AUTOSAR XML (schema 4-2-2)
package /RootP_ASWC_A28
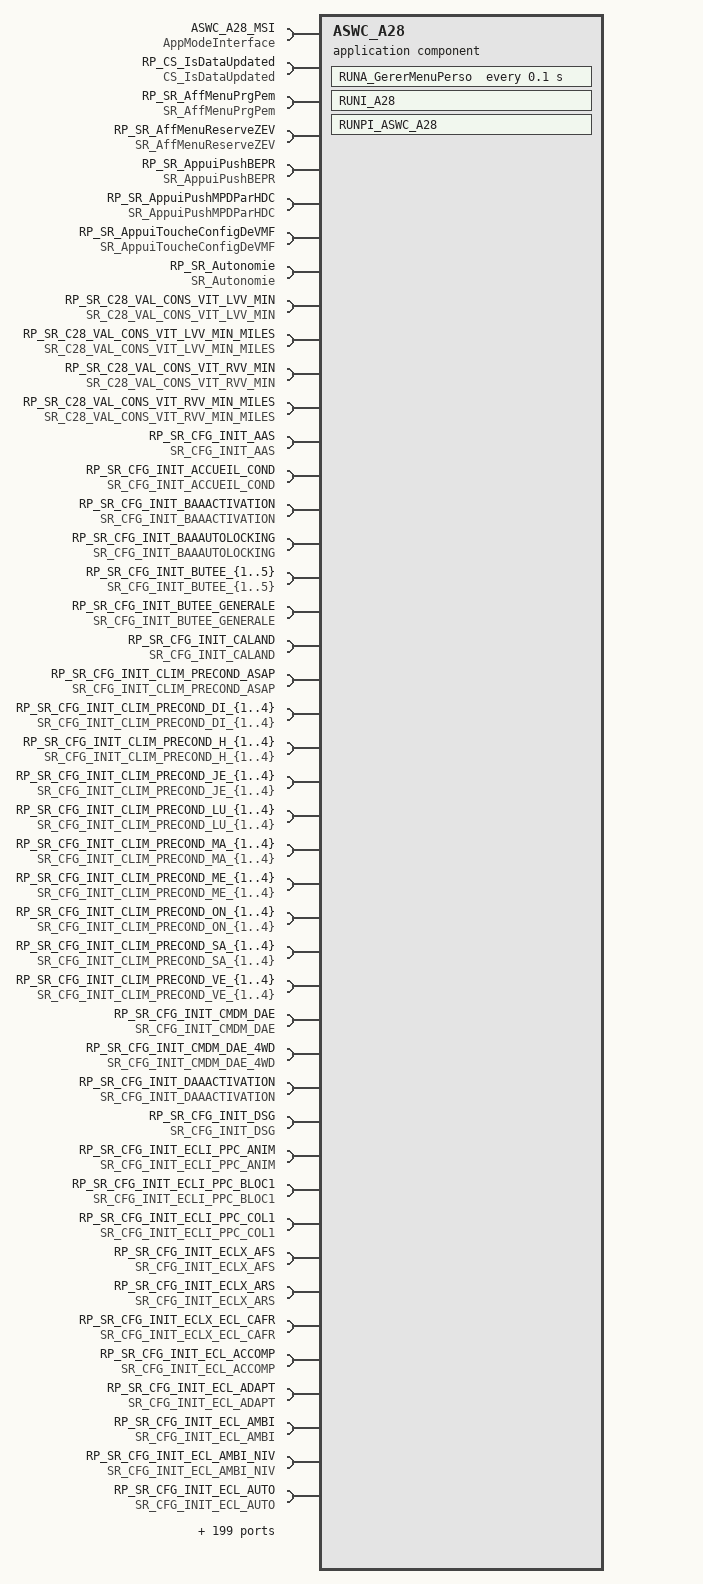
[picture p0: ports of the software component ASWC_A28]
  application sw component type ASWC_A28
    require port ASWC_A28_MSI: required-interface=AppModeInterface
    278 x provide/require port:
      PRP_SR_ButeeXvv{1..5}DeMenuPerso: nonqueued-receiver-com-spec{data-element=ButeeXvv{1..5}DeMenuPerso, handle-data-status=true, init-value=CONST_tBYTE_0:0}, provided-required-interface=SR_ButeeXvv{1..5}DeMenuPerso
      PRP_SR_DdeAccesJDADeVMF: nonqueued-receiver-com-spec{data-element=DdeAccesJDADeVMF, handle-data-status=true, init-value=CONST_tLOG_0:0}, provided-required-interface=SR_DdeAccesJDADeVMF
      PRP_SR_DdeAllumPlafDeVMF: nonqueued-receiver-com-spec{data-element=DdeAllumPlafDeVMF, handle-data-status=true, init-value=CONST_tLOG_0:0}, provided-required-interface=SR_DdeAllumPlafDeVMF
      PRP_SR_DdeBlackPanelDeVMF: nonqueued-receiver-com-spec{data-element=DdeBlackPanelDeVMF, handle-data-status=true, init-value=CONST_tLOG_0:0}, provided-required-interface=SR_DdeBlackPanelDeVMF
      PRP_SR_DdeCheckTcfg: nonqueued-receiver-com-spec{data-element=DdeCheckTcfg, handle-data-status=true, init-value=CONST_tLOG_0:0}, provided-required-interface=SR_DdeCheckTcfg
      PRP_SR_DdeColorisationCMBDeVMF: nonqueued-receiver-com-spec{data-element=DdeColorisationCMBDeVMF, handle-data-status=true, init-value=CONST_tLOG_0:0}, provided-required-interface=SR_DdeColorisationCMBDeVMF
      PRP_SR_DdeConfigToucheDeVMF: nonqueued-receiver-com-spec{data-element=DdeConfigToucheDeVMF, handle-data-status=true, init-value=CONST_tLOG_0:0}, provided-required-interface=SR_DdeConfigToucheDeVMF
      PRP_SR_DdePersoCMBDeVMF: nonqueued-receiver-com-spec{data-element=DdePersoCMBDeVMF, handle-data-status=true, init-value=CONST_tLOG_0:0}, provided-required-interface=SR_DdePersoCMBDeVMF
      PRP_SR_DispoDmdMenuPrecond: nonqueued-receiver-com-spec{data-element=DispoDmdMenuPrecond, handle-data-status=true, init-value=CONST_tWORD_0:0}, provided-required-interface=SR_DispoDmdMenuPrecond
      PRP_SR_DispoDmdMenuRecharge: nonqueued-receiver-com-spec{data-element=DispoDmdMenuRecharge, handle-data-status=true, init-value=CONST_tBYTE_0b01:0b01}, provided-required-interface=SR_DispoDmdMenuRecharge
      PRP_SR_DispoEtatMenuPrgPem: nonqueued-receiver-com-spec{data-element=DispoEtatMenuPrgPem, handle-data-status=true, init-value=CONST_tLOG_0:0}, provided-required-interface=SR_DispoEtatMenuPrgPem
      PRP_SR_DispoEtatMenuReserveZEV: nonqueued-receiver-com-spec{data-element=DispoEtatMenuReserveZEV, handle-data-status=true, init-value=CONST_tLOG_0:0}, provided-required-interface=SR_DispoEtatMenuReserveZEV
      PRP_SR_DmdMenuSelPrgDi: nonqueued-receiver-com-spec{data-element=DmdMenuSelPrgDi, handle-data-status=true, init-value=CONST_tLOG_0:0}, provided-required-interface=SR_DmdMenuSelPrgDi
      PRP_SR_DmdMenuSelPrgJe: nonqueued-receiver-com-spec{data-element=DmdMenuSelPrgJe, handle-data-status=true, init-value=CONST_tLOG_0:0}, provided-required-interface=SR_DmdMenuSelPrgJe
      PRP_SR_DmdMenuSelPrgLu: nonqueued-receiver-com-spec{data-element=DmdMenuSelPrgLu, handle-data-status=true, init-value=CONST_tLOG_0:0}, provided-required-interface=SR_DmdMenuSelPrgLu
      PRP_SR_DmdMenuSelPrgMa: nonqueued-receiver-com-spec{data-element=DmdMenuSelPrgMa, handle-data-status=true, init-value=CONST_tLOG_0:0}, provided-required-interface=SR_DmdMenuSelPrgMa
      PRP_SR_DmdMenuSelPrgMe: nonqueued-receiver-com-spec{data-element=DmdMenuSelPrgMe, handle-data-status=true, init-value=CONST_tLOG_0:0}, provided-required-interface=SR_DmdMenuSelPrgMe
      PRP_SR_DmdMenuSelPrgSa: nonqueued-receiver-com-spec{data-element=DmdMenuSelPrgSa, handle-data-status=true, init-value=CONST_tLOG_0:0}, provided-required-interface=SR_DmdMenuSelPrgSa
      PRP_SR_DmdMenuSelPrgVe: nonqueued-receiver-com-spec{data-element=DmdMenuSelPrgVe, handle-data-status=true, init-value=CONST_tLOG_0:0}, provided-required-interface=SR_DmdMenuSelPrgVe
      PRP_SR_DmdmCGEPVReserveZEV: nonqueued-receiver-com-spec{data-element=DmdmCGEPVReserveZEV, handle-data-status=true, init-value=CONST_tLOG_0:0}, provided-required-interface=SR_DmdmCGEPVReserveZEV
      PRP_SR_DmdmPrgHcEnd: nonqueued-receiver-com-spec{data-element=DmdmPrgHcEnd, handle-data-status=true, init-value=CONST_tDWORD_0:0}, provided-required-interface=SR_DmdmPrgHcEnd
      PRP_SR_DmdmPrgHcStart: nonqueued-receiver-com-spec{data-element=DmdmPrgHcStart, handle-data-status=true, init-value=CONST_tDWORD_0:0}, provided-required-interface=SR_DmdmPrgHcStart
      PRP_SR_DmdmPrgPemDi: nonqueued-receiver-com-spec{data-element=DmdmPrgPemDi, handle-data-status=true, init-value=CONST_tDWORD_0:0}, provided-required-interface=SR_DmdmPrgPemDi
      PRP_SR_DmdmPrgPemJe: nonqueued-receiver-com-spec{data-element=DmdmPrgPemJe, handle-data-status=true, init-value=CONST_tDWORD_0:0}, provided-required-interface=SR_DmdmPrgPemJe
      PRP_SR_DmdmPrgPemLu: nonqueued-receiver-com-spec{data-element=DmdmPrgPemLu, handle-data-status=true, init-value=CONST_tDWORD_0:0}, provided-required-interface=SR_DmdmPrgPemLu
      PRP_SR_DmdmPrgPemMa: nonqueued-receiver-com-spec{data-element=DmdmPrgPemMa, handle-data-status=true, init-value=CONST_tDWORD_0:0}, provided-required-interface=SR_DmdmPrgPemMa
      PRP_SR_DmdmPrgPemMe: nonqueued-receiver-com-spec{data-element=DmdmPrgPemMe, handle-data-status=true, init-value=CONST_tDWORD_0:0}, provided-required-interface=SR_DmdmPrgPemMe
      PRP_SR_DmdmPrgPemSa: nonqueued-receiver-com-spec{data-element=DmdmPrgPemSa, handle-data-status=true, init-value=CONST_tDWORD_0:0}, provided-required-interface=SR_DmdmPrgPemSa
      PRP_SR_DmdmPrgPemVe: nonqueued-receiver-com-spec{data-element=DmdmPrgPemVe, handle-data-status=true, init-value=CONST_tDWORD_0:0}, provided-required-interface=SR_DmdmPrgPemVe
      PRP_SR_EclAccompDeMenuPerso: nonqueued-receiver-com-spec{data-element=EclAccompDeMenuPerso, handle-data-status=true, init-value=CONST_t_cAccomp_0:0}, provided-required-interface=SR_EclAccompDeMenuPerso
      PRP_SR_EclDecondaDeMenuPerso: nonqueued-receiver-com-spec{data-element=EclDecondaDeMenuPerso, handle-data-status=true, init-value=CONST_t_cDeconda_0:0}, provided-required-interface=SR_EclDecondaDeMenuPerso
      PRP_SR_EtatMenuARCSensNiv: nonqueued-receiver-com-spec{data-element=EtatMenuARCSensNiv, handle-data-status=true, init-value=CONST_tBILOG_2:2}, provided-required-interface=SR_EtatMenuARCSensNiv
      PRP_SR_EtatMenuAccueilCond: nonqueued-receiver-com-spec{data-element=EtatMenuAccueilCond, handle-data-status=true, init-value=CONST_tLOG_0:0}, provided-required-interface=SR_EtatMenuAccueilCond
      PRP_SR_EtatMenuActButee{1..5}XVV: nonqueued-receiver-com-spec{data-element=EtatMenuActButee{1..5}XVV, handle-data-status=true, init-value=CONST_tLOG_0:0}, provided-required-interface=SR_EtatMenuActButee{1..5}XVV
      PRP_SR_EtatMenuActButeeGenXVV: nonqueued-receiver-com-spec{data-element=EtatMenuActButeeGenXVV, handle-data-status=true, init-value=CONST_tLOG_0:0}, provided-required-interface=SR_EtatMenuActButeeGenXVV
      PRP_SR_EtatMenuBAAActivation: nonqueued-receiver-com-spec{data-element=EtatMenuBAAActivation, handle-data-status=true, init-value=CONST_tLOG_0:0}, provided-required-interface=SR_EtatMenuBAAActivation
      PRP_SR_EtatMenuBAAAutolocking: nonqueued-receiver-com-spec{data-element=EtatMenuBAAAutolocking, handle-data-status=true, init-value=CONST_tLOG_0:0}, provided-required-interface=SR_EtatMenuBAAAutolocking
      PRP_SR_EtatMenuCLIM_PrecondASAP: nonqueued-receiver-com-spec{data-element=EtatMenuCLIM_PrecondASAP, handle-data-status=true, init-value=CONST_tLOG_0:0}, provided-required-interface=SR_EtatMenuCLIM_PrecondASAP
      PRP_SR_EtatMenuCLIM_PrecondDi{1..4}: nonqueued-receiver-com-spec{data-element=EtatMenuCLIM_PrecondDi{1..4}, handle-data-status=true, init-value=CONST_tLOG_0:0}, provided-required-interface=SR_EtatMenuCLIM_PrecondDi{1..4}
      PRP_SR_EtatMenuCLIM_PrecondH{1..4}: nonqueued-receiver-com-spec{data-element=EtatMenuCLIM_PrecondH{1..4}, handle-data-status=true, init-value=CONST_tWORD_0:0}, provided-required-interface=SR_EtatMenuCLIM_PrecondH{1..4}
      PRP_SR_EtatMenuCLIM_PrecondJe{1..4}: nonqueued-receiver-com-spec{data-element=EtatMenuCLIM_PrecondJe{1..4}, handle-data-status=true, init-value=CONST_tLOG_0:0}, provided-required-interface=SR_EtatMenuCLIM_PrecondJe{1..4}
      PRP_SR_EtatMenuCLIM_PrecondLu{1..4}: nonqueued-receiver-com-spec{data-element=EtatMenuCLIM_PrecondLu{1..4}, handle-data-status=true, init-value=CONST_tLOG_0:0}, provided-required-interface=SR_EtatMenuCLIM_PrecondLu{1..4}
      PRP_SR_EtatMenuCLIM_PrecondMa{1..4}: nonqueued-receiver-com-spec{data-element=EtatMenuCLIM_PrecondMa{1..4}, handle-data-status=true, init-value=CONST_tLOG_0:0}, provided-required-interface=SR_EtatMenuCLIM_PrecondMa{1..4}
      PRP_SR_EtatMenuCLIM_PrecondMe{1..4}: nonqueued-receiver-com-spec{data-element=EtatMenuCLIM_PrecondMe{1..4}, handle-data-status=true, init-value=CONST_tLOG_0:0}, provided-required-interface=SR_EtatMenuCLIM_PrecondMe{1..4}
      PRP_SR_EtatMenuCLIM_PrecondOn{1..4}: nonqueued-receiver-com-spec{data-element=EtatMenuCLIM_PrecondOn{1..4}, handle-data-status=true, init-value=CONST_tLOG_0:0}, provided-required-interface=SR_EtatMenuCLIM_PrecondOn{1..4}
      PRP_SR_EtatMenuCLIM_PrecondSa{1..4}: nonqueued-receiver-com-spec{data-element=EtatMenuCLIM_PrecondSa{1..4}, handle-data-status=true, init-value=CONST_tLOG_0:0}, provided-required-interface=SR_EtatMenuCLIM_PrecondSa{1..4}
      PRP_SR_EtatMenuCLIM_PrecondVe{1..4}: nonqueued-receiver-com-spec{data-element=EtatMenuCLIM_PrecondVe{1..4}, handle-data-status=true, init-value=CONST_tLOG_0:0}, provided-required-interface=SR_EtatMenuCLIM_PrecondVe{1..4}
      PRP_SR_EtatMenuDAAActivation: nonqueued-receiver-com-spec{data-element=EtatMenuDAAActivation, handle-data-status=true, init-value=CONST_tLOG_0:0}, provided-required-interface=SR_EtatMenuDAAActivation
      PRP_SR_EtatMenuDSG: nonqueued-receiver-com-spec{data-element=EtatMenuDSG, handle-data-status=true, init-value=CONST_tLOG_0:0}, provided-required-interface=SR_EtatMenuDSG
      PRP_SR_EtatMenuECLI_PPC_ANIM: nonqueued-receiver-com-spec{data-element=EtatMenuECLI_PPC_ANIM, handle-data-status=true, init-value=CONST_tBYTE_0:0}, provided-required-interface=SR_EtatMenuECLI_PPC_ANIM
      PRP_SR_EtatMenuECLI_PPC_BLOC1: nonqueued-receiver-com-spec{data-element=EtatMenuECLI_PPC_BLOC1, handle-data-status=true, init-value=CONST_tLOG_0:0}, provided-required-interface=SR_EtatMenuECLI_PPC_BLOC1
      PRP_SR_EtatMenuECLI_PPC_COL1: nonqueued-receiver-com-spec{data-element=EtatMenuECLI_PPC_COL1, handle-data-status=true, init-value=CONST_tBYTE_0:0}, provided-required-interface=SR_EtatMenuECLI_PPC_COL1
      PRP_SR_EtatMenuECLX_AFS: nonqueued-receiver-com-spec{data-element=EtatMenuECLX_AFS, handle-data-status=true, init-value=CONST_tLOG_0:0}, provided-required-interface=SR_EtatMenuECLX_AFS
      PRP_SR_EtatMenuECLX_ARS: nonqueued-receiver-com-spec{data-element=EtatMenuECLX_ARS, handle-data-status=true, init-value=CONST_tLOG_0:0}, provided-required-interface=SR_EtatMenuECLX_ARS
      PRP_SR_EtatMenuECLX_ECL_CAFR: nonqueued-receiver-com-spec{data-element=EtatMenuECLX_ECL_CAFR, handle-data-status=true, init-value=CONST_tLOG_0:0}, provided-required-interface=SR_EtatMenuECLX_ECL_CAFR
      PRP_SR_EtatMenuEclAccomp: nonqueued-receiver-com-spec{data-element=EtatMenuEclAccomp, handle-data-status=true, init-value=CONST_tLOG_0:0}, provided-required-interface=SR_EtatMenuEclAccomp
      PRP_SR_EtatMenuEclAccompTempo: nonqueued-receiver-com-spec{data-element=EtatMenuEclAccompTempo, handle-data-status=true, init-value=CONST_tBILOG_0:0}, provided-required-interface=SR_EtatMenuEclAccompTempo
      PRP_SR_EtatMenuEclAdapt: nonqueued-receiver-com-spec{data-element=EtatMenuEclAdapt, handle-data-status=true, init-value=CONST_tLOG_0:0}, provided-required-interface=SR_EtatMenuEclAdapt
      PRP_SR_EtatMenuEclAmbi: nonqueued-receiver-com-spec{data-element=EtatMenuEclAmbi, handle-data-status=true, init-value=CONST_tLOG_0:0}, provided-required-interface=SR_EtatMenuEclAmbi
      PRP_SR_EtatMenuEclAmbiNiv: nonqueued-receiver-com-spec{data-element=EtatMenuEclAmbiNiv, handle-data-status=true, init-value=CONST_tBYTE_6:6}, provided-required-interface=SR_EtatMenuEclAmbiNiv
      PRP_SR_EtatMenuEclAuto: nonqueued-receiver-com-spec{data-element=EtatMenuEclAuto, handle-data-status=true, init-value=CONST_tLOG_0:0}, provided-required-interface=SR_EtatMenuEclAuto
      PRP_SR_EtatMenuEclAutoroute: nonqueued-receiver-com-spec{data-element=EtatMenuEclAutoroute, handle-data-status=true, init-value=CONST_tLOG_0:0}, provided-required-interface=SR_EtatMenuEclAutoroute
      PRP_SR_EtatMenuEclCaland: nonqueued-receiver-com-spec{data-element=EtatMenuEclCaland, handle-data-status=true, init-value=CONST_tLOG_0:0}, provided-required-interface=SR_EtatMenuEclCaland
      PRP_SR_EtatMenuEclDeconda: nonqueued-receiver-com-spec{data-element=EtatMenuEclDeconda, handle-data-status=true, init-value=CONST_tLOG_0:0}, provided-required-interface=SR_EtatMenuEclDeconda
      PRP_SR_EtatMenuEclDecondaTempo: nonqueued-receiver-com-spec{data-element=EtatMenuEclDecondaTempo, handle-data-status=true, init-value=CONST_tBILOG_0:0}, provided-required-interface=SR_EtatMenuEclDecondaTempo
      PRP_SR_EtatMenuEssuiVitMar: nonqueued-receiver-com-spec{data-element=EtatMenuEssuiVitMar, handle-data-status=true, init-value=CONST_tLOG_0:0}, provided-required-interface=SR_EtatMenuEssuiVitMar
      PRP_SR_EtatMenuFARC: nonqueued-receiver-com-spec{data-element=EtatMenuFARC, handle-data-status=true, init-value=CONST_tLOG_0:0}, provided-required-interface=SR_EtatMenuFARC
      PRP_SR_EtatMenuFSEAuto: nonqueued-receiver-com-spec{data-element=EtatMenuFSEAuto, handle-data-status=true, init-value=CONST_tLOG_0:0}, provided-required-interface=SR_EtatMenuFSEAuto
      PRP_SR_EtatMenuFeuxDiurne: nonqueued-receiver-com-spec{data-element=EtatMenuFeuxDiurne, handle-data-status=true, init-value=CONST_tLOG_0:0}, provided-required-interface=SR_EtatMenuFeuxDiurne
      PRP_SR_EtatMenuGAV_AMLA: nonqueued-receiver-com-spec{data-element=EtatMenuGAV_AMLA, handle-data-status=true, init-value=CONST_tLOG_0:0}, provided-required-interface=SR_EtatMenuGAV_AMLA
      PRP_SR_EtatMenuILV: nonqueued-receiver-com-spec{data-element=EtatMenuILV, handle-data-status=true, init-value=CONST_tLOG_0:0}, provided-required-interface=SR_EtatMenuILV
      PRP_SR_EtatMenuILV_ETSR: nonqueued-receiver-com-spec{data-element=EtatMenuILV_ETSR, handle-data-status=true, init-value=CONST_tLOG_0:0}, provided-required-interface=SR_EtatMenuILV_ETSR
      PRP_SR_EtatMenuIMA: nonqueued-receiver-com-spec{data-element=EtatMenuIMA, handle-data-status=true, init-value=CONST_tLOG_0:0}, provided-required-interface=SR_EtatMenuIMA
      PRP_SR_EtatMenuINV_ADSD: nonqueued-receiver-com-spec{data-element=EtatMenuINV_ADSD, handle-data-status=true, init-value=CONST_tLOG_0:0}, provided-required-interface=SR_EtatMenuINV_ADSD
      PRP_SR_EtatMenuInfoParamDispo: nonqueued-receiver-com-spec{data-element=EtatMenuInfoParamDispo, handle-data-status=true, init-value=CONST_tLOG_0:0}, provided-required-interface=SR_EtatMenuInfoParamDispo
      PRP_SR_EtatMenuInfoUniteLangueDispo: nonqueued-receiver-com-spec{data-element=EtatMenuInfoUniteLangueDispo, handle-data-status=true, init-value=CONST_tLOG_0:0}, provided-required-interface=SR_EtatMenuInfoUniteLangueDispo
      PRP_SR_EtatMenuInfoVitLvvDispo: nonqueued-receiver-com-spec{data-element=EtatMenuInfoVitLvvDispo, handle-data-status=true, init-value=CONST_tLOG_0:0}, provided-required-interface=SR_EtatMenuInfoVitLvvDispo
      PRP_SR_EtatMenuInfoVitRvvDispo: nonqueued-receiver-com-spec{data-element=EtatMenuInfoVitRvvDispo, handle-data-status=true, init-value=CONST_tLOG_0:0}, provided-required-interface=SR_EtatMenuInfoVitRvvDispo
      PRP_SR_EtatMenuInfoXVVDispo: nonqueued-receiver-com-spec{data-element=EtatMenuInfoXVVDispo, handle-data-status=true, init-value=CONST_tLOG_0:0}, provided-required-interface=SR_EtatMenuInfoXVVDispo
      PRP_SR_EtatMenuLangueVehicule: nonqueued-receiver-com-spec{data-element=EtatMenuLangueVehicule, handle-data-status=true, init-value=CONST_tBYTE_0:0}, provided-required-interface=SR_EtatMenuLangueVehicule
      PRP_SR_EtatMenuMotoVolAr: nonqueued-receiver-com-spec{data-element=EtatMenuMotoVolAr, handle-data-status=true, init-value=CONST_tLOG_0:0}, provided-required-interface=SR_EtatMenuMotoVolAr
      PRP_SR_EtatMenuPRV_MODE: nonqueued-receiver-com-spec{data-element=EtatMenuPRV_MODE, handle-data-status=true, init-value=CONST_tBYTE_0:0}, provided-required-interface=SR_EtatMenuPRV_MODE
      PRP_SR_EtatMenuPresenceARC: nonqueued-receiver-com-spec{data-element=EtatMenuPresenceARC, handle-data-status=true, init-value=CONST_tLOG_0:0}, provided-required-interface=SR_EtatMenuPresenceARC
      PRP_SR_EtatMenuRTAB_EnergyRec: nonqueued-receiver-com-spec{data-element=EtatMenuRTAB_EnergyRec, handle-data-status=true, init-value=CONST_tBYTE_0b01:0b01}, provided-required-interface=SR_EtatMenuRTAB_EnergyRec
      PRP_SR_EtatMenuRTAB_RechargeHDeb: nonqueued-receiver-com-spec{data-element=EtatMenuRTAB_RechargeHDeb, handle-data-status=true, init-value=CONST_tWORD_0:0}, provided-required-interface=SR_EtatMenuRTAB_RechargeHDeb
      PRP_SR_EtatMenuRTAB_TypeRec: nonqueued-receiver-com-spec{data-element=EtatMenuRTAB_TypeRec, handle-data-status=true, init-value=CONST_tLOG_0:0}, provided-required-interface=SR_EtatMenuRTAB_TypeRec
      PRP_SR_EtatMenuReserveZEV: nonqueued-receiver-com-spec{data-element=EtatMenuReserveZEV, handle-data-status=true, init-value=CONST_tLOG_0:0}, provided-required-interface=SR_EtatMenuReserveZEV
      PRP_SR_EtatMenuSelReserveZEV: nonqueued-receiver-com-spec{data-element=EtatMenuSelReserveZEV, handle-data-status=true, init-value=CONST_tLOG_0:0}, provided-required-interface=SR_EtatMenuSelReserveZEV
      PRP_SR_EtatMenuSelecArriere: nonqueued-receiver-com-spec{data-element=EtatMenuSelecArriere, handle-data-status=true, init-value=CONST_tLOG_0:0}, provided-required-interface=SR_EtatMenuSelecArriere
      PRP_SR_EtatMenuSelecCabine: nonqueued-receiver-com-spec{data-element=EtatMenuSelecCabine, handle-data-status=true, init-value=CONST_tLOG_0:0}, provided-required-interface=SR_EtatMenuSelecCabine
      PRP_SR_EtatMenuSelecOuvPlip: nonqueued-receiver-com-spec{data-element=EtatMenuSelecOuvPlip, handle-data-status=true, init-value=CONST_tLOG_0:0}, provided-required-interface=SR_EtatMenuSelecOuvPlip
      PRP_SR_EtatMenuSonPoly: nonqueued-receiver-com-spec{data-element=EtatMenuSonPoly, handle-data-status=true, init-value=CONST_tBILOG_0:0}, provided-required-interface=SR_EtatMenuSonPoly
      PRP_SR_EtatMenuStatusAAS: nonqueued-receiver-com-spec{data-element=EtatMenuStatusAAS, handle-data-status=true, init-value=CONST_tLOG_0:0}, provided-required-interface=SR_EtatMenuStatusAAS
      PRP_SR_EtatMenuStatusSAM: nonqueued-receiver-com-spec{data-element=EtatMenuStatusSAM, handle-data-status=true, init-value=CONST_tLOG_0:0}, provided-required-interface=SR_EtatMenuStatusSAM
      PRP_SR_EtatMenuTCFG: nonqueued-receiver-com-spec{data-element=EtatMenuTCFG, handle-data-status=true, init-value=CONST_tBYTE_0:0}, provided-required-interface=SR_EtatMenuTCFG
      PRP_SR_EtatMenuUniteConso: nonqueued-receiver-com-spec{data-element=EtatMenuUniteConso, handle-data-status=true, init-value=CONST_tLOG_0:0}, provided-required-interface=SR_EtatMenuUniteConso
      PRP_SR_EtatMenuUniteDistance: nonqueued-receiver-com-spec{data-element=EtatMenuUniteDistance, handle-data-status=true, init-value=CONST_tLOG_0:0}, provided-required-interface=SR_EtatMenuUniteDistance
      PRP_SR_EtatMenuUniteTemperature: nonqueued-receiver-com-spec{data-element=EtatMenuUniteTemperature, handle-data-status=true, init-value=CONST_tLOG_0:0}, provided-required-interface=SR_EtatMenuUniteTemperature
      PRP_SR_EtatMenuUniteVolume: nonqueued-receiver-com-spec{data-element=EtatMenuUniteVolume, handle-data-status=true, init-value=CONST_tLOG_0:0}, provided-required-interface=SR_EtatMenuUniteVolume
      PRP_SR_EtatMenuVTOR_IRV: nonqueued-receiver-com-spec{data-element=EtatMenuVTOR_IRV, handle-data-status=true, init-value=CONST_tLOG_0:0}, provided-required-interface=SR_EtatMenuVTOR_IRV
      PRP_SR_EtatMenuVitLvv{1..6}: nonqueued-receiver-com-spec{data-element=EtatMenuVitLvv{1..6}, handle-data-status=true, init-value=CONST_tBYTE_0xFF:255}, provided-required-interface=SR_EtatMenuVitLvv{1..6}
      PRP_SR_EtatMenuVitRvv{1..6}: nonqueued-receiver-com-spec{data-element=EtatMenuVitRvv{1..6}, handle-data-status=true, init-value=CONST_tBYTE_0xFF:255}, provided-required-interface=SR_EtatMenuVitRvv{1..6}
      PRP_SR_EtatMenuVitesse{1..5}XVV: nonqueued-receiver-com-spec{data-element=EtatMenuVitesse{1..5}XVV, handle-data-status=true, init-value=CONST_tBYTE_0:0}, provided-required-interface=SR_EtatMenuVitesse{1..5}XVV
      PRP_SR_S360_Envoi: nonqueued-receiver-com-spec{data-element=S360_Envoi, handle-data-status=true, init-value=CONST_tBILOG_0:0}, provided-required-interface=SR_S360_Envoi
      PRP_SR_S360_OCTET_{1..8}: nonqueued-receiver-com-spec{data-element=S360_OCTET_{1..8}, handle-data-status=true, init-value=CONST_tBYTE_0:0}, provided-required-interface=SR_S360_OCTET_{1..8}
      PRP_SR_S3A0_Recu: nonqueued-receiver-com-spec{data-element=S3A0_Recu, handle-data-status=true, init-value=CONST_tBILOG_0:0}, provided-required-interface=SR_S3A0_Recu
      PRP_SR_SEC_AccueilDeMenuPerso: nonqueued-receiver-com-spec{data-element=SEC_AccueilDeMenuPerso, handle-data-status=true, init-value=CONST_tLOG_0:0}, provided-required-interface=SR_SEC_AccueilDeMenuPerso
      PRP_SR_SEC_ActButee{1..5}XVV: nonqueued-receiver-com-spec{data-element=SEC_ActButee{1..5}XVV, handle-data-status=true, init-value=CONST_tLOG_0:0}, provided-required-interface=SR_SEC_ActButee{1..5}XVV
      PRP_SR_SEC_ActButeeGenXVV: nonqueued-receiver-com-spec{data-element=SEC_ActButeeGenXVV, handle-data-status=true, init-value=CONST_tLOG_0:0}, provided-required-interface=SR_SEC_ActButeeGenXVV
      PRP_SR_SEC_ActivationARCDeMenuPerso: nonqueued-receiver-com-spec{data-element=SEC_ActivationARCDeMenuPerso, handle-data-status=true, init-value=CONST_tLOG_1:1}, provided-required-interface=SR_SEC_ActivationARCDeMenuPerso
      PRP_SR_SEC_BAAActivationDeMenuPerso: nonqueued-receiver-com-spec{data-element=SEC_BAAActivationDeMenuPerso, handle-data-status=true, init-value=CONST_tLOG_0:0}, provided-required-interface=SR_SEC_BAAActivationDeMenuPerso
      PRP_SR_SEC_BAAAutolockingDeMenuPerso: nonqueued-receiver-com-spec{data-element=SEC_BAAAutolockingDeMenuPerso, handle-data-status=true, init-value=CONST_tLOG_0:0}, provided-required-interface=SR_SEC_BAAAutolockingDeMenuPerso
      PRP_SR_SEC_CLIMPrecPrg{1..4}DeMenuPerso: nonqueued-receiver-com-spec{data-element=SEC_CLIMPrecPrg{1..4}DeMenuPerso, handle-data-status=true, init-value=CONST_tWORD_0:0}, provided-required-interface=SR_SEC_CLIMPrecPrg{1..4}DeMenuPerso
      PRP_SR_SEC_CLIMPrecSem{1..4}DeMenuPerso: nonqueued-receiver-com-spec{data-element=SEC_CLIMPrecSem{1..4}DeMenuPerso, handle-data-status=true, init-value=CONST_tBYTE_0:0}, provided-required-interface=SR_SEC_CLIMPrecSem{1..4}DeMenuPerso
      PRP_SR_SEC_CLIM_PrecASAPDeMenuPerso: nonqueued-receiver-com-spec{data-element=SEC_CLIM_PrecASAPDeMenuPerso, handle-data-status=true, init-value=CONST_tLOG_0:0}, provided-required-interface=SR_SEC_CLIM_PrecASAPDeMenuPerso
      PRP_SR_SEC_CLIM_PrecH{1..4}DeMenuPerso: nonqueued-receiver-com-spec{data-element=SEC_CLIM_PrecH{1..4}DeMenuPerso, handle-data-status=true, init-value=CONST_tWORD_0:0}, provided-required-interface=SR_SEC_CLIM_PrecH{1..4}DeMenuPerso
      PRP_SR_SEC_CLIM_PrecOn{1..4}DeMenuPerso: nonqueued-receiver-com-spec{data-element=SEC_CLIM_PrecOn{1..4}DeMenuPerso, handle-data-status=true, init-value=CONST_tLOG_0:0}, provided-required-interface=SR_SEC_CLIM_PrecOn{1..4}DeMenuPerso
      PRP_SR_SEC_CMDM_DAEDeMenuPerso: nonqueued-receiver-com-spec{data-element=SEC_CMDM_DAEDeMenuPerso, handle-data-status=true, init-value=CONST_t_cDAE_0:0}, provided-required-interface=SR_SEC_CMDM_DAEDeMenuPerso
      PRP_SR_SEC_CMDM_DAE_4WDDeMenuPerso: nonqueued-receiver-com-spec{data-element=SEC_CMDM_DAE_4WDDeMenuPerso, handle-data-status=true, init-value=CONST_t_cDAE_0:0}, provided-required-interface=SR_SEC_CMDM_DAE_4WDDeMenuPerso
      PRP_SR_SEC_DAAActivationDeMenuPerso: nonqueued-receiver-com-spec{data-element=SEC_DAAActivationDeMenuPerso, handle-data-status=true, init-value=CONST_tLOG_0:0}, provided-required-interface=SR_SEC_DAAActivationDeMenuPerso
      PRP_SR_SEC_DSGDeMenuPerso: nonqueued-receiver-com-spec{data-element=SEC_DSGDeMenuPerso, handle-data-status=true, init-value=CONST_tLOG_0:0}, provided-required-interface=SR_SEC_DSGDeMenuPerso
      PRP_SR_SEC_DecondaSelectDeMenuPerso: nonqueued-receiver-com-spec{data-element=SEC_DecondaSelectDeMenuPerso, handle-data-status=true, init-value=CONST_tLOG_0:0}, provided-required-interface=SR_SEC_DecondaSelectDeMenuPerso
      PRP_SR_SEC_ECLI_PPC_ANIMDeMenuPerso: nonqueued-receiver-com-spec{data-element=SEC_ECLI_PPC_ANIMDeMenuPerso, handle-data-status=true, init-value=CONST_tBYTE_0:0}, provided-required-interface=SR_SEC_ECLI_PPC_ANIMDeMenuPerso
      PRP_SR_SEC_ECLI_PPC_BLOC1DeMenuPerso: nonqueued-receiver-com-spec{data-element=SEC_ECLI_PPC_BLOC1DeMenuPerso, handle-data-status=true, init-value=CONST_tLOG_0:0}, provided-required-interface=SR_SEC_ECLI_PPC_BLOC1DeMenuPerso
      PRP_SR_SEC_ECLI_PPC_COL1DeMenuPerso: nonqueued-receiver-com-spec{data-element=SEC_ECLI_PPC_COL1DeMenuPerso, handle-data-status=true, init-value=CONST_tBYTE_1:1}, provided-required-interface=SR_SEC_ECLI_PPC_COL1DeMenuPerso
      PRP_SR_SEC_ECLX_ECL_CAFRDeMenuPerso: nonqueued-receiver-com-spec{data-element=SEC_ECLX_ECL_CAFRDeMenuPerso, handle-data-status=true, init-value=CONST_tLOG_0:0}, provided-required-interface=SR_SEC_ECLX_ECL_CAFRDeMenuPerso
      PRP_SR_SEC_EclAFSDeMenuPerso: nonqueued-receiver-com-spec{data-element=SEC_EclAFSDeMenuPerso, handle-data-status=true, init-value=CONST_tLOG_0:0}, provided-required-interface=SR_SEC_EclAFSDeMenuPerso
      PRP_SR_SEC_EclARSDeMenuPerso: nonqueued-receiver-com-spec{data-element=SEC_EclARSDeMenuPerso, handle-data-status=true, init-value=CONST_tLOG_0:0}, provided-required-interface=SR_SEC_EclARSDeMenuPerso
      PRP_SR_SEC_EclAccomp: nonqueued-receiver-com-spec{data-element=SEC_EclAccomp, handle-data-status=true, init-value=CONST_tLOG_0:0}, provided-required-interface=SR_SEC_EclAccomp
      PRP_SR_SEC_EclAccompTempo: nonqueued-receiver-com-spec{data-element=SEC_EclAccompTempo, handle-data-status=true, init-value=CONST_tBYTE_0:0}, provided-required-interface=SR_SEC_EclAccompTempo
      PRP_SR_SEC_EclAdaptDeMenuPerso: nonqueued-receiver-com-spec{data-element=SEC_EclAdaptDeMenuPerso, handle-data-status=true, init-value=CONST_tLOG_0:0}, provided-required-interface=SR_SEC_EclAdaptDeMenuPerso
      PRP_SR_SEC_EclAmbiDeMenuPerso: nonqueued-receiver-com-spec{data-element=SEC_EclAmbiDeMenuPerso, handle-data-status=true, init-value=CONST_tLOG_0:0}, provided-required-interface=SR_SEC_EclAmbiDeMenuPerso
      PRP_SR_SEC_EclAmbiNivDeMenuPerso: nonqueued-receiver-com-spec{data-element=SEC_EclAmbiNivDeMenuPerso, handle-data-status=true, init-value=CONST_tBYTE_3:3}, provided-required-interface=SR_SEC_EclAmbiNivDeMenuPerso
      PRP_SR_SEC_EclAutoDeMenuPerso: nonqueued-receiver-com-spec{data-element=SEC_EclAutoDeMenuPerso, handle-data-status=true, init-value=CONST_tLOG_0:0}, provided-required-interface=SR_SEC_EclAutoDeMenuPerso
      PRP_SR_SEC_EclAutorouteDeMenuPerso: nonqueued-receiver-com-spec{data-element=SEC_EclAutorouteDeMenuPerso, handle-data-status=true, init-value=CONST_tLOG_0:0}, provided-required-interface=SR_SEC_EclAutorouteDeMenuPerso
      PRP_SR_SEC_EclCalandDeMenuPerso: nonqueued-receiver-com-spec{data-element=SEC_EclCalandDeMenuPerso, handle-data-status=true, init-value=CONST_tBILOG_0:0}, provided-required-interface=SR_SEC_EclCalandDeMenuPerso
      PRP_SR_SEC_EclDeconda: nonqueued-receiver-com-spec{data-element=SEC_EclDeconda, handle-data-status=true, init-value=CONST_tLOG_0:0}, provided-required-interface=SR_SEC_EclDeconda
      PRP_SR_SEC_EclDecondaTempo: nonqueued-receiver-com-spec{data-element=SEC_EclDecondaTempo, handle-data-status=true, init-value=CONST_tBYTE_0:0}, provided-required-interface=SR_SEC_EclDecondaTempo
      PRP_SR_SEC_EssuiVitMarDeMenuPerso: nonqueued-receiver-com-spec{data-element=SEC_EssuiVitMarDeMenuPerso, handle-data-status=true, init-value=CONST_tLOG_0:0}, provided-required-interface=SR_SEC_EssuiVitMarDeMenuPerso
      PRP_SR_SEC_FARCDeMenuPerso: nonqueued-receiver-com-spec{data-element=SEC_FARCDeMenuPerso, handle-data-status=true, init-value=CONST_tLOG_0:0}, provided-required-interface=SR_SEC_FARCDeMenuPerso
      PRP_SR_SEC_FSEAutoDeMenuPerso: nonqueued-receiver-com-spec{data-element=SEC_FSEAutoDeMenuPerso, handle-data-status=true, init-value=CONST_tLOG_0:0}, provided-required-interface=SR_SEC_FSEAutoDeMenuPerso
      PRP_SR_SEC_FctToucheCfgDeMenuPerso: nonqueued-receiver-com-spec{data-element=SEC_FctToucheCfgDeMenuPerso, handle-data-status=true, init-value=CONST_t_cFTCG_0:0}, provided-required-interface=SR_SEC_FctToucheCfgDeMenuPerso
      PRP_SR_SEC_FeuxDiurneDeMenuPerso: nonqueued-receiver-com-spec{data-element=SEC_FeuxDiurneDeMenuPerso, handle-data-status=true, init-value=CONST_tLOG_0:0}, provided-required-interface=SR_SEC_FeuxDiurneDeMenuPerso
      PRP_SR_SEC_GAV_AMLADeMenuPerso: nonqueued-receiver-com-spec{data-element=SEC_GAV_AMLADeMenuPerso, handle-data-status=true, init-value=CONST_tLOG_0:0}, provided-required-interface=SR_SEC_GAV_AMLADeMenuPerso
      PRP_SR_SEC_ILVDeMenuPerso: nonqueued-receiver-com-spec{data-element=SEC_ILVDeMenuPerso, handle-data-status=true, init-value=CONST_tLOG_0:0}, provided-required-interface=SR_SEC_ILVDeMenuPerso
      PRP_SR_SEC_ILV_ETSRDeMenuPerso: nonqueued-receiver-com-spec{data-element=SEC_ILV_ETSRDeMenuPerso, handle-data-status=true, init-value=CONST_tLOG_0:0}, provided-required-interface=SR_SEC_ILV_ETSRDeMenuPerso
      PRP_SR_SEC_IMADeMenuPerso: nonqueued-receiver-com-spec{data-element=SEC_IMADeMenuPerso, handle-data-status=true, init-value=CONST_tLOG_0:0}, provided-required-interface=SR_SEC_IMADeMenuPerso
      PRP_SR_SEC_INV_ADSDDeMenuPerso: nonqueued-receiver-com-spec{data-element=SEC_INV_ADSDDeMenuPerso, handle-data-status=true, init-value=CONST_tLOG_0:0}, provided-required-interface=SR_SEC_INV_ADSDDeMenuPerso
      PRP_SR_SEC_InhibitionAASDeMenuPerso: nonqueued-receiver-com-spec{data-element=SEC_InhibitionAASDeMenuPerso, handle-data-status=true, init-value=CONST_tLOG_0:0}, provided-required-interface=SR_SEC_InhibitionAASDeMenuPerso
      PRP_SR_SEC_InhibitionSAMDeMenuPerso: nonqueued-receiver-com-spec{data-element=SEC_InhibitionSAMDeMenuPerso, handle-data-status=true, init-value=CONST_tLOG_0:0}, provided-required-interface=SR_SEC_InhibitionSAMDeMenuPerso
      PRP_SR_SEC_LangueVehicule: nonqueued-receiver-com-spec{data-element=SEC_LangueVehicule, handle-data-status=true, init-value=CONST_tBYTE_0:0}, provided-required-interface=SR_SEC_LangueVehicule
      PRP_SR_SEC_MotoVolArDeMenuPerso: nonqueued-receiver-com-spec{data-element=SEC_MotoVolArDeMenuPerso, handle-data-status=true, init-value=CONST_tLOG_0:0}, provided-required-interface=SR_SEC_MotoVolArDeMenuPerso
      PRP_SR_SEC_PRV_MODEDeMenuPerso: nonqueued-receiver-com-spec{data-element=SEC_PRV_MODEDeMenuPerso, handle-data-status=true, init-value=CONST_tBYTE_0:0}, provided-required-interface=SR_SEC_PRV_MODEDeMenuPerso
      PRP_SR_SEC_PrgPemDiDeMenuPerso: nonqueued-receiver-com-spec{data-element=SEC_PrgPemDiDeMenuPerso, handle-data-status=true, init-value=CONST_tDWORD_0:0}, provided-required-interface=SR_SEC_PrgPemDiDeMenuPerso
      PRP_SR_SEC_PrgPemJeDeMenuPerso: nonqueued-receiver-com-spec{data-element=SEC_PrgPemJeDeMenuPerso, handle-data-status=true, init-value=CONST_tDWORD_0:0}, provided-required-interface=SR_SEC_PrgPemJeDeMenuPerso
      PRP_SR_SEC_PrgPemLuDeMenuPerso: nonqueued-receiver-com-spec{data-element=SEC_PrgPemLuDeMenuPerso, handle-data-status=true, init-value=CONST_tDWORD_0:0}, provided-required-interface=SR_SEC_PrgPemLuDeMenuPerso
      PRP_SR_SEC_PrgPemMaDeMenuPerso: nonqueued-receiver-com-spec{data-element=SEC_PrgPemMaDeMenuPerso, handle-data-status=true, init-value=CONST_tDWORD_0:0}, provided-required-interface=SR_SEC_PrgPemMaDeMenuPerso
      PRP_SR_SEC_PrgPemMeDeMenuPerso: nonqueued-receiver-com-spec{data-element=SEC_PrgPemMeDeMenuPerso, handle-data-status=true, init-value=CONST_tDWORD_0:0}, provided-required-interface=SR_SEC_PrgPemMeDeMenuPerso
      PRP_SR_SEC_PrgPemSaDeMenuPerso: nonqueued-receiver-com-spec{data-element=SEC_PrgPemSaDeMenuPerso, handle-data-status=true, init-value=CONST_tDWORD_0:0}, provided-required-interface=SR_SEC_PrgPemSaDeMenuPerso
      PRP_SR_SEC_PrgPemVeDeMenuPerso: nonqueued-receiver-com-spec{data-element=SEC_PrgPemVeDeMenuPerso, handle-data-status=true, init-value=CONST_tDWORD_0:0}, provided-required-interface=SR_SEC_PrgPemVeDeMenuPerso
      PRP_SR_SEC_RTABDeMenuPerso: nonqueued-receiver-com-spec{data-element=SEC_RTABDeMenuPerso, handle-data-status=true, init-value=CONST_tLOG_0:0}, provided-required-interface=SR_SEC_RTABDeMenuPerso
      PRP_SR_SEC_RTAB_EnergyRecDeMenuPerso: nonqueued-receiver-com-spec{data-element=SEC_RTAB_EnergyRecDeMenuPerso, handle-data-status=true, init-value=CONST_tBYTE_0b01:0b01}, provided-required-interface=SR_SEC_RTAB_EnergyRecDeMenuPerso
      PRP_SR_SEC_RTAB_RecHDebDeMenuPerso: nonqueued-receiver-com-spec{data-element=SEC_RTAB_RecHDebDeMenuPerso, handle-data-status=true, init-value=CONST_tWORD_0:0}, provided-required-interface=SR_SEC_RTAB_RecHDebDeMenuPerso
      PRP_SR_SEC_RTAB_TypeRecDeMenuPerso: nonqueued-receiver-com-spec{data-element=SEC_RTAB_TypeRecDeMenuPerso, handle-data-status=true, init-value=CONST_tLOG_0:0}, provided-required-interface=SR_SEC_RTAB_TypeRecDeMenuPerso
      PRP_SR_SEC_ReserveZEVDeMenuPerso: nonqueued-receiver-com-spec{data-element=SEC_ReserveZEVDeMenuPerso, handle-data-status=true, init-value=CONST_tBYTE_0:0}, provided-required-interface=SR_SEC_ReserveZEVDeMenuPerso
      PRP_SR_SEC_SelReserveZEVDeMenuPerso: nonqueued-receiver-com-spec{data-element=SEC_SelReserveZEVDeMenuPerso, handle-data-status=true, init-value=CONST_tLOG_0:0}, provided-required-interface=SR_SEC_SelReserveZEVDeMenuPerso
      PRP_SR_SEC_SelectOuvARDeMenuPerso: nonqueued-receiver-com-spec{data-element=SEC_SelectOuvARDeMenuPerso, handle-data-status=true, init-value=CONST_tLOG_0:0}, provided-required-interface=SR_SEC_SelectOuvARDeMenuPerso
      PRP_SR_SEC_SensibiliteARCDeMenuPerso: nonqueued-receiver-com-spec{data-element=SEC_SensibiliteARCDeMenuPerso, handle-data-status=true, init-value=CONST_tQUARTET_3:3}, provided-required-interface=SR_SEC_SensibiliteARCDeMenuPerso
      PRP_SR_SEC_SonPolyphDeMenuPerso: nonqueued-receiver-com-spec{data-element=SEC_SonPolyphDeMenuPerso, handle-data-status=true, init-value=CONST_tBILOG_0:0}, provided-required-interface=SR_SEC_SonPolyphDeMenuPerso
      PRP_SR_SEC_UniteConso: nonqueued-receiver-com-spec{data-element=SEC_UniteConso, handle-data-status=true, init-value=CONST_tLOG_0:0}, provided-required-interface=SR_SEC_UniteConso
      PRP_SR_SEC_UniteDistance: nonqueued-receiver-com-spec{data-element=SEC_UniteDistance, handle-data-status=true, init-value=CONST_tLOG_0:0}, provided-required-interface=SR_SEC_UniteDistance
      PRP_SR_SEC_UniteTemperature: nonqueued-receiver-com-spec{data-element=SEC_UniteTemperature, handle-data-status=true, init-value=CONST_tLOG_0:0}, provided-required-interface=SR_SEC_UniteTemperature
      PRP_SR_SEC_UniteVolume: nonqueued-receiver-com-spec{data-element=SEC_UniteVolume, handle-data-status=true, init-value=CONST_tLOG_0:0}, provided-required-interface=SR_SEC_UniteVolume
      PRP_SR_SEC_VAM_ECS_MODEDeMenuPerso: nonqueued-receiver-com-spec{data-element=SEC_VAM_ECS_MODEDeMenuPerso, handle-data-status=true, init-value=CONST_tLOG_0:0}, provided-required-interface=SR_SEC_VAM_ECS_MODEDeMenuPerso
      PRP_SR_SEC_VTOR_IRVDeMenuPerso: nonqueued-receiver-com-spec{data-element=SEC_VTOR_IRVDeMenuPerso, handle-data-status=true, init-value=CONST_tLOG_0:0}, provided-required-interface=SR_SEC_VTOR_IRVDeMenuPerso
      PRP_SR_SEC_VitLvv1DeMenuPerso: nonqueued-receiver-com-spec{data-element=SEC_VitLvv1DeMenuPerso, handle-data-status=true, init-value=CONST_tBYTE_0:0}, provided-required-interface=SR_SEC_VitLvv1DeMenuPerso
      PRP_SR_SEC_VitLvv1MilesDeMenuPerso: nonqueued-receiver-com-spec{data-element=SEC_VitLvv1MilesDeMenuPerso, handle-data-status=true, init-value=CONST_tBYTE_0:0}, provided-required-interface=SR_SEC_VitLvv1MilesDeMenuPerso
      PRP_SR_SEC_VitLvv2DeMenuPerso: nonqueued-receiver-com-spec{data-element=SEC_VitLvv2DeMenuPerso, handle-data-status=true, init-value=CONST_tBYTE_0:0}, provided-required-interface=SR_SEC_VitLvv2DeMenuPerso
      PRP_SR_SEC_VitLvv2MilesDeMenuPerso: nonqueued-receiver-com-spec{data-element=SEC_VitLvv2MilesDeMenuPerso, handle-data-status=true, init-value=CONST_tBYTE_0:0}, provided-required-interface=SR_SEC_VitLvv2MilesDeMenuPerso
      PRP_SR_SEC_VitLvv3DeMenuPerso: nonqueued-receiver-com-spec{data-element=SEC_VitLvv3DeMenuPerso, handle-data-status=true, init-value=CONST_tBYTE_0:0}, provided-required-interface=SR_SEC_VitLvv3DeMenuPerso
      PRP_SR_SEC_VitLvv3MilesDeMenuPerso: nonqueued-receiver-com-spec{data-element=SEC_VitLvv3MilesDeMenuPerso, handle-data-status=true, init-value=CONST_tBYTE_0:0}, provided-required-interface=SR_SEC_VitLvv3MilesDeMenuPerso
      PRP_SR_SEC_VitLvv4DeMenuPerso: nonqueued-receiver-com-spec{data-element=SEC_VitLvv4DeMenuPerso, handle-data-status=true, init-value=CONST_tBYTE_0:0}, provided-required-interface=SR_SEC_VitLvv4DeMenuPerso
      PRP_SR_SEC_VitLvv4MilesDeMenuPerso: nonqueued-receiver-com-spec{data-element=SEC_VitLvv4MilesDeMenuPerso, handle-data-status=true, init-value=CONST_tBYTE_0:0}, provided-required-interface=SR_SEC_VitLvv4MilesDeMenuPerso
      PRP_SR_SEC_VitLvv5DeMenuPerso: nonqueued-receiver-com-spec{data-element=SEC_VitLvv5DeMenuPerso, handle-data-status=true, init-value=CONST_tBYTE_0:0}, provided-required-interface=SR_SEC_VitLvv5DeMenuPerso
      PRP_SR_SEC_VitLvv5MilesDeMenuPerso: nonqueued-receiver-com-spec{data-element=SEC_VitLvv5MilesDeMenuPerso, handle-data-status=true, init-value=CONST_tBYTE_0:0}, provided-required-interface=SR_SEC_VitLvv5MilesDeMenuPerso
      PRP_SR_SEC_VitLvv6DeMenuPerso: nonqueued-receiver-com-spec{data-element=SEC_VitLvv6DeMenuPerso, handle-data-status=true, init-value=CONST_tBYTE_0:0}, provided-required-interface=SR_SEC_VitLvv6DeMenuPerso
      PRP_SR_SEC_VitLvv6MilesDeMenuPerso: nonqueued-receiver-com-spec{data-element=SEC_VitLvv6MilesDeMenuPerso, handle-data-status=true, init-value=CONST_tBYTE_0:0}, provided-required-interface=SR_SEC_VitLvv6MilesDeMenuPerso
      PRP_SR_SEC_VitRvv1DeMenuPerso: nonqueued-receiver-com-spec{data-element=SEC_VitRvv1DeMenuPerso, handle-data-status=true, init-value=CONST_tBYTE_0:0}, provided-required-interface=SR_SEC_VitRvv1DeMenuPerso
      PRP_SR_SEC_VitRvv1MilesDeMenuPerso: nonqueued-receiver-com-spec{data-element=SEC_VitRvv1MilesDeMenuPerso, handle-data-status=true, init-value=CONST_tBYTE_0:0}, provided-required-interface=SR_SEC_VitRvv1MilesDeMenuPerso
      PRP_SR_SEC_VitRvv2DeMenuPerso: nonqueued-receiver-com-spec{data-element=SEC_VitRvv2DeMenuPerso, handle-data-status=true, init-value=CONST_tBYTE_0:0}, provided-required-interface=SR_SEC_VitRvv2DeMenuPerso
      PRP_SR_SEC_VitRvv2MilesDeMenuPerso: nonqueued-receiver-com-spec{data-element=SEC_VitRvv2MilesDeMenuPerso, handle-data-status=true, init-value=CONST_tBYTE_0:0}, provided-required-interface=SR_SEC_VitRvv2MilesDeMenuPerso
      PRP_SR_SEC_VitRvv3DeMenuPerso: nonqueued-receiver-com-spec{data-element=SEC_VitRvv3DeMenuPerso, handle-data-status=true, init-value=CONST_tBYTE_0:0}, provided-required-interface=SR_SEC_VitRvv3DeMenuPerso
      PRP_SR_SEC_VitRvv3MilesDeMenuPerso: nonqueued-receiver-com-spec{data-element=SEC_VitRvv3MilesDeMenuPerso, handle-data-status=true, init-value=CONST_tBYTE_0:0}, provided-required-interface=SR_SEC_VitRvv3MilesDeMenuPerso
      PRP_SR_SEC_VitRvv4DeMenuPerso: nonqueued-receiver-com-spec{data-element=SEC_VitRvv4DeMenuPerso, handle-data-status=true, init-value=CONST_tBYTE_0:0}, provided-required-interface=SR_SEC_VitRvv4DeMenuPerso
      PRP_SR_SEC_VitRvv4MilesDeMenuPerso: nonqueued-receiver-com-spec{data-element=SEC_VitRvv4MilesDeMenuPerso, handle-data-status=true, init-value=CONST_tBYTE_0:0}, provided-required-interface=SR_SEC_VitRvv4MilesDeMenuPerso
      PRP_SR_SEC_VitRvv5DeMenuPerso: nonqueued-receiver-com-spec{data-element=SEC_VitRvv5DeMenuPerso, handle-data-status=true, init-value=CONST_tBYTE_0:0}, provided-required-interface=SR_SEC_VitRvv5DeMenuPerso
      PRP_SR_SEC_VitRvv5MilesDeMenuPerso: nonqueued-receiver-com-spec{data-element=SEC_VitRvv5MilesDeMenuPerso, handle-data-status=true, init-value=CONST_tBYTE_0:0}, provided-required-interface=SR_SEC_VitRvv5MilesDeMenuPerso
      PRP_SR_SEC_VitRvv6DeMenuPerso: nonqueued-receiver-com-spec{data-element=SEC_VitRvv6DeMenuPerso, handle-data-status=true, init-value=CONST_tBYTE_0:0}, provided-required-interface=SR_SEC_VitRvv6DeMenuPerso
      PRP_SR_SEC_VitRvv6MilesDeMenuPerso: nonqueued-receiver-com-spec{data-element=SEC_VitRvv6MilesDeMenuPerso, handle-data-status=true, init-value=CONST_tBYTE_0:0}, provided-required-interface=SR_SEC_VitRvv6MilesDeMenuPerso
      PRP_SR_SEC_Vitesse{1..5}XVV: nonqueued-receiver-com-spec{data-element=SEC_Vitesse{1..5}XVV, handle-data-status=true, init-value=CONST_tBYTE_0:0}, provided-required-interface=SR_SEC_Vitesse{1..5}XVV
      PRP_SR_SEC_ZCSelectDeMenuPerso: nonqueued-receiver-com-spec{data-element=SEC_ZCSelectDeMenuPerso, handle-data-status=true, init-value=CONST_tLOG_0:0}, provided-required-interface=SR_SEC_ZCSelectDeMenuPerso
      PRP_SR_ToggleNewFrame15B: nonqueued-receiver-com-spec{data-element=ToggleNewFrame15B, handle-data-status=true, init-value=CONST_tLOG_0:0}, provided-required-interface=SR_ToggleNewFrame15B
    318 x require port:
      RP_CS_IsDataUpdated: required-interface=CS_IsDataUpdated
      RP_SR_AffMenuPrgPem: nonqueued-receiver-com-spec{data-element=AffMenuPrgPem, handle-data-status=true, init-value=CONST_tLOG_0:0}, required-interface=SR_AffMenuPrgPem
      RP_SR_AffMenuReserveZEV: nonqueued-receiver-com-spec{data-element=AffMenuReserveZEV, handle-data-status=true, init-value=CONST_tLOG_0:0}, required-interface=SR_AffMenuReserveZEV
      RP_SR_AppuiPushBEPR: nonqueued-receiver-com-spec{data-element=AppuiPushBEPR, handle-data-status=true, init-value=CONST_tLOG_0:0}, required-interface=SR_AppuiPushBEPR
      RP_SR_AppuiPushMPDParHDC: nonqueued-receiver-com-spec{data-element=AppuiPushMPDParHDC, handle-data-status=true, init-value=CONST_tLOG_0:0}, required-interface=SR_AppuiPushMPDParHDC
      RP_SR_AppuiToucheConfigDeVMF: nonqueued-receiver-com-spec{data-element=AppuiToucheConfigDeVMF, handle-data-status=true, init-value=CONST_tLOG_0:0}, required-interface=SR_AppuiToucheConfigDeVMF
      RP_SR_Autonomie: required-interface=SR_Autonomie
      RP_SR_C28_VAL_CONS_VIT_LVV_MIN: nonqueued-receiver-com-spec{data-element=C28_VAL_CONS_VIT_LVV_MIN, handle-data-status=true, init-value=CONST_t_C28_VAL_CONS_VIT_LVV_MIN_30:30}, required-interface=SR_C28_VAL_CONS_VIT_LVV_MIN
      RP_SR_C28_VAL_CONS_VIT_LVV_MIN_MILES: nonqueued-receiver-com-spec{data-element=C28_VAL_CONS_VIT_LVV_MIN_MILES, handle-data-status=true, init-value=CONST_t_C28_VAL_CONS_VIT_LVV_MIN_MILES_50:50}, required-interface=SR_C28_VAL_CONS_VIT_LVV_MIN_MILES
      RP_SR_C28_VAL_CONS_VIT_RVV_MIN: nonqueued-receiver-com-spec{data-element=C28_VAL_CONS_VIT_RVV_MIN, handle-data-status=true, init-value=CONST_t_C28_VAL_CONS_VIT_RVV_MIN_40:40}, required-interface=SR_C28_VAL_CONS_VIT_RVV_MIN
      RP_SR_C28_VAL_CONS_VIT_RVV_MIN_MILES: nonqueued-receiver-com-spec{data-element=C28_VAL_CONS_VIT_RVV_MIN_MILES, handle-data-status=true, init-value=CONST_t_C28_VAL_CONS_VIT_RVV_MIN_MILES_50:50}, required-interface=SR_C28_VAL_CONS_VIT_RVV_MIN_MILES
      RP_SR_CFG_INIT_AAS: nonqueued-receiver-com-spec{data-element=CFG_INIT_AAS, handle-data-status=true, init-value=CONST_tLOG_1:1}, required-interface=SR_CFG_INIT_AAS
      RP_SR_CFG_INIT_ACCUEIL_COND: nonqueued-receiver-com-spec{data-element=CFG_INIT_ACCUEIL_COND, handle-data-status=true, init-value=CONST_tLOG_1:1}, required-interface=SR_CFG_INIT_ACCUEIL_COND
      RP_SR_CFG_INIT_BAAACTIVATION: nonqueued-receiver-com-spec{data-element=CFG_INIT_BAAACTIVATION, handle-data-status=true, init-value=CONST_tLOG_1:1}, required-interface=SR_CFG_INIT_BAAACTIVATION
      RP_SR_CFG_INIT_BAAAUTOLOCKING: nonqueued-receiver-com-spec{data-element=CFG_INIT_BAAAUTOLOCKING, handle-data-status=true, init-value=CONST_tLOG_1:1}, required-interface=SR_CFG_INIT_BAAAUTOLOCKING
      RP_SR_CFG_INIT_BUTEE_{1..5}: nonqueued-receiver-com-spec{data-element=CFG_INIT_BUTEE_{1..5}, handle-data-status=true, init-value=CONST_tLOG_1:1}, required-interface=SR_CFG_INIT_BUTEE_{1..5}
      RP_SR_CFG_INIT_BUTEE_GENERALE: nonqueued-receiver-com-spec{data-element=CFG_INIT_BUTEE_GENERALE, handle-data-status=true, init-value=CONST_tLOG_0:0}, required-interface=SR_CFG_INIT_BUTEE_GENERALE
      RP_SR_CFG_INIT_CALAND: nonqueued-receiver-com-spec{data-element=CFG_INIT_CALAND, handle-data-status=true, init-value=CONST_tLOG_1:1}, required-interface=SR_CFG_INIT_CALAND
      RP_SR_CFG_INIT_CLIM_PRECOND_ASAP: nonqueued-receiver-com-spec{data-element=CFG_INIT_CLIM_PRECOND_ASAP, handle-data-status=true, init-value=CONST_tLOG_0:0}, required-interface=SR_CFG_INIT_CLIM_PRECOND_ASAP
      RP_SR_CFG_INIT_CLIM_PRECOND_DI_{1..4}: nonqueued-receiver-com-spec{data-element=CFG_INIT_CLIM_PRECOND_DI_{1..4}, handle-data-status=true, init-value=CONST_tLOG_0:0}, required-interface=SR_CFG_INIT_CLIM_PRECOND_DI_{1..4}
      RP_SR_CFG_INIT_CLIM_PRECOND_H_{1..4}: nonqueued-receiver-com-spec{data-element=CFG_INIT_CLIM_PRECOND_H_{1..4}, handle-data-status=true, init-value=CONST_tWORD_0:0}, required-interface=SR_CFG_INIT_CLIM_PRECOND_H_{1..4}
      RP_SR_CFG_INIT_CLIM_PRECOND_JE_{1..4}: nonqueued-receiver-com-spec{data-element=CFG_INIT_CLIM_PRECOND_JE_{1..4}, handle-data-status=true, init-value=CONST_tLOG_0:0}, required-interface=SR_CFG_INIT_CLIM_PRECOND_JE_{1..4}
      RP_SR_CFG_INIT_CLIM_PRECOND_LU_{1..4}: nonqueued-receiver-com-spec{data-element=CFG_INIT_CLIM_PRECOND_LU_{1..4}, handle-data-status=true, init-value=CONST_tLOG_0:0}, required-interface=SR_CFG_INIT_CLIM_PRECOND_LU_{1..4}
      RP_SR_CFG_INIT_CLIM_PRECOND_MA_{1..4}: nonqueued-receiver-com-spec{data-element=CFG_INIT_CLIM_PRECOND_MA_{1..4}, handle-data-status=true, init-value=CONST_tLOG_0:0}, required-interface=SR_CFG_INIT_CLIM_PRECOND_MA_{1..4}
      RP_SR_CFG_INIT_CLIM_PRECOND_ME_{1..4}: nonqueued-receiver-com-spec{data-element=CFG_INIT_CLIM_PRECOND_ME_{1..4}, handle-data-status=true, init-value=CONST_tLOG_0:0}, required-interface=SR_CFG_INIT_CLIM_PRECOND_ME_{1..4}
      RP_SR_CFG_INIT_CLIM_PRECOND_ON_{1..4}: nonqueued-receiver-com-spec{data-element=CFG_INIT_CLIM_PRECOND_ON_{1..4}, handle-data-status=true, init-value=CONST_tLOG_0:0}, required-interface=SR_CFG_INIT_CLIM_PRECOND_ON_{1..4}
      RP_SR_CFG_INIT_CLIM_PRECOND_SA_{1..4}: nonqueued-receiver-com-spec{data-element=CFG_INIT_CLIM_PRECOND_SA_{1..4}, handle-data-status=true, init-value=CONST_tLOG_0:0}, required-interface=SR_CFG_INIT_CLIM_PRECOND_SA_{1..4}
      RP_SR_CFG_INIT_CLIM_PRECOND_VE_{1..4}: nonqueued-receiver-com-spec{data-element=CFG_INIT_CLIM_PRECOND_VE_{1..4}, handle-data-status=true, init-value=CONST_tLOG_0:0}, required-interface=SR_CFG_INIT_CLIM_PRECOND_VE_{1..4}
      RP_SR_CFG_INIT_CMDM_DAE: nonqueued-receiver-com-spec{data-element=CFG_INIT_CMDM_DAE, handle-data-status=true, init-value=CONST_tLOG_1:1}, required-interface=SR_CFG_INIT_CMDM_DAE
      RP_SR_CFG_INIT_CMDM_DAE_4WD: nonqueued-receiver-com-spec{data-element=CFG_INIT_CMDM_DAE_4WD, handle-data-status=true, init-value=CONST_tLOG_1:1}, required-interface=SR_CFG_INIT_CMDM_DAE_4WD
      RP_SR_CFG_INIT_DAAACTIVATION: nonqueued-receiver-com-spec{data-element=CFG_INIT_DAAACTIVATION, handle-data-status=true, init-value=CONST_tLOG_1:1}, required-interface=SR_CFG_INIT_DAAACTIVATION
      RP_SR_CFG_INIT_DSG: nonqueued-receiver-com-spec{data-element=CFG_INIT_DSG, handle-data-status=true, init-value=CONST_tLOG_0:0}, required-interface=SR_CFG_INIT_DSG
      RP_SR_CFG_INIT_ECLI_PPC_ANIM: nonqueued-receiver-com-spec{data-element=CFG_INIT_ECLI_PPC_ANIM, handle-data-status=true, init-value=CONST_tBYTE_1:1}, required-interface=SR_CFG_INIT_ECLI_PPC_ANIM
      RP_SR_CFG_INIT_ECLI_PPC_BLOC1: nonqueued-receiver-com-spec{data-element=CFG_INIT_ECLI_PPC_BLOC1, handle-data-status=true, init-value=CONST_tLOG_1:1}, required-interface=SR_CFG_INIT_ECLI_PPC_BLOC1
      RP_SR_CFG_INIT_ECLI_PPC_COL1: nonqueued-receiver-com-spec{data-element=CFG_INIT_ECLI_PPC_COL1, handle-data-status=true, init-value=CONST_tBYTE_1:1}, required-interface=SR_CFG_INIT_ECLI_PPC_COL1
      RP_SR_CFG_INIT_ECLX_AFS: nonqueued-receiver-com-spec{data-element=CFG_INIT_ECLX_AFS, handle-data-status=true, init-value=CONST_tLOG_0:0}, required-interface=SR_CFG_INIT_ECLX_AFS
      RP_SR_CFG_INIT_ECLX_ARS: nonqueued-receiver-com-spec{data-element=CFG_INIT_ECLX_ARS, handle-data-status=true, init-value=CONST_tLOG_0:0}, required-interface=SR_CFG_INIT_ECLX_ARS
      RP_SR_CFG_INIT_ECLX_ECL_CAFR: nonqueued-receiver-com-spec{data-element=CFG_INIT_ECLX_ECL_CAFR, handle-data-status=true, init-value=CONST_tLOG_1:1}, required-interface=SR_CFG_INIT_ECLX_ECL_CAFR
      RP_SR_CFG_INIT_ECL_ACCOMP: nonqueued-receiver-com-spec{data-element=CFG_INIT_ECL_ACCOMP, handle-data-status=true, init-value=CONST_tLOG_0:0}, required-interface=SR_CFG_INIT_ECL_ACCOMP
      RP_SR_CFG_INIT_ECL_ADAPT: nonqueued-receiver-com-spec{data-element=CFG_INIT_ECL_ADAPT, handle-data-status=true, init-value=CONST_tLOG_1:1}, required-interface=SR_CFG_INIT_ECL_ADAPT
      RP_SR_CFG_INIT_ECL_AMBI: nonqueued-receiver-com-spec{data-element=CFG_INIT_ECL_AMBI, handle-data-status=true, init-value=CONST_tLOG_1:1}, required-interface=SR_CFG_INIT_ECL_AMBI
      RP_SR_CFG_INIT_ECL_AMBI_NIV: nonqueued-receiver-com-spec{data-element=CFG_INIT_ECL_AMBI_NIV, handle-data-status=true, init-value=6}, required-interface=SR_CFG_INIT_ECL_AMBI_NIV
      RP_SR_CFG_INIT_ECL_AUTO: nonqueued-receiver-com-spec{data-element=CFG_INIT_ECL_AUTO, handle-data-status=true, init-value=CONST_tLOG_0:0}, required-interface=SR_CFG_INIT_ECL_AUTO
      RP_SR_CFG_INIT_ECL_AUTOROUTE: nonqueued-receiver-com-spec{data-element=CFG_INIT_ECL_AUTOROUTE, handle-data-status=true, init-value=CONST_tLOG_1:1}, required-interface=SR_CFG_INIT_ECL_AUTOROUTE
      RP_SR_CFG_INIT_ECL_DECONDA: nonqueued-receiver-com-spec{data-element=CFG_INIT_ECL_DECONDA, handle-data-status=true, init-value=CONST_tLOG_0:0}, required-interface=SR_CFG_INIT_ECL_DECONDA
      RP_SR_CFG_INIT_ECL_FEUX_DIURNES: nonqueued-receiver-com-spec{data-element=CFG_INIT_ECL_FEUX_DIURNES, handle-data-status=true, init-value=CONST_tLOG_0:0}, required-interface=SR_CFG_INIT_ECL_FEUX_DIURNES
      RP_SR_CFG_INIT_ESSUIE_VIT_MAR: nonqueued-receiver-com-spec{data-element=CFG_INIT_ESSUIE_VIT_MAR, handle-data-status=true, init-value=CONST_tLOG_0:0}, required-interface=SR_CFG_INIT_ESSUIE_VIT_MAR
      RP_SR_CFG_INIT_FARC: nonqueued-receiver-com-spec{data-element=CFG_INIT_FARC, handle-data-status=true, init-value=CONST_tLOG_0:0}, required-interface=SR_CFG_INIT_FARC
      RP_SR_CFG_INIT_FSE_AUTO: nonqueued-receiver-com-spec{data-element=CFG_INIT_FSE_AUTO, handle-data-status=true, init-value=CONST_tLOG_1:1}, required-interface=SR_CFG_INIT_FSE_AUTO
      RP_SR_CFG_INIT_GAV_AMLA: nonqueued-receiver-com-spec{data-element=CFG_INIT_GAV_AMLA, handle-data-status=true, init-value=CONST_tLOG_0:0}, required-interface=SR_CFG_INIT_GAV_AMLA
      RP_SR_CFG_INIT_HARMONIE_SON: nonqueued-receiver-com-spec{data-element=CFG_INIT_HARMONIE_SON, handle-data-status=true, init-value=0}, required-interface=SR_CFG_INIT_HARMONIE_SON
      RP_SR_CFG_INIT_ILV: nonqueued-receiver-com-spec{data-element=CFG_INIT_ILV, handle-data-status=true, init-value=CONST_tLOG_1:1}, required-interface=SR_CFG_INIT_ILV
      RP_SR_CFG_INIT_ILV_ETSR: nonqueued-receiver-com-spec{data-element=CFG_INIT_ILV_ETSR, handle-data-status=true, init-value=CONST_tLOG_1:1}, required-interface=SR_CFG_INIT_ILV_ETSR
      RP_SR_CFG_INIT_IMA: nonqueued-receiver-com-spec{data-element=CFG_INIT_IMA, handle-data-status=true, init-value=CONST_tLOG_1:1}, required-interface=SR_CFG_INIT_IMA
      RP_SR_CFG_INIT_INV_ADSD: nonqueued-receiver-com-spec{data-element=CFG_INIT_INV_ADSD, handle-data-status=true, init-value=CONST_tLOG_1:1}, required-interface=SR_CFG_INIT_INV_ADSD
      RP_SR_CFG_INIT_LANGUE_VHL: nonqueued-receiver-com-spec{data-element=CFG_INIT_LANGUE_VHL, handle-data-status=true, init-value=0}, required-interface=SR_CFG_INIT_LANGUE_VHL
      RP_SR_CFG_INIT_MENU_HC_END: nonqueued-receiver-com-spec{data-element=CFG_INIT_MENU_HC_END, handle-data-status=true, init-value=420}, required-interface=SR_CFG_INIT_MENU_HC_END
      RP_SR_CFG_INIT_MENU_HC_START: nonqueued-receiver-com-spec{data-element=CFG_INIT_MENU_HC_START, handle-data-status=true, init-value=1380}, required-interface=SR_CFG_INIT_MENU_HC_START
      RP_SR_CFG_INIT_MENU_PRG_PEM_DI: nonqueued-receiver-com-spec{data-element=CFG_INIT_MENU_PRG_PEM_DI, handle-data-status=true, init-value=480}, required-interface=SR_CFG_INIT_MENU_PRG_PEM_DI
      RP_SR_CFG_INIT_MENU_PRG_PEM_JE: nonqueued-receiver-com-spec{data-element=CFG_INIT_MENU_PRG_PEM_JE, handle-data-status=true, init-value=480}, required-interface=SR_CFG_INIT_MENU_PRG_PEM_JE
      RP_SR_CFG_INIT_MENU_PRG_PEM_LU: nonqueued-receiver-com-spec{data-element=CFG_INIT_MENU_PRG_PEM_LU, handle-data-status=true, init-value=480}, required-interface=SR_CFG_INIT_MENU_PRG_PEM_LU
      RP_SR_CFG_INIT_MENU_PRG_PEM_MA: nonqueued-receiver-com-spec{data-element=CFG_INIT_MENU_PRG_PEM_MA, handle-data-status=true, init-value=480}, required-interface=SR_CFG_INIT_MENU_PRG_PEM_MA
      RP_SR_CFG_INIT_MENU_PRG_PEM_ME: nonqueued-receiver-com-spec{data-element=CFG_INIT_MENU_PRG_PEM_ME, handle-data-status=true, init-value=480}, required-interface=SR_CFG_INIT_MENU_PRG_PEM_ME
      RP_SR_CFG_INIT_MENU_PRG_PEM_SA: nonqueued-receiver-com-spec{data-element=CFG_INIT_MENU_PRG_PEM_SA, handle-data-status=true, init-value=480}, required-interface=SR_CFG_INIT_MENU_PRG_PEM_SA
      RP_SR_CFG_INIT_MENU_PRG_PEM_VE: nonqueued-receiver-com-spec{data-element=CFG_INIT_MENU_PRG_PEM_VE, handle-data-status=true, init-value=480}, required-interface=SR_CFG_INIT_MENU_PRG_PEM_VE
      RP_SR_CFG_INIT_MENU_SEL_HC: nonqueued-receiver-com-spec{data-element=CFG_INIT_MENU_SEL_HC, handle-data-status=true, init-value=CONST_tLOG_1:1}, required-interface=SR_CFG_INIT_MENU_SEL_HC
      RP_SR_CFG_INIT_MENU_SEL_PRG_PEM_DI: nonqueued-receiver-com-spec{data-element=CFG_INIT_MENU_SEL_PRG_PEM_DI, handle-data-status=true, init-value=CONST_tLOG_1:1}, required-interface=SR_CFG_INIT_MENU_SEL_PRG_PEM_DI
      RP_SR_CFG_INIT_MENU_SEL_PRG_PEM_JE: nonqueued-receiver-com-spec{data-element=CFG_INIT_MENU_SEL_PRG_PEM_JE, handle-data-status=true, init-value=CONST_tLOG_1:1}, required-interface=SR_CFG_INIT_MENU_SEL_PRG_PEM_JE
      RP_SR_CFG_INIT_MENU_SEL_PRG_PEM_LU: nonqueued-receiver-com-spec{data-element=CFG_INIT_MENU_SEL_PRG_PEM_LU, handle-data-status=true, init-value=CONST_tLOG_1:1}, required-interface=SR_CFG_INIT_MENU_SEL_PRG_PEM_LU
      RP_SR_CFG_INIT_MENU_SEL_PRG_PEM_MA: nonqueued-receiver-com-spec{data-element=CFG_INIT_MENU_SEL_PRG_PEM_MA, handle-data-status=true, init-value=CONST_tLOG_1:1}, required-interface=SR_CFG_INIT_MENU_SEL_PRG_PEM_MA
      RP_SR_CFG_INIT_MENU_SEL_PRG_PEM_ME: nonqueued-receiver-com-spec{data-element=CFG_INIT_MENU_SEL_PRG_PEM_ME, handle-data-status=true, init-value=CONST_tLOG_1:1}, required-interface=SR_CFG_INIT_MENU_SEL_PRG_PEM_ME
      RP_SR_CFG_INIT_MENU_SEL_PRG_PEM_SA: nonqueued-receiver-com-spec{data-element=CFG_INIT_MENU_SEL_PRG_PEM_SA, handle-data-status=true, init-value=CONST_tLOG_1:1}, required-interface=SR_CFG_INIT_MENU_SEL_PRG_PEM_SA
      RP_SR_CFG_INIT_MENU_SEL_PRG_PEM_VE: nonqueued-receiver-com-spec{data-element=CFG_INIT_MENU_SEL_PRG_PEM_VE, handle-data-status=true, init-value=CONST_tLOG_1:1}, required-interface=SR_CFG_INIT_MENU_SEL_PRG_PEM_VE
      RP_SR_CFG_INIT_MOTOR_VOLET: nonqueued-receiver-com-spec{data-element=CFG_INIT_MOTOR_VOLET, handle-data-status=true, init-value=CONST_tLOG_0:0}, required-interface=SR_CFG_INIT_MOTOR_VOLET
      RP_SR_CFG_INIT_PRESENCE_ARC: nonqueued-receiver-com-spec{data-element=CFG_INIT_PRESENCE_ARC, handle-data-status=true, init-value=CONST_tLOG_1:1}, required-interface=SR_CFG_INIT_PRESENCE_ARC
      RP_SR_CFG_INIT_PRV_MODE: nonqueued-receiver-com-spec{data-element=CFG_INIT_PRV_MODE, handle-data-status=true, init-value=0}, required-interface=SR_CFG_INIT_PRV_MODE
      RP_SR_CFG_INIT_RESERVE_ZEV: nonqueued-receiver-com-spec{data-element=CFG_INIT_RESERVE_ZEV, handle-data-status=true, init-value=2}, required-interface=SR_CFG_INIT_RESERVE_ZEV
      RP_SR_CFG_INIT_RTAB: nonqueued-receiver-com-spec{data-element=CFG_INIT_RTAB, handle-data-status=true, init-value=CONST_tLOG_1:1}, required-interface=SR_CFG_INIT_RTAB
      RP_SR_CFG_INIT_RTAB_ENERGY_REC: nonqueued-receiver-com-spec{data-element=CFG_INIT_RTAB_ENERGY_REC, handle-data-status=true, init-value=CONST_tBYTE_0:0}, required-interface=SR_CFG_INIT_RTAB_ENERGY_REC
      RP_SR_CFG_INIT_RTAB_RECHARGE: nonqueued-receiver-com-spec{data-element=CFG_INIT_RTAB_RECHARGE, handle-data-status=true, init-value=CONST_tLOG_0:0}, required-interface=SR_CFG_INIT_RTAB_RECHARGE
      RP_SR_CFG_INIT_RTAB_RECHARGE_H_DEB: nonqueued-receiver-com-spec{data-element=CFG_INIT_RTAB_RECHARGE_H_DEB, handle-data-status=true, init-value=CONST_tDWORD_0:0}, required-interface=SR_CFG_INIT_RTAB_RECHARGE_H_DEB
      RP_SR_CFG_INIT_RTAB_TYPE_REC: nonqueued-receiver-com-spec{data-element=CFG_INIT_RTAB_TYPE_REC, handle-data-status=true, init-value=CONST_tLOG_0:0}, required-interface=SR_CFG_INIT_RTAB_TYPE_REC
      RP_SR_CFG_INIT_SAM: nonqueued-receiver-com-spec{data-element=CFG_INIT_SAM, handle-data-status=true, init-value=CONST_tLOG_1:1}, required-interface=SR_CFG_INIT_SAM
      RP_SR_CFG_INIT_SELECTIVITE_CAB_ZC: nonqueued-receiver-com-spec{data-element=CFG_INIT_SELECTIVITE_CAB_ZC, handle-data-status=true, init-value=CONST_tLOG_0:0}, required-interface=SR_CFG_INIT_SELECTIVITE_CAB_ZC
      RP_SR_CFG_INIT_SELECTIVITE_COND: nonqueued-receiver-com-spec{data-element=CFG_INIT_SELECTIVITE_COND, handle-data-status=true, init-value=CONST_tLOG_0:0}, required-interface=SR_CFG_INIT_SELECTIVITE_COND
      RP_SR_CFG_INIT_SELECTIVITE_OUV_AR: nonqueued-receiver-com-spec{data-element=CFG_INIT_SELECTIVITE_OUV_AR, handle-data-status=true, init-value=CONST_tLOG_0:0}, required-interface=SR_CFG_INIT_SELECTIVITE_OUV_AR
      RP_SR_CFG_INIT_SEL_RESERVE_ZEV: nonqueued-receiver-com-spec{data-element=CFG_INIT_SEL_RESERVE_ZEV, handle-data-status=true, init-value=CONST_tLOG_1:1}, required-interface=SR_CFG_INIT_SEL_RESERVE_ZEV
      RP_SR_CFG_INIT_SENS_ARC_NIV: nonqueued-receiver-com-spec{data-element=CFG_INIT_SENS_ARC_NIV, handle-data-status=true, init-value=2}, required-interface=SR_CFG_INIT_SENS_ARC_NIV
      RP_SR_CFG_INIT_TCFG: nonqueued-receiver-com-spec{data-element=CFG_INIT_TCFG, handle-data-status=true, init-value=4}, required-interface=SR_CFG_INIT_TCFG
      RP_SR_CFG_INIT_TEMPO_ACCOMP: nonqueued-receiver-com-spec{data-element=CFG_INIT_TEMPO_ACCOMP, handle-data-status=true, init-value=1}, required-interface=SR_CFG_INIT_TEMPO_ACCOMP
      RP_SR_CFG_INIT_TEMPO_DECONDA: nonqueued-receiver-com-spec{data-element=CFG_INIT_TEMPO_DECONDA, handle-data-status=true, init-value=1}, required-interface=SR_CFG_INIT_TEMPO_DECONDA
      RP_SR_CFG_INIT_UNITE_CONSO: nonqueued-receiver-com-spec{data-element=CFG_INIT_UNITE_CONSO, handle-data-status=true, init-value=CONST_tLOG_0:0}, required-interface=SR_CFG_INIT_UNITE_CONSO
      RP_SR_CFG_INIT_UNITE_DISTANCE: nonqueued-receiver-com-spec{data-element=CFG_INIT_UNITE_DISTANCE, handle-data-status=true, init-value=CONST_tLOG_0:0}, required-interface=SR_CFG_INIT_UNITE_DISTANCE
      RP_SR_CFG_INIT_UNITE_TEMP: nonqueued-receiver-com-spec{data-element=CFG_INIT_UNITE_TEMP, handle-data-status=true, init-value=CONST_tLOG_0:0}, required-interface=SR_CFG_INIT_UNITE_TEMP
      RP_SR_CFG_INIT_UNITE_VOLUME: nonqueued-receiver-com-spec{data-element=CFG_INIT_UNITE_VOLUME, handle-data-status=true, init-value=CONST_tLOG_0:0}, required-interface=SR_CFG_INIT_UNITE_VOLUME
      RP_SR_CFG_INIT_VAM_ECS_MODE: nonqueued-receiver-com-spec{data-element=CFG_INIT_VAM_ECS_MODE, handle-data-status=true, init-value=CONST_tLOG_1:1}, required-interface=SR_CFG_INIT_VAM_ECS_MODE
      RP_SR_CFG_INIT_VITESSE_1: nonqueued-receiver-com-spec{data-element=CFG_INIT_VITESSE_1, handle-data-status=true, init-value=CONST_tBYTE_50:50}, required-interface=SR_CFG_INIT_VITESSE_1
      RP_SR_CFG_INIT_VITESSE_2: nonqueued-receiver-com-spec{data-element=CFG_INIT_VITESSE_2, handle-data-status=true, init-value=CONST_tBYTE_70:70}, required-interface=SR_CFG_INIT_VITESSE_2
      RP_SR_CFG_INIT_VITESSE_3: nonqueued-receiver-com-spec{data-element=CFG_INIT_VITESSE_3, handle-data-status=true, init-value=CONST_tBYTE_90:90}, required-interface=SR_CFG_INIT_VITESSE_3
      RP_SR_CFG_INIT_VITESSE_4: nonqueued-receiver-com-spec{data-element=CFG_INIT_VITESSE_4, handle-data-status=true, init-value=CONST_tBYTE_110:110}, required-interface=SR_CFG_INIT_VITESSE_4
      RP_SR_CFG_INIT_VITESSE_5: nonqueued-receiver-com-spec{data-element=CFG_INIT_VITESSE_5, handle-data-status=true, init-value=CONST_tBYTE_130:130}, required-interface=SR_CFG_INIT_VITESSE_5
      RP_SR_CFG_INIT_VIT_LVV_1: nonqueued-receiver-com-spec{data-element=CFG_INIT_VIT_LVV_1, handle-data-status=true, init-value=CONST_tBYTE_50:50}, required-interface=SR_CFG_INIT_VIT_LVV_1
      RP_SR_CFG_INIT_VIT_LVV_1_Miles: nonqueued-receiver-com-spec{data-element=CFG_INIT_VIT_LVV_1_Miles, handle-data-status=true, init-value=CONST_tBYTE_32:32}, required-interface=SR_CFG_INIT_VIT_LVV_1_Miles
      RP_SR_CFG_INIT_VIT_LVV_2: nonqueued-receiver-com-spec{data-element=CFG_INIT_VIT_LVV_2, handle-data-status=true, init-value=CONST_tBYTE_70:70}, required-interface=SR_CFG_INIT_VIT_LVV_2
      RP_SR_CFG_INIT_VIT_LVV_2_Miles: nonqueued-receiver-com-spec{data-element=CFG_INIT_VIT_LVV_2_Miles, handle-data-status=true, init-value=CONST_tBYTE_48:48}, required-interface=SR_CFG_INIT_VIT_LVV_2_Miles
      RP_SR_CFG_INIT_VIT_LVV_3: nonqueued-receiver-com-spec{data-element=CFG_INIT_VIT_LVV_3, handle-data-status=true, init-value=CONST_tBYTE_80:80}, required-interface=SR_CFG_INIT_VIT_LVV_3
      RP_SR_CFG_INIT_VIT_LVV_3_Miles: nonqueued-receiver-com-spec{data-element=CFG_INIT_VIT_LVV_3_Miles, handle-data-status=true, init-value=CONST_tBYTE_64:64}, required-interface=SR_CFG_INIT_VIT_LVV_3_Miles
      RP_SR_CFG_INIT_VIT_LVV_4: nonqueued-receiver-com-spec{data-element=CFG_INIT_VIT_LVV_4, handle-data-status=true, init-value=CONST_tBYTE_90:90}, required-interface=SR_CFG_INIT_VIT_LVV_4
      RP_SR_CFG_INIT_VIT_LVV_4_Miles: nonqueued-receiver-com-spec{data-element=CFG_INIT_VIT_LVV_4_Miles, handle-data-status=true, init-value=CONST_tBYTE_80:80}, required-interface=SR_CFG_INIT_VIT_LVV_4_Miles
      RP_SR_CFG_INIT_VIT_LVV_5: nonqueued-receiver-com-spec{data-element=CFG_INIT_VIT_LVV_5, handle-data-status=true, init-value=CONST_tBYTE_110:110}, required-interface=SR_CFG_INIT_VIT_LVV_5
      RP_SR_CFG_INIT_VIT_LVV_5_Miles: nonqueued-receiver-com-spec{data-element=CFG_INIT_VIT_LVV_5_Miles, handle-data-status=true, init-value=CONST_tBYTE_96:96}, required-interface=SR_CFG_INIT_VIT_LVV_5_Miles
      RP_SR_CFG_INIT_VIT_LVV_6: nonqueued-receiver-com-spec{data-element=CFG_INIT_VIT_LVV_6, handle-data-status=true, init-value=CONST_tBYTE_130:130}, required-interface=SR_CFG_INIT_VIT_LVV_6
      RP_SR_CFG_INIT_VIT_LVV_6_Miles: nonqueued-receiver-com-spec{data-element=CFG_INIT_VIT_LVV_6_Miles, handle-data-status=true, init-value=CONST_tBYTE_112:112}, required-interface=SR_CFG_INIT_VIT_LVV_6_Miles
      RP_SR_CFG_INIT_VIT_RVV_1: nonqueued-receiver-com-spec{data-element=CFG_INIT_VIT_RVV_1, handle-data-status=true, init-value=CONST_tBYTE_50:50}, required-interface=SR_CFG_INIT_VIT_RVV_1
      RP_SR_CFG_INIT_VIT_RVV_1_Miles: nonqueued-receiver-com-spec{data-element=CFG_INIT_VIT_RVV_1_Miles, handle-data-status=true, init-value=CONST_tBYTE_48:48}, required-interface=SR_CFG_INIT_VIT_RVV_1_Miles
      RP_SR_CFG_INIT_VIT_RVV_2: nonqueued-receiver-com-spec{data-element=CFG_INIT_VIT_RVV_2, handle-data-status=true, init-value=CONST_tBYTE_70:70}, required-interface=SR_CFG_INIT_VIT_RVV_2
      RP_SR_CFG_INIT_VIT_RVV_2_Miles: nonqueued-receiver-com-spec{data-element=CFG_INIT_VIT_RVV_2_Miles, handle-data-status=true, init-value=CONST_tBYTE_64:64}, required-interface=SR_CFG_INIT_VIT_RVV_2_Miles
      RP_SR_CFG_INIT_VIT_RVV_3: nonqueued-receiver-com-spec{data-element=CFG_INIT_VIT_RVV_3, handle-data-status=true, init-value=CONST_tBYTE_80:80}, required-interface=SR_CFG_INIT_VIT_RVV_3
      RP_SR_CFG_INIT_VIT_RVV_3_Miles: nonqueued-receiver-com-spec{data-element=CFG_INIT_VIT_RVV_3_Miles, handle-data-status=true, init-value=CONST_tBYTE_80:80}, required-interface=SR_CFG_INIT_VIT_RVV_3_Miles
      RP_SR_CFG_INIT_VIT_RVV_4: nonqueued-receiver-com-spec{data-element=CFG_INIT_VIT_RVV_4, handle-data-status=true, init-value=CONST_tBYTE_90:90}, required-interface=SR_CFG_INIT_VIT_RVV_4
      RP_SR_CFG_INIT_VIT_RVV_4_Miles: nonqueued-receiver-com-spec{data-element=CFG_INIT_VIT_RVV_4_Miles, handle-data-status=true, init-value=CONST_tBYTE_96:96}, required-interface=SR_CFG_INIT_VIT_RVV_4_Miles
      RP_SR_CFG_INIT_VIT_RVV_5: nonqueued-receiver-com-spec{data-element=CFG_INIT_VIT_RVV_5, handle-data-status=true, init-value=CONST_tBYTE_110:110}, required-interface=SR_CFG_INIT_VIT_RVV_5
      RP_SR_CFG_INIT_VIT_RVV_5_Miles: nonqueued-receiver-com-spec{data-element=CFG_INIT_VIT_RVV_5_Miles, handle-data-status=true, init-value=CONST_tBYTE_112:112}, required-interface=SR_CFG_INIT_VIT_RVV_5_Miles
      RP_SR_CFG_INIT_VIT_RVV_6: nonqueued-receiver-com-spec{data-element=CFG_INIT_VIT_RVV_6, handle-data-status=true, init-value=CONST_tBYTE_130:130}, required-interface=SR_CFG_INIT_VIT_RVV_6
      RP_SR_CFG_INIT_VIT_RVV_6_Miles: nonqueued-receiver-com-spec{data-element=CFG_INIT_VIT_RVV_6_Miles, handle-data-status=true, init-value=CONST_tBYTE_129:129}, required-interface=SR_CFG_INIT_VIT_RVV_6_Miles
      RP_SR_CFG_INIT_VTOR_IRV: nonqueued-receiver-com-spec{data-element=CFG_INIT_VTOR_IRV, handle-data-status=true, init-value=CONST_tLOG_0:0}, required-interface=SR_CFG_INIT_VTOR_IRV
      RP_SR_CFG_MECATRONIC_HEADLAMP: nonqueued-receiver-com-spec{data-element=CFG_MECATRONIC_HEADLAMP, handle-data-status=true, init-value=CONST_tLOG_0:0}, required-interface=SR_CFG_MECATRONIC_HEADLAMP
      RP_SR_CFG_OPTION_MENU_FSE: nonqueued-receiver-com-spec{data-element=CFG_OPTION_MENU_FSE, handle-data-status=true, init-value=CONST_tLOG_1:1}, required-interface=SR_CFG_OPTION_MENU_FSE
      RP_SR_CFG_PRESENCE_AFS: nonqueued-receiver-com-spec{data-element=CFG_PRESENCE_AFS, handle-data-status=true, init-value=CONST_tLOG_0:0}, required-interface=SR_CFG_PRESENCE_AFS
      RP_SR_CFG_PRESENCE_ARC: nonqueued-receiver-com-spec{data-element=CFG_PRESENCE_ARC, handle-data-status=true, init-value=CONST_t_cARC_0_1:1}, required-interface=SR_CFG_PRESENCE_ARC
      RP_SR_CFG_PRESENCE_FARC: nonqueued-receiver-com-spec{data-element=CFG_PRESENCE_FARC, handle-data-status=true, init-value=CONST_t_cFARC_0_0:0}, required-interface=SR_CFG_PRESENCE_FARC
      RP_SR_CFG_PRESENCE_MENU_PERSO: nonqueued-receiver-com-spec{data-element=CFG_PRESENCE_MENU_PERSO, handle-data-status=true, init-value=CONST_tBYTE_0:0}, required-interface=SR_CFG_PRESENCE_MENU_PERSO
      RP_SR_CFG_PRESENCE_TO: nonqueued-receiver-com-spec{data-element=CFG_PRESENCE_TO, handle-data-status=true, init-value=CONST_t_CFG_PRESENCE_TO_0:0}, required-interface=SR_CFG_PRESENCE_TO
      RP_SR_CFG_PRESENCE_TOUCHE_CONFIG: nonqueued-receiver-com-spec{data-element=CFG_PRESENCE_TOUCHE_CONFIG, handle-data-status=true, init-value=CONST_tLOG_0:0}, required-interface=SR_CFG_PRESENCE_TOUCHE_CONFIG
      RP_SR_CFG_TYPE_AAS: nonqueued-receiver-com-spec{data-element=CFG_TYPE_AAS, handle-data-status=true, init-value=CONST_t_cAAS_0:0}, required-interface=SR_CFG_TYPE_AAS
      RP_SR_CFG_TYPE_ACTIVATION_AFS: nonqueued-receiver-com-spec{data-element=CFG_TYPE_ACTIVATION_AFS, handle-data-status=true, init-value=CONST_tLOG_0:0}, required-interface=SR_CFG_TYPE_ACTIVATION_AFS
      RP_SR_CFG_TYPE_FSE: nonqueued-receiver-com-spec{data-element=CFG_TYPE_FSE, handle-data-status=true, init-value=CONST_t_cTypeFSE_0:0}, required-interface=SR_CFG_TYPE_FSE
      RP_SR_CFG_TYPE_FUNCTIONAL_ABSD: nonqueued-receiver-com-spec{data-element=CFG_TYPE_FUNCTIONAL_ABSD, handle-data-status=true, init-value=CONST_t_cTYPE_FUNCTIONAL_ABSD_0:0}, required-interface=SR_CFG_TYPE_FUNCTIONAL_ABSD
      RP_SR_CFG_TYPE_REGLAGE_SELECTIVITE: nonqueued-receiver-com-spec{data-element=CFG_TYPE_REGLAGE_SELECTIVITE, handle-data-status=true, init-value=CONST_t_cGAV_Selectivite_0:0}, required-interface=SR_CFG_TYPE_REGLAGE_SELECTIVITE
      RP_SR_CFG_TYPE_SELECTIVITE: nonqueued-receiver-com-spec{data-element=CFG_TYPE_SELECTIVITE, handle-data-status=true, init-value=CONST_t_cTypeSelect_0:0}, required-interface=SR_CFG_TYPE_SELECTIVITE
      RP_SR_CFG_TYPE_SELECTIVITE_OUV_AR: nonqueued-receiver-com-spec{data-element=CFG_TYPE_SELECTIVITE_OUV_AR, handle-data-status=true, init-value=CONST_t_cTypeSelectOuvAR_0:0}, required-interface=SR_CFG_TYPE_SELECTIVITE_OUV_AR
      RP_SR_CondaRealiseePourCAN: nonqueued-receiver-com-spec{data-element=CondaRealiseePourCAN, handle-data-status=true, init-value=CONST_tBYTE_0:0}, required-interface=SR_CondaRealiseePourCAN
      RP_SR_DispoDmdMenuPrgPem: nonqueued-receiver-com-spec{data-element=DispoDmdMenuPrgPem, handle-data-status=true, init-value=CONST_tLOG_0:0}, required-interface=SR_DispoDmdMenuPrgPem
      RP_SR_DmdDispoDmdMenuReserveZEV: nonqueued-receiver-com-spec{data-element=DmdDispoDmdMenuReserveZEV, handle-data-status=true, init-value=CONST_tLOG_0:0}, required-interface=SR_DmdDispoDmdMenuReserveZEV
      RP_SR_DmdMenuARCSensNiv: nonqueued-receiver-com-spec{data-element=DmdMenuARCSensNiv, handle-data-status=true, init-value=CONST_tBILOG_2:2}, required-interface=SR_DmdMenuARCSensNiv
      RP_SR_DmdMenuAccueilCond: nonqueued-receiver-com-spec{data-element=DmdMenuAccueilCond, handle-data-status=true, init-value=CONST_tLOG_0:0}, required-interface=SR_DmdMenuAccueilCond
      RP_SR_DmdMenuActButee{1..5}XVV: nonqueued-receiver-com-spec{data-element=DmdMenuActButee{1..5}XVV, handle-data-status=true, init-value=CONST_tLOG_0:0}, required-interface=SR_DmdMenuActButee{1..5}XVV
      RP_SR_DmdMenuActButeeGenXVV: nonqueued-receiver-com-spec{data-element=DmdMenuActButeeGenXVV, handle-data-status=true, init-value=CONST_tLOG_0:0}, required-interface=SR_DmdMenuActButeeGenXVV
      RP_SR_DmdMenuBAAActivation: nonqueued-receiver-com-spec{data-element=DmdMenuBAAActivation, handle-data-status=true, init-value=CONST_tLOG_0:0}, required-interface=SR_DmdMenuBAAActivation
      RP_SR_DmdMenuBAAAutolocking: nonqueued-receiver-com-spec{data-element=DmdMenuBAAAutolocking, handle-data-status=true, init-value=CONST_tLOG_0:0}, required-interface=SR_DmdMenuBAAAutolocking
      RP_SR_DmdMenuCLIM_PrecondDi{1..4}: nonqueued-receiver-com-spec{data-element=DmdMenuCLIM_PrecondDi{1..4}, handle-data-status=true, init-value=CONST_tLOG_0:0}, required-interface=SR_DmdMenuCLIM_PrecondDi{1..4}
      RP_SR_DmdMenuCLIM_PrecondH{1..4}: nonqueued-receiver-com-spec{data-element=DmdMenuCLIM_PrecondH{1..4}, handle-data-status=true, init-value=CONST_tWORD_0:0}, required-interface=SR_DmdMenuCLIM_PrecondH{1..4}
      RP_SR_DmdMenuCLIM_PrecondJe{1..4}: nonqueued-receiver-com-spec{data-element=DmdMenuCLIM_PrecondJe{1..4}, handle-data-status=true, init-value=CONST_tLOG_0:0}, required-interface=SR_DmdMenuCLIM_PrecondJe{1..4}
      RP_SR_DmdMenuCLIM_PrecondLu{1..4}: nonqueued-receiver-com-spec{data-element=DmdMenuCLIM_PrecondLu{1..4}, handle-data-status=true, init-value=CONST_tLOG_0:0}, required-interface=SR_DmdMenuCLIM_PrecondLu{1..4}
      RP_SR_DmdMenuCLIM_PrecondMa{1..4}: nonqueued-receiver-com-spec{data-element=DmdMenuCLIM_PrecondMa{1..4}, handle-data-status=true, init-value=CONST_tLOG_0:0}, required-interface=SR_DmdMenuCLIM_PrecondMa{1..4}
      RP_SR_DmdMenuCLIM_PrecondMe{1..4}: nonqueued-receiver-com-spec{data-element=DmdMenuCLIM_PrecondMe{1..4}, handle-data-status=true, init-value=CONST_tLOG_0:0}, required-interface=SR_DmdMenuCLIM_PrecondMe{1..4}
      RP_SR_DmdMenuCLIM_PrecondOn{1..4}: nonqueued-receiver-com-spec{data-element=DmdMenuCLIM_PrecondOn{1..4}, handle-data-status=true, init-value=CONST_tLOG_0:0}, required-interface=SR_DmdMenuCLIM_PrecondOn{1..4}
      RP_SR_DmdMenuCLIM_PrecondSa{1..4}: nonqueued-receiver-com-spec{data-element=DmdMenuCLIM_PrecondSa{1..4}, handle-data-status=true, init-value=CONST_tLOG_0:0}, required-interface=SR_DmdMenuCLIM_PrecondSa{1..4}
      RP_SR_DmdMenuCLIM_PrecondVe{1..4}: nonqueued-receiver-com-spec{data-element=DmdMenuCLIM_PrecondVe{1..4}, handle-data-status=true, init-value=CONST_tLOG_0:0}, required-interface=SR_DmdMenuCLIM_PrecondVe{1..4}
      RP_SR_DmdMenuCMDM_DAE: nonqueued-receiver-com-spec{data-element=DmdMenuCMDM_DAE, handle-data-status=true, init-value=CONST_tLOG_0:0}, required-interface=SR_DmdMenuCMDM_DAE
      RP_SR_DmdMenuCMDM_DAE_4WD: nonqueued-receiver-com-spec{data-element=DmdMenuCMDM_DAE_4WD, handle-data-status=true, init-value=CONST_tLOG_0:0}, required-interface=SR_DmdMenuCMDM_DAE_4WD
      RP_SR_DmdMenuClim_PrecondASAP: nonqueued-receiver-com-spec{data-element=DmdMenuClim_PrecondASAP, handle-data-status=true, init-value=CONST_tLOG_0:0}, required-interface=SR_DmdMenuClim_PrecondASAP
      RP_SR_DmdMenuDAAActivation: nonqueued-receiver-com-spec{data-element=DmdMenuDAAActivation, handle-data-status=true, init-value=CONST_tLOG_0:0}, required-interface=SR_DmdMenuDAAActivation
      RP_SR_DmdMenuDSG: nonqueued-receiver-com-spec{data-element=DmdMenuDSG, handle-data-status=true, init-value=CONST_tLOG_0:0}, required-interface=SR_DmdMenuDSG
      RP_SR_DmdMenuECLI_PPC_ANIM: nonqueued-receiver-com-spec{data-element=DmdMenuECLI_PPC_ANIM, handle-data-status=true, init-value=CONST_tBYTE_0:0}, required-interface=SR_DmdMenuECLI_PPC_ANIM
      RP_SR_DmdMenuECLI_PPC_BLOC1: nonqueued-receiver-com-spec{data-element=DmdMenuECLI_PPC_BLOC1, handle-data-status=true, init-value=CONST_tLOG_0:0}, required-interface=SR_DmdMenuECLI_PPC_BLOC1
      RP_SR_DmdMenuECLI_PPC_COL1: nonqueued-receiver-com-spec{data-element=DmdMenuECLI_PPC_COL1, handle-data-status=true, init-value=CONST_tBYTE_0:0}, required-interface=SR_DmdMenuECLI_PPC_COL1
      RP_SR_DmdMenuECLX_AFS: nonqueued-receiver-com-spec{data-element=DmdMenuECLX_AFS, handle-data-status=true, init-value=CONST_tLOG_0:0}, required-interface=SR_DmdMenuECLX_AFS
      RP_SR_DmdMenuECLX_ARS: nonqueued-receiver-com-spec{data-element=DmdMenuECLX_ARS, handle-data-status=true, init-value=CONST_tLOG_0:0}, required-interface=SR_DmdMenuECLX_ARS
      RP_SR_DmdMenuECLX_ECL_CAFR: nonqueued-receiver-com-spec{data-element=DmdMenuECLX_ECL_CAFR, handle-data-status=true, init-value=CONST_tLOG_0:0}, required-interface=SR_DmdMenuECLX_ECL_CAFR
      RP_SR_DmdMenuEclAccomp: nonqueued-receiver-com-spec{data-element=DmdMenuEclAccomp, handle-data-status=true, init-value=CONST_tLOG_0:0}, required-interface=SR_DmdMenuEclAccomp
      RP_SR_DmdMenuEclAccompTempo: nonqueued-receiver-com-spec{data-element=DmdMenuEclAccompTempo, handle-data-status=true, init-value=CONST_tBILOG_0:0}, required-interface=SR_DmdMenuEclAccompTempo
      RP_SR_DmdMenuEclAdapt: nonqueued-receiver-com-spec{data-element=DmdMenuEclAdapt, handle-data-status=true, init-value=CONST_tLOG_0:0}, required-interface=SR_DmdMenuEclAdapt
      RP_SR_DmdMenuEclAmbi: nonqueued-receiver-com-spec{data-element=DmdMenuEclAmbi, handle-data-status=true, init-value=CONST_tLOG_0:0}, required-interface=SR_DmdMenuEclAmbi
      RP_SR_DmdMenuEclAmbiNiv: nonqueued-receiver-com-spec{data-element=DmdMenuEclAmbiNiv, handle-data-status=true, init-value=CONST_tBYTE_3:3}, required-interface=SR_DmdMenuEclAmbiNiv
      RP_SR_DmdMenuEclAuto: nonqueued-receiver-com-spec{data-element=DmdMenuEclAuto, handle-data-status=true, init-value=CONST_tLOG_0:0}, required-interface=SR_DmdMenuEclAuto
      RP_SR_DmdMenuEclAutoroute: nonqueued-receiver-com-spec{data-element=DmdMenuEclAutoroute, handle-data-status=true, init-value=CONST_tLOG_0:0}, required-interface=SR_DmdMenuEclAutoroute
      RP_SR_DmdMenuEclCaland: nonqueued-receiver-com-spec{data-element=DmdMenuEclCaland, handle-data-status=true, init-value=CONST_tLOG_0:0}, required-interface=SR_DmdMenuEclCaland
      RP_SR_DmdMenuEclDeconda: nonqueued-receiver-com-spec{data-element=DmdMenuEclDeconda, handle-data-status=true, init-value=CONST_tLOG_0:0}, required-interface=SR_DmdMenuEclDeconda
      RP_SR_DmdMenuEclDecondaTempo: nonqueued-receiver-com-spec{data-element=DmdMenuEclDecondaTempo, handle-data-status=true, init-value=CONST_tBILOG_0:0}, required-interface=SR_DmdMenuEclDecondaTempo
      RP_SR_DmdMenuEssuiVitMar: nonqueued-receiver-com-spec{data-element=DmdMenuEssuiVitMar, handle-data-status=true, init-value=CONST_tLOG_0:0}, required-interface=SR_DmdMenuEssuiVitMar
      RP_SR_DmdMenuFARC: nonqueued-receiver-com-spec{data-element=DmdMenuFARC, handle-data-status=true, init-value=CONST_tLOG_0:0}, required-interface=SR_DmdMenuFARC
      RP_SR_DmdMenuFSEAuto: nonqueued-receiver-com-spec{data-element=DmdMenuFSEAuto, handle-data-status=true, init-value=CONST_tLOG_0:0}, required-interface=SR_DmdMenuFSEAuto
      RP_SR_DmdMenuFeuxDiurne: nonqueued-receiver-com-spec{data-element=DmdMenuFeuxDiurne, handle-data-status=true, init-value=CONST_tLOG_0:0}, required-interface=SR_DmdMenuFeuxDiurne
      RP_SR_DmdMenuGAV_AMLA: nonqueued-receiver-com-spec{data-element=DmdMenuGAV_AMLA, handle-data-status=true, init-value=CONST_tLOG_0:0}, required-interface=SR_DmdMenuGAV_AMLA
      RP_SR_DmdMenuILV: nonqueued-receiver-com-spec{data-element=DmdMenuILV, handle-data-status=true, init-value=CONST_tLOG_0:0}, required-interface=SR_DmdMenuILV
      RP_SR_DmdMenuILV_ETSR: nonqueued-receiver-com-spec{data-element=DmdMenuILV_ETSR, handle-data-status=true, init-value=CONST_tLOG_0:0}, required-interface=SR_DmdMenuILV_ETSR
      RP_SR_DmdMenuIMA: nonqueued-receiver-com-spec{data-element=DmdMenuIMA, handle-data-status=true, init-value=CONST_tLOG_0:0}, required-interface=SR_DmdMenuIMA
      RP_SR_DmdMenuINV_ADSD: nonqueued-receiver-com-spec{data-element=DmdMenuINV_ADSD, handle-data-status=true, init-value=CONST_tLOG_0:0}, required-interface=SR_DmdMenuINV_ADSD
      RP_SR_DmdMenuInfoLvvDispo: nonqueued-receiver-com-spec{data-element=DmdMenuInfoLvvDispo, handle-data-status=true, init-value=CONST_tLOG_0:0}, required-interface=SR_DmdMenuInfoLvvDispo
      RP_SR_DmdMenuInfoParamDispo: nonqueued-receiver-com-spec{data-element=DmdMenuInfoParamDispo, handle-data-status=true, init-value=CONST_tLOG_0:0}, required-interface=SR_DmdMenuInfoParamDispo
      RP_SR_DmdMenuInfoPrecondDispo: nonqueued-receiver-com-spec{data-element=DmdMenuInfoPrecondDispo, handle-data-status=true, init-value=CONST_tLOG_0:0}, required-interface=SR_DmdMenuInfoPrecondDispo
      RP_SR_DmdMenuInfoRechargeDispo: nonqueued-receiver-com-spec{data-element=DmdMenuInfoRechargeDispo, handle-data-status=true, init-value=CONST_tLOG_0:0}, required-interface=SR_DmdMenuInfoRechargeDispo
      RP_SR_DmdMenuInfoRvvDispo: nonqueued-receiver-com-spec{data-element=DmdMenuInfoRvvDispo, handle-data-status=true, init-value=CONST_tLOG_0:0}, required-interface=SR_DmdMenuInfoRvvDispo
      RP_SR_DmdMenuInfoUniteLangueDispo: nonqueued-receiver-com-spec{data-element=DmdMenuInfoUniteLangueDispo, handle-data-status=true, init-value=CONST_tLOG_0:0}, required-interface=SR_DmdMenuInfoUniteLangueDispo
      RP_SR_DmdMenuInfoXVVDispo: nonqueued-receiver-com-spec{data-element=DmdMenuInfoXVVDispo, handle-data-status=true, init-value=CONST_tLOG_0:0}, required-interface=SR_DmdMenuInfoXVVDispo
      RP_SR_DmdMenuLangueVehicule: nonqueued-receiver-com-spec{data-element=DmdMenuLangueVehicule, handle-data-status=true, init-value=CONST_tBYTE_0:0}, required-interface=SR_DmdMenuLangueVehicule
      RP_SR_DmdMenuMotoVolAr: nonqueued-receiver-com-spec{data-element=DmdMenuMotoVolAr, handle-data-status=true, init-value=CONST_tLOG_0:0}, required-interface=SR_DmdMenuMotoVolAr
      RP_SR_DmdMenuPRV_MODE: nonqueued-receiver-com-spec{data-element=DmdMenuPRV_MODE, handle-data-status=true, init-value=CONST_tBYTE_0:0}, required-interface=SR_DmdMenuPRV_MODE
      RP_SR_DmdMenuPresenceARC: nonqueued-receiver-com-spec{data-element=DmdMenuPresenceARC, handle-data-status=true, init-value=CONST_tLOG_0:0}, required-interface=SR_DmdMenuPresenceARC
      RP_SR_DmdMenuPrgHcEnd: nonqueued-receiver-com-spec{data-element=DmdMenuPrgHcEnd, handle-data-status=true, init-value=CONST_tDWORD_0:0}, required-interface=SR_DmdMenuPrgHcEnd
      RP_SR_DmdMenuPrgHcStart: nonqueued-receiver-com-spec{data-element=DmdMenuPrgHcStart, handle-data-status=true, init-value=CONST_tDWORD_0:0}, required-interface=SR_DmdMenuPrgHcStart
      RP_SR_DmdMenuPrgPemDi: nonqueued-receiver-com-spec{data-element=DmdMenuPrgPemDi, handle-data-status=true, init-value=CONST_tDWORD_0:0}, required-interface=SR_DmdMenuPrgPemDi
      RP_SR_DmdMenuPrgPemJe: nonqueued-receiver-com-spec{data-element=DmdMenuPrgPemJe, handle-data-status=true, init-value=CONST_tDWORD_0:0}, required-interface=SR_DmdMenuPrgPemJe
      RP_SR_DmdMenuPrgPemLu: nonqueued-receiver-com-spec{data-element=DmdMenuPrgPemLu, handle-data-status=true, init-value=CONST_tDWORD_0:0}, required-interface=SR_DmdMenuPrgPemLu
      RP_SR_DmdMenuPrgPemMa: nonqueued-receiver-com-spec{data-element=DmdMenuPrgPemMa, handle-data-status=true, init-value=CONST_tDWORD_0:0}, required-interface=SR_DmdMenuPrgPemMa
      RP_SR_DmdMenuPrgPemMe: nonqueued-receiver-com-spec{data-element=DmdMenuPrgPemMe, handle-data-status=true, init-value=CONST_tDWORD_0:0}, required-interface=SR_DmdMenuPrgPemMe
      RP_SR_DmdMenuPrgPemSa: nonqueued-receiver-com-spec{data-element=DmdMenuPrgPemSa, handle-data-status=true, init-value=CONST_tDWORD_0:0}, required-interface=SR_DmdMenuPrgPemSa
      RP_SR_DmdMenuPrgPemVe: nonqueued-receiver-com-spec{data-element=DmdMenuPrgPemVe, handle-data-status=true, init-value=CONST_tDWORD_0:0}, required-interface=SR_DmdMenuPrgPemVe
      RP_SR_DmdMenuRTAB_EnergyRec: nonqueued-receiver-com-spec{data-element=DmdMenuRTAB_EnergyRec, handle-data-status=true, init-value=CONST_tBYTE_0b01:0b01}, required-interface=SR_DmdMenuRTAB_EnergyRec
      RP_SR_DmdMenuRTAB_RechargeHDeb: nonqueued-receiver-com-spec{data-element=DmdMenuRTAB_RechargeHDeb, handle-data-status=true, init-value=CONST_tWORD_0:0}, required-interface=SR_DmdMenuRTAB_RechargeHDeb
      RP_SR_DmdMenuRTAB_TypeRec: nonqueued-receiver-com-spec{data-element=DmdMenuRTAB_TypeRec, handle-data-status=true, init-value=CONST_tLOG_0:0}, required-interface=SR_DmdMenuRTAB_TypeRec
      RP_SR_DmdMenuReserveZEV: nonqueued-receiver-com-spec{data-element=DmdMenuReserveZEV, handle-data-status=true, init-value=CONST_tBILOG_0:0}, required-interface=SR_DmdMenuReserveZEV
      RP_SR_DmdMenuSelPrgHc: nonqueued-receiver-com-spec{data-element=DmdMenuSelPrgHc, handle-data-status=true, init-value=CONST_tLOG_0:0}, required-interface=SR_DmdMenuSelPrgHc
      RP_SR_DmdMenuSelReserveZEV: nonqueued-receiver-com-spec{data-element=DmdMenuSelReserveZEV, handle-data-status=true, init-value=CONST_tLOG_0:0}, required-interface=SR_DmdMenuSelReserveZEV
      RP_SR_DmdMenuSelecArriere: nonqueued-receiver-com-spec{data-element=DmdMenuSelecArriere, handle-data-status=true, init-value=CONST_tLOG_0:0}, required-interface=SR_DmdMenuSelecArriere
      RP_SR_DmdMenuSelecCabine: nonqueued-receiver-com-spec{data-element=DmdMenuSelecCabine, handle-data-status=true, init-value=CONST_tLOG_0:0}, required-interface=SR_DmdMenuSelecCabine
      RP_SR_DmdMenuSelecOuvPlip: nonqueued-receiver-com-spec{data-element=DmdMenuSelecOuvPlip, handle-data-status=true, init-value=CONST_tLOG_0:0}, required-interface=SR_DmdMenuSelecOuvPlip
      RP_SR_DmdMenuSonPoly: nonqueued-receiver-com-spec{data-element=DmdMenuSonPoly, handle-data-status=true, init-value=CONST_tBILOG_0:0}, required-interface=SR_DmdMenuSonPoly
      RP_SR_DmdMenuStatusAAS: nonqueued-receiver-com-spec{data-element=DmdMenuStatusAAS, handle-data-status=true, init-value=CONST_tLOG_0:0}, required-interface=SR_DmdMenuStatusAAS
      RP_SR_DmdMenuStatusSAM: nonqueued-receiver-com-spec{data-element=DmdMenuStatusSAM, handle-data-status=true, init-value=CONST_tLOG_0:0}, required-interface=SR_DmdMenuStatusSAM
      RP_SR_DmdMenuTCFG: nonqueued-receiver-com-spec{data-element=DmdMenuTCFG, handle-data-status=true, init-value=CONST_tBYTE_0:0}, required-interface=SR_DmdMenuTCFG
      RP_SR_DmdMenuUniteConso: nonqueued-receiver-com-spec{data-element=DmdMenuUniteConso, handle-data-status=true, init-value=CONST_tLOG_0:0}, required-interface=SR_DmdMenuUniteConso
      RP_SR_DmdMenuUniteDistance: nonqueued-receiver-com-spec{data-element=DmdMenuUniteDistance, handle-data-status=true, init-value=CONST_tLOG_0:0}, required-interface=SR_DmdMenuUniteDistance
      RP_SR_DmdMenuUniteTemperature: nonqueued-receiver-com-spec{data-element=DmdMenuUniteTemperature, handle-data-status=true, init-value=CONST_tLOG_0:0}, required-interface=SR_DmdMenuUniteTemperature
      RP_SR_DmdMenuUniteVolume: nonqueued-receiver-com-spec{data-element=DmdMenuUniteVolume, handle-data-status=true, init-value=CONST_tLOG_0:0}, required-interface=SR_DmdMenuUniteVolume
      RP_SR_DmdMenuVAM_ECS_MODE: nonqueued-receiver-com-spec{data-element=DmdMenuVAM_ECS_MODE, handle-data-status=true, init-value=CONST_tLOG_0:0}, required-interface=SR_DmdMenuVAM_ECS_MODE
      RP_SR_DmdMenuVTOR_IRV: nonqueued-receiver-com-spec{data-element=DmdMenuVTOR_IRV, handle-data-status=true, init-value=CONST_tLOG_0:0}, required-interface=SR_DmdMenuVTOR_IRV
      RP_SR_DmdMenuVitLvv{1..6}: nonqueued-receiver-com-spec{data-element=DmdMenuVitLvv{1..6}, handle-data-status=true, init-value=CONST_tBYTE_0:0}, required-interface=SR_DmdMenuVitLvv{1..6}
      RP_SR_DmdMenuVitRvv{1..6}: nonqueued-receiver-com-spec{data-element=DmdMenuVitRvv{1..6}, handle-data-status=true, init-value=CONST_tBYTE_0:0}, required-interface=SR_DmdMenuVitRvv{1..6}
      RP_SR_DmdMenuVitesse{1..5}XVV: nonqueued-receiver-com-spec{data-element=DmdMenuVitesse{1..5}XVV, handle-data-status=true, init-value=CONST_tBYTE_0:0}, required-interface=SR_DmdMenuVitesse{1..5}XVV
      RP_SR_DmdmCGEPVOffReserveZEV: nonqueued-receiver-com-spec{data-element=DmdmCGEPVOffReserveZEV, handle-data-status=true, init-value=CONST_tLOG_0:0}, required-interface=SR_DmdmCGEPVOffReserveZEV
      RP_SR_EtatPrincipalSEV: nonqueued-receiver-com-spec{data-element=EtatPrincipalSEV, handle-data-status=true, init-value=CONST_t_SEV_0x69:105}, required-interface=SR_EtatPrincipalSEV
      RP_SR_MenuPersoMuet: nonqueued-receiver-com-spec{data-element=MenuPersoMuet, handle-data-status=true, init-value=CONST_tLOG_0:0}, required-interface=SR_MenuPersoMuet
      RP_SR_PhaseVieLS: nonqueued-receiver-com-spec{data-element=PhaseVieLS, handle-data-status=true, init-value=CONST_t_cCANLS_0:0}, required-interface=SR_PhaseVieLS
      RP_SR_RechargeTypeStatus: nonqueued-receiver-com-spec{data-element=RechargeTypeStatus, handle-data-status=true, init-value=CONST_tBYTE_0:0}, required-interface=SR_RechargeTypeStatus
      RP_SR_T28_APPUI_LONG_TOUCHE_CONF: nonqueued-receiver-com-spec{data-element=T28_APPUI_LONG_TOUCHE_CONF, handle-data-status=true, init-value=CONST_tBYTE_2:2}, required-interface=SR_T28_APPUI_LONG_TOUCHE_CONF
      RP_SR_T28_MAINTIEN_DONNEES_TOUCHE: nonqueued-receiver-com-spec{data-element=T28_MAINTIEN_DONNEES_TOUCHE, handle-data-status=true, init-value=CONST_t_T28_MAINTIEN_DONNEES_TOUCHE_500:500}, required-interface=SR_T28_MAINTIEN_DONNEES_TOUCHE
      RP_SR_ToggleNewFrame19B: nonqueued-receiver-com-spec{data-element=ToggleNewFrame19B, handle-data-status=true, init-value=CONST_tLOG_0:0}, required-interface=SR_ToggleNewFrame19B
      RP_SR_ToggleNewFrame1DB: nonqueued-receiver-com-spec{data-element=ToggleNewFrame1DB, handle-data-status=true, init-value=CONST_tLOG_0:0}, required-interface=SR_ToggleNewFrame1DB
      RP_SR_ToggleNewFrame25B29B: nonqueued-receiver-com-spec{data-element=ToggleNewFrame25B29B, handle-data-status=true, init-value=CONST_tLOG_0:0}, required-interface=SR_ToggleNewFrame25B29B
      RP_SR_ToggleNewFrame2DB: nonqueued-receiver-com-spec{data-element=ToggleNewFrame2DB, handle-data-status=true, init-value=CONST_tLOG_0:0}, required-interface=SR_ToggleNewFrame2DB
    behavior IB_ASWC_A28: data-type-mapping=ApplicationModeMapping, handle-termination-and-restart=NO-SUPPORT
      ar-typed-per-instance-memorys:
        163 x data:
          PA28_AllumPlafDeVMF_HDC: type=tLOG, init-value=CONST_tLOG_0:0
          PA28_AllumPlafDeVMF_TCFG: type=tLOG, init-value=CONST_tLOG_0:0
          PA28_AppuiPushBEPR_Prec: type=tLOG, init-value=CONST_tLOG_0:0
          PA28_AppuiPushMPDParHDCPrec: type=tLOG, init-value=CONST_tLOG_0:0
          PA28_AppuiToucheConfigPrec: type=tLOG, init-value=CONST_tLOG_0:0
          PA28_EtatMenuPrgPemDi: type=tDWORD, init-value=CONST_tDWORD_0:0
          PA28_EtatMenuPrgPemJe: type=tDWORD, init-value=CONST_tDWORD_0:0
          PA28_EtatMenuPrgPemLu: type=tDWORD, init-value=CONST_tDWORD_0:0
          PA28_EtatMenuPrgPemMa: type=tDWORD, init-value=CONST_tDWORD_0:0
          PA28_EtatMenuPrgPemMe: type=tDWORD, init-value=CONST_tDWORD_0:0
          PA28_EtatMenuPrgPemSa: type=tDWORD, init-value=CONST_tDWORD_0:0
          PA28_EtatMenuPrgPemVe: type=tDWORD, init-value=CONST_tDWORD_0:0
          PA28_EtatPrincipalSEV_Prec: type=tBYTE, init-value=CONST_tBYTE_0x69:105
          PA28_RechargeTypeStatus_Prec: type=tBYTE, init-value=CONST_tBYTE_0:0
          PA28_SAV_CfgIniTReserveZEVDeMenuPersoPrec: type=tBYTE, init-value=CONST_tBYTE_2:2
          PA28_SAV_CfgInitAccueilDeMenuPersoPrec: type=tLOG, init-value=CONST_tLOG_1:1
          PA28_SAV_CfgInitActButee{1..5}XVVPrec: type=tLOG, init-value=CONST_tLOG_1:1
          PA28_SAV_CfgInitActButeeGenXVVPrec: type=tLOG, init-value=CONST_tLOG_0:0
          PA28_SAV_CfgInitActivationARCDeMenuPersoPrec: type=tLOG, init-value=CONST_tLOG_0:0
          PA28_SAV_CfgInitBAAActivationDeMenuPersoPrec: type=tLOG, init-value=CONST_tLOG_1:1
          PA28_SAV_CfgInitBAAAutolockingDeMenuPersoPrec: type=tLOG, init-value=CONST_tLOG_1:1
          PA28_SAV_CfgInitCLIMPrecPrg{1..4}DeMenuPersoPrec: type=tWORD, init-value=CONST_tWORD_0:0
          PA28_SAV_CfgInitCLIM_PrecASAPDeMenuPerso: type=tLOG, init-value=CONST_tLOG_0:0
          PA28_SAV_CfgInitCLIM_PrecH{1..4}DeMenuPersoPrec: type=tWORD, init-value=CONST_tWORD_0:0
          PA28_SAV_CfgInitCLIM_PrecOn{1..4}DeMenuPersoPrec: type=tLOG, init-value=CONST_tLOG_0:0
          PA28_SAV_CfgInitCLIM_PrecondDi{1..4}Prec: type=tLOG, init-value=CONST_tLOG_0:0
          PA28_SAV_CfgInitCLIM_PrecondJe{1..4}Prec: type=tLOG, init-value=CONST_tLOG_0:0
          PA28_SAV_CfgInitCLIM_PrecondLu{1..4}Prec: type=tLOG, init-value=CONST_tLOG_0:0
          PA28_SAV_CfgInitCLIM_PrecondMa{1..4}Prec: type=tLOG, init-value=CONST_tLOG_0:0
          PA28_SAV_CfgInitCLIM_PrecondMe{1..4}Prec: type=tLOG, init-value=CONST_tLOG_0:0
          PA28_SAV_CfgInitCLIM_PrecondSa{1..4}Prec: type=tLOG, init-value=CONST_tLOG_0:0
          PA28_SAV_CfgInitCLIM_PrecondSem{1..4}Prec: type=tLOG, init-value=CONST_tLOG_0:0
          PA28_SAV_CfgInitCLIM_PrecondVe{1..4}Prec: type=tLOG, init-value=CONST_tLOG_0:0
          PA28_SAV_CfgInitDAAActivationDeMenuPersoPrec: type=tLOG, init-value=CONST_tLOG_1:1
          PA28_SAV_CfgInitDSGDeMenuPersoPrec: type=tLOG, init-value=CONST_tLOG_0:0
          PA28_SAV_CfgInitDecondaSelectDeMenuPersoPrec: type=tLOG, init-value=CONST_tLOG_0:0
          PA28_SAV_CfgInitECLI_PPC_ANIMDeMenuPersoPrec: type=tBYTE, init-value=CONST_tBYTE_1:1
          PA28_SAV_CfgInitECLI_PPC_BLOC1DeMenuPersoPrec: type=tBYTE, init-value=CONST_tBYTE_1:1
          PA28_SAV_CfgInitECLI_PPC_COL1DeMenuPersoPrec: type=tBYTE, init-value=CONST_tBYTE_1:1
          PA28_SAV_CfgInitECLX_ECL_CAFRDeMenuPersoPrec: type=tLOG, init-value=CONST_tLOG_1:1
          PA28_SAV_CfgInitEclAFSDeMenuPersoPrec: type=tBYTE, init-value=CONST_tBYTE_1:1
          PA28_SAV_CfgInitEclARSDeMenuPersoPrec: type=tBYTE, init-value=CONST_tBYTE_1:1
          PA28_SAV_CfgInitEclAccompPrec: type=tLOG, init-value=CONST_tLOG_0:0
          PA28_SAV_CfgInitEclAccompTempoPrec: type=tBYTE, init-value=CONST_tBYTE_1:1
          PA28_SAV_CfgInitEclAdaptDeMenuPersoPrec: type=tLOG, init-value=CONST_tLOG_1:1
          PA28_SAV_CfgInitEclAmbiDeMenuPersoPrec: type=tLOG, init-value=CONST_tLOG_1:1
          PA28_SAV_CfgInitEclAmbiNivDeMenuPersoPrec: type=tBYTE, init-value=CONST_tBYTE_6:6
          PA28_SAV_CfgInitEclAutoDeMenuPersoPrec: type=tLOG, init-value=CONST_tLOG_0:0
          PA28_SAV_CfgInitEclAutorouteDeMenuPersoPrec: type=tLOG, init-value=CONST_tLOG_1:1
          PA28_SAV_CfgInitEclCalandDeMenuPersoPrec: type=tLOG, init-value=CONST_tLOG_1:1
          PA28_SAV_CfgInitEclDecondaPrec: type=tLOG, init-value=CONST_tLOG_0:0
          PA28_SAV_CfgInitEclDecondaTempoPrec: type=tLOG, init-value=CONST_tLOG_1:1
          PA28_SAV_CfgInitEssuiVitMarDeMenuPersoPrec: type=tLOG, init-value=CONST_tLOG_0:0
          PA28_SAV_CfgInitFARCDeMenuPersoPrec: type=tLOG, init-value=CONST_tLOG_0:0
          PA28_SAV_CfgInitFSEAutoDeMenuPersoPrec: type=tLOG, init-value=CONST_tLOG_1:1
          PA28_SAV_CfgInitFctToucheCfgDeMenuPersoPrec: type=tBYTE, init-value=CONST_tBYTE_4:4
          PA28_SAV_CfgInitFeuxDiurneDeMenuPersoPrec: type=tLOG, init-value=CONST_tLOG_0:0
          PA28_SAV_CfgInitGAV_AMLADeMenuPersoPrec: type=tLOG, init-value=CONST_tLOG_0:0
          PA28_SAV_CfgInitILVDeMenuPersoPrec: type=tLOG, init-value=CONST_tLOG_1:1
          PA28_SAV_CfgInitILV_ETSRDeMenuPersoPrec: type=tLOG, init-value=CONST_tLOG_1:1
          PA28_SAV_CfgInitIMADeMenuPersoPrec: type=tLOG, init-value=CONST_tLOG_0:0
          PA28_SAV_CfgInitINV_ADSDDeMenuPersoPrec: type=tLOG, init-value=CONST_tLOG_1:1
          PA28_SAV_CfgInitInhibitionAASDeMenuPersoPrec: type=tLOG, init-value=CONST_tLOG_1:1
          PA28_SAV_CfgInitInhibitionSAMDeMenuPersoPrec: type=tLOG, init-value=CONST_tLOG_1:1
          PA28_SAV_CfgInitLangueVehiculePrec: type=tBYTE, init-value=CONST_tBYTE_0:0
          PA28_SAV_CfgInitMotoVolArDeMenuPersoPrec: type=tLOG, init-value=CONST_tLOG_0:0
          PA28_SAV_CfgInitPRV_MODEDeMenuPersoPrec: type=tBYTE, init-value=CONST_tBYTE_1:1
          PA28_SAV_CfgInitPrgPemDiDeMenuPersoPrec: type=tDWORD, init-value=CONST_tDWORD_480:480
          PA28_SAV_CfgInitPrgPemJeDeMenuPersoPrec: type=tDWORD, init-value=CONST_tDWORD_480:480
          PA28_SAV_CfgInitPrgPemLuDeMenuPersoPrec: type=tDWORD, init-value=CONST_tDWORD_480:480
          PA28_SAV_CfgInitPrgPemMaDeMenuPersoPrec: type=tDWORD, init-value=CONST_tDWORD_480:480
          PA28_SAV_CfgInitPrgPemMeDeMenuPersoPrec: type=tDWORD, init-value=CONST_tDWORD_480:480
          PA28_SAV_CfgInitPrgPemSaDeMenuPersoPrec: type=tDWORD, init-value=CONST_tDWORD_480:480
          PA28_SAV_CfgInitPrgPemVeDeMenuPersoPrec: type=tDWORD, init-value=CONST_tDWORD_480:480
          PA28_SAV_CfgInitRTAB_EnergyRecDeMenuPersoPrec: type=tBYTE, init-value=CONST_tBYTE_0:0
          PA28_SAV_CfgInitRTAB_RecHDebDeMenuPersoPrec: type=tDWORD, init-value=CONST_tDWORD_0:0
          PA28_SAV_CfgInitRTAB_TypeRecDeMenuPersoPrec: type=tLOG, init-value=CONST_tLOG_0:0
          PA28_SAV_CfgInitSelReserveZEVDeMenuPersoPrec: type=tLOG, init-value=CONST_tLOG_1:1
          PA28_SAV_CfgInitSelectOuvARDeMenuPersoPrec: type=tLOG, init-value=CONST_tLOG_0:0
          PA28_SAV_CfgInitSensibiliteARCDeMenuPersoPrec: type=tBYTE, init-value=CONST_tBYTE_2:2
          PA28_SAV_CfgInitSonPolyphDeMenuPersoPrec: type=tBYTE, init-value=CONST_tBYTE_0:0
          PA28_SAV_CfgInitUniteConsoPrec: type=tLOG, init-value=CONST_tLOG_0:0
          PA28_SAV_CfgInitUniteDistancePrec: type=tLOG, init-value=CONST_tLOG_0:0
          PA28_SAV_CfgInitUniteTemperaturePrec: type=tLOG, init-value=CONST_tLOG_0:0
          PA28_SAV_CfgInitUniteVolumePrec: type=tLOG, init-value=CONST_tLOG_0:0
          PA28_SAV_CfgInitVTOR_IRVDeMenuPersoPrec: type=tBYTE, init-value=CONST_tBYTE_1:1
          PA28_SAV_CfgInitVitLvv1DeMenuPersoPrec: type=tBYTE, init-value=CONST_tBYTE_50:50
          PA28_SAV_CfgInitVitLvv1MilesDeMenuPersoPrec: type=tBYTE, init-value=CONST_tBYTE_32:32
          PA28_SAV_CfgInitVitLvv2DeMenuPersoPrec: type=tBYTE, init-value=CONST_tBYTE_70:70
          PA28_SAV_CfgInitVitLvv2MilesDeMenuPersoPrec: type=tBYTE, init-value=CONST_tBYTE_48:48
          PA28_SAV_CfgInitVitLvv3DeMenuPersoPrec: type=tBYTE, init-value=CONST_tBYTE_80:80
          PA28_SAV_CfgInitVitLvv3MilesDeMenuPersoPrec: type=tBYTE, init-value=CONST_tBYTE_64:64
          PA28_SAV_CfgInitVitLvv4DeMenuPersoPrec: type=tBYTE, init-value=CONST_tBYTE_90:90
          PA28_SAV_CfgInitVitLvv4MilesDeMenuPersoPrec: type=tBYTE, init-value=CONST_tBYTE_80:80
          PA28_SAV_CfgInitVitLvv5DeMenuPersoPrec: type=tBYTE, init-value=CONST_tBYTE_110:110
          PA28_SAV_CfgInitVitLvv5MilesDeMenuPersoPrec: type=tBYTE, init-value=CONST_tBYTE_96:96
          PA28_SAV_CfgInitVitLvv6DeMenuPersoPrec: type=tBYTE, init-value=CONST_tBYTE_130:130
          PA28_SAV_CfgInitVitLvv6MilesDeMenuPersoPrec: type=tBYTE, init-value=CONST_tBYTE_112:112
          PA28_SAV_CfgInitVitRvv1DeMenuPersoPrec: type=tBYTE, init-value=CONST_tBYTE_50:50
          PA28_SAV_CfgInitVitRvv1MilesDeMenuPersoPrec: type=tBYTE, init-value=CONST_tBYTE_48:48
          PA28_SAV_CfgInitVitRvv2DeMenuPersoPrec: type=tBYTE, init-value=CONST_tBYTE_70:70
          PA28_SAV_CfgInitVitRvv2MilesDeMenuPersoPrec: type=tBYTE, init-value=CONST_tBYTE_64:64
          PA28_SAV_CfgInitVitRvv3DeMenuPersoPrec: type=tBYTE, init-value=CONST_tBYTE_80:80
          PA28_SAV_CfgInitVitRvv3MilesDeMenuPersoPrec: type=tBYTE, init-value=CONST_tBYTE_80:80
          PA28_SAV_CfgInitVitRvv4DeMenuPersoPrec: type=tBYTE, init-value=CONST_tBYTE_90:90
          PA28_SAV_CfgInitVitRvv4MilesDeMenuPersoPrec: type=tBYTE, init-value=CONST_tBYTE_96:96
          PA28_SAV_CfgInitVitRvv5DeMenuPersoPrec: type=tBYTE, init-value=CONST_tBYTE_110:110
          PA28_SAV_CfgInitVitRvv5MilesDeMenuPersoPrec: type=tBYTE, init-value=CONST_tBYTE_112:112
          PA28_SAV_CfgInitVitRvv6DeMenuPersoPrec: type=tBYTE, init-value=CONST_tBYTE_130:130
          PA28_SAV_CfgInitVitRvv6MilesDeMenuPersoPrec: type=tBYTE, init-value=CONST_tBYTE_129:129
          PA28_SAV_CfgInitVitesse1XVVPrec: type=tBYTE, init-value=CONST_tBYTE_50:50
          PA28_SAV_CfgInitVitesse2XVVPrec: type=tBYTE, init-value=CONST_tBYTE_70:70
          PA28_SAV_CfgInitVitesse3XVVPrec: type=tBYTE, init-value=CONST_tBYTE_90:90
          PA28_SAV_CfgInitVitesse4XVVPrec: type=tBYTE, init-value=CONST_tBYTE_110:110
          PA28_SAV_CfgInitVitesse5XVVPrec: type=tBYTE, init-value=CONST_tBYTE_130:130
          PA28_SAV_CfgInitZCSelectDeMenuPersoPrec: type=tLOG, init-value=CONST_tLOG_0:0
          PA28_SAV_PremierDemarrageEffectue: type=tLOG, init-value=CONST_tLOG_0:0
          PA28_SAV_ToggleNewFrame15BPrec: type=tLOG, init-value=CONST_tLOG_0:0
          PA28_SAV_ToggleNewFrame25B29BPrec: type=tLOG, init-value=CONST_tLOG_0:0
          PA28_SAV_ToggleNewFrame2DBPrec: type=tLOG, init-value=CONST_tLOG_0:0
          PA28_SEC_DSGDeMenuPerso_Prec: type=tLOG, init-value=CONST_tLOG_0:0
          PA28_SurvGestToucheConfig: type=t_SurvGestToucheConfig, init-value=CONST_PA28_SurvGestToucheConfig_t_SurvGestToucheConfig_cAttenteAppui:0
          PA28_TAllumPlafDeVMF_HDC: type=tBYTE, init-value=CONST_tBYTE_0:0
          PA28_TempoDureeAppui: type=tBYTE, init-value=CONST_tBYTE_0:0
          PA28_TempoForcage_SEC_DSGDeMenuPerso: type=tWORD, init-value=CONST_tWORD_0:0
          PA28_TempoMaintienDonnees: type=tBYTE, init-value=CONST_tBYTE_0:0
      timing event RUNA_GererMenuPerso_Cyclic: start-on-event=RUNA_GererMenuPerso, period=0.1
        disabled-mode:
          ASWC_A28_MSI.AppMode.APP_CONFIG
          ASWC_A28_MSI.AppMode.APP_OFF
          ASWC_A28_MSI.AppMode.APP_SYNC_INIT
          ASWC_A28_MSI.AppMode.APP_WAKEUP
      swc mode switch event RUNI_A28_EXIT: start-on-event=RUNI_A28, activation=ON-EXIT, mode=ASWC_A28_MSI.AppMode.APP_WAKEUP
      swc mode switch event RUNPI_ASWC_A28_ENTRY: start-on-event=RUNPI_ASWC_A28, activation=ON-ENTRY, mode=ASWC_A28_MSI.AppMode.APP_WAKEUP
      runnable RUNA_GererMenuPerso
        data-read-access:
          441 x access:
            dra_AffMenuPrgPem: accessed-variable=RP_SR_AffMenuPrgPem.AffMenuPrgPem
            dra_AffMenuReserveZEV: accessed-variable=RP_SR_AffMenuReserveZEV.AffMenuReserveZEV
            dra_AppuiPushBEPR: accessed-variable=RP_SR_AppuiPushBEPR.AppuiPushBEPR
            dra_AppuiPushMPDParHDC: accessed-variable=RP_SR_AppuiPushMPDParHDC.AppuiPushMPDParHDC
            dra_AppuiToucheConfigDeVMF: accessed-variable=RP_SR_AppuiToucheConfigDeVMF.AppuiToucheConfigDeVMF
            dra_ButeeXvv{1..5}DeMenuPerso: accessed-variable=PRP_SR_ButeeXvv{1..5}DeMenuPerso.ButeeXvv{1..5}DeMenuPerso
            dra_CFG_MECATRONIC_HEADLAMP: accessed-variable=RP_SR_CFG_MECATRONIC_HEADLAMP.CFG_MECATRONIC_HEADLAMP
            dra_CFG_OPTION_MENU_FSE: accessed-variable=RP_SR_CFG_OPTION_MENU_FSE.CFG_OPTION_MENU_FSE
            dra_CFG_PRESENCE_AFS: accessed-variable=RP_SR_CFG_PRESENCE_AFS.CFG_PRESENCE_AFS
            dra_CFG_PRESENCE_ARC: accessed-variable=RP_SR_CFG_PRESENCE_ARC.CFG_PRESENCE_ARC
            dra_CFG_PRESENCE_FARC: accessed-variable=RP_SR_CFG_PRESENCE_FARC.CFG_PRESENCE_FARC
            dra_CFG_PRESENCE_MENU_PERSO: accessed-variable=RP_SR_CFG_PRESENCE_MENU_PERSO.CFG_PRESENCE_MENU_PERSO
            dra_CFG_PRESENCE_TO: accessed-variable=RP_SR_CFG_PRESENCE_TO.CFG_PRESENCE_TO
            dra_CFG_PRESENCE_TOUCHE_CONFIG: accessed-variable=RP_SR_CFG_PRESENCE_TOUCHE_CONFIG.CFG_PRESENCE_TOUCHE_CONFIG
            dra_CFG_TYPE_AAS: accessed-variable=RP_SR_CFG_TYPE_AAS.CFG_TYPE_AAS
            dra_CFG_TYPE_ACTIVATION_AFS: accessed-variable=RP_SR_CFG_TYPE_ACTIVATION_AFS.CFG_TYPE_ACTIVATION_AFS
            dra_CFG_TYPE_FSE: accessed-variable=RP_SR_CFG_TYPE_FSE.CFG_TYPE_FSE
            dra_CFG_TYPE_FUNCTIONAL_ABSD: accessed-variable=RP_SR_CFG_TYPE_FUNCTIONAL_ABSD.CFG_TYPE_FUNCTIONAL_ABSD
            dra_CondaRealiseePourCAN: accessed-variable=RP_SR_CondaRealiseePourCAN.CondaRealiseePourCAN
            dra_DdeAccesJDADeVMF: accessed-variable=PRP_SR_DdeAccesJDADeVMF.DdeAccesJDADeVMF
            dra_DdeAllumPlafDeVMF: accessed-variable=PRP_SR_DdeAllumPlafDeVMF.DdeAllumPlafDeVMF
            dra_DdeBlackPanelDeVMF: accessed-variable=PRP_SR_DdeBlackPanelDeVMF.DdeBlackPanelDeVMF
            dra_DdeCheckTcfg: accessed-variable=PRP_SR_DdeCheckTcfg.DdeCheckTcfg
            dra_DdeColorisationCMBDeVMF: accessed-variable=PRP_SR_DdeColorisationCMBDeVMF.DdeColorisationCMBDeVMF
            dra_DdeConfigToucheDeVMF: accessed-variable=PRP_SR_DdeConfigToucheDeVMF.DdeConfigToucheDeVMF
            dra_DdePersoCMBDeVMF: accessed-variable=PRP_SR_DdePersoCMBDeVMF.DdePersoCMBDeVMF
            dra_DispoDmdMenuPrecond: accessed-variable=PRP_SR_DispoDmdMenuPrecond.DispoDmdMenuPrecond
            dra_DispoDmdMenuPrgPem: accessed-variable=RP_SR_DispoDmdMenuPrgPem.DispoDmdMenuPrgPem
            dra_DispoDmdMenuRecharge: accessed-variable=PRP_SR_DispoDmdMenuRecharge.DispoDmdMenuRecharge
            dra_DispoEtatMenuPrgPem: accessed-variable=PRP_SR_DispoEtatMenuPrgPem.DispoEtatMenuPrgPem
            dra_DispoEtatMenuReserveZEV: accessed-variable=PRP_SR_DispoEtatMenuReserveZEV.DispoEtatMenuReserveZEV
            dra_DmdDispoDmdMenuReserveZEV: accessed-variable=RP_SR_DmdDispoDmdMenuReserveZEV.DmdDispoDmdMenuReserveZEV
            dra_DmdMenuARCSensNiv: accessed-variable=RP_SR_DmdMenuARCSensNiv.DmdMenuARCSensNiv
            dra_DmdMenuAccueilCond: accessed-variable=RP_SR_DmdMenuAccueilCond.DmdMenuAccueilCond
            dra_DmdMenuActButee{1..5}XVV: accessed-variable=RP_SR_DmdMenuActButee{1..5}XVV.DmdMenuActButee{1..5}XVV
            dra_DmdMenuActButeeGenXVV: accessed-variable=RP_SR_DmdMenuActButeeGenXVV.DmdMenuActButeeGenXVV
            dra_DmdMenuBAAActivation: accessed-variable=RP_SR_DmdMenuBAAActivation.DmdMenuBAAActivation
            dra_DmdMenuBAAAutolocking: accessed-variable=RP_SR_DmdMenuBAAAutolocking.DmdMenuBAAAutolocking
            dra_DmdMenuCLIM_PrecondDi{1..4}: accessed-variable=RP_SR_DmdMenuCLIM_PrecondDi{1..4}.DmdMenuCLIM_PrecondDi{1..4}
            dra_DmdMenuCLIM_PrecondH{1..4}: accessed-variable=RP_SR_DmdMenuCLIM_PrecondH{1..4}.DmdMenuCLIM_PrecondH{1..4}
            dra_DmdMenuCLIM_PrecondJe{1..4}: accessed-variable=RP_SR_DmdMenuCLIM_PrecondJe{1..4}.DmdMenuCLIM_PrecondJe{1..4}
            dra_DmdMenuCLIM_PrecondLu{1..4}: accessed-variable=RP_SR_DmdMenuCLIM_PrecondLu{1..4}.DmdMenuCLIM_PrecondLu{1..4}
            dra_DmdMenuCLIM_PrecondMa{1..4}: accessed-variable=RP_SR_DmdMenuCLIM_PrecondMa{1..4}.DmdMenuCLIM_PrecondMa{1..4}
            dra_DmdMenuCLIM_PrecondMe{1..4}: accessed-variable=RP_SR_DmdMenuCLIM_PrecondMe{1..4}.DmdMenuCLIM_PrecondMe{1..4}
            dra_DmdMenuCLIM_PrecondOn{1..4}: accessed-variable=RP_SR_DmdMenuCLIM_PrecondOn{1..4}.DmdMenuCLIM_PrecondOn{1..4}
            dra_DmdMenuCLIM_PrecondSa{1..4}: accessed-variable=RP_SR_DmdMenuCLIM_PrecondSa{1..4}.DmdMenuCLIM_PrecondSa{1..4}
            dra_DmdMenuCLIM_PrecondVe{1..4}: accessed-variable=RP_SR_DmdMenuCLIM_PrecondVe{1..4}.DmdMenuCLIM_PrecondVe{1..4}
            dra_DmdMenuCMDM_DAE: accessed-variable=RP_SR_DmdMenuCMDM_DAE.DmdMenuCMDM_DAE
            dra_DmdMenuCMDM_DAE_4WD: accessed-variable=RP_SR_DmdMenuCMDM_DAE_4WD.DmdMenuCMDM_DAE_4WD
            dra_DmdMenuClim_PrecondASAP: accessed-variable=RP_SR_DmdMenuClim_PrecondASAP.DmdMenuClim_PrecondASAP
            dra_DmdMenuDAAActivation: accessed-variable=RP_SR_DmdMenuDAAActivation.DmdMenuDAAActivation
            dra_DmdMenuDSG: accessed-variable=RP_SR_DmdMenuDSG.DmdMenuDSG
            dra_DmdMenuECLI_PPC_ANIM: accessed-variable=RP_SR_DmdMenuECLI_PPC_ANIM.DmdMenuECLI_PPC_ANIM
            dra_DmdMenuECLI_PPC_BLOC1: accessed-variable=RP_SR_DmdMenuECLI_PPC_BLOC1.DmdMenuECLI_PPC_BLOC1
            dra_DmdMenuECLI_PPC_COL1: accessed-variable=RP_SR_DmdMenuECLI_PPC_COL1.DmdMenuECLI_PPC_COL1
            dra_DmdMenuECLX_AFS: accessed-variable=RP_SR_DmdMenuECLX_AFS.DmdMenuECLX_AFS
            dra_DmdMenuECLX_ARS: accessed-variable=RP_SR_DmdMenuECLX_ARS.DmdMenuECLX_ARS
            dra_DmdMenuECLX_ECL_CAFR: accessed-variable=RP_SR_DmdMenuECLX_ECL_CAFR.DmdMenuECLX_ECL_CAFR
            dra_DmdMenuEclAccomp: accessed-variable=RP_SR_DmdMenuEclAccomp.DmdMenuEclAccomp
            dra_DmdMenuEclAccompTempo: accessed-variable=RP_SR_DmdMenuEclAccompTempo.DmdMenuEclAccompTempo
            dra_DmdMenuEclAdapt: accessed-variable=RP_SR_DmdMenuEclAdapt.DmdMenuEclAdapt
            dra_DmdMenuEclAmbi: accessed-variable=RP_SR_DmdMenuEclAmbi.DmdMenuEclAmbi
            dra_DmdMenuEclAmbiNiv: accessed-variable=RP_SR_DmdMenuEclAmbiNiv.DmdMenuEclAmbiNiv
            dra_DmdMenuEclAuto: accessed-variable=RP_SR_DmdMenuEclAuto.DmdMenuEclAuto
            dra_DmdMenuEclAutoroute: accessed-variable=RP_SR_DmdMenuEclAutoroute.DmdMenuEclAutoroute
            dra_DmdMenuEclCaland: accessed-variable=RP_SR_DmdMenuEclCaland.DmdMenuEclCaland
            dra_DmdMenuEclDeconda: accessed-variable=RP_SR_DmdMenuEclDeconda.DmdMenuEclDeconda
            dra_DmdMenuEclDecondaTempo: accessed-variable=RP_SR_DmdMenuEclDecondaTempo.DmdMenuEclDecondaTempo
            dra_DmdMenuEssuiVitMar: accessed-variable=RP_SR_DmdMenuEssuiVitMar.DmdMenuEssuiVitMar
            dra_DmdMenuFARC: accessed-variable=RP_SR_DmdMenuFARC.DmdMenuFARC
            dra_DmdMenuFSEAuto: accessed-variable=RP_SR_DmdMenuFSEAuto.DmdMenuFSEAuto
            dra_DmdMenuFeuxDiurne: accessed-variable=RP_SR_DmdMenuFeuxDiurne.DmdMenuFeuxDiurne
            dra_DmdMenuGAV_AMLA: accessed-variable=RP_SR_DmdMenuGAV_AMLA.DmdMenuGAV_AMLA
            dra_DmdMenuILV: accessed-variable=RP_SR_DmdMenuILV.DmdMenuILV
            dra_DmdMenuILV_ETSR: accessed-variable=RP_SR_DmdMenuILV_ETSR.DmdMenuILV_ETSR
            dra_DmdMenuIMA: accessed-variable=RP_SR_DmdMenuIMA.DmdMenuIMA
            dra_DmdMenuINV_ADSD: accessed-variable=RP_SR_DmdMenuINV_ADSD.DmdMenuINV_ADSD
            dra_DmdMenuInfoLvvDispo: accessed-variable=RP_SR_DmdMenuInfoLvvDispo.DmdMenuInfoLvvDispo
            dra_DmdMenuInfoParamDispo: accessed-variable=RP_SR_DmdMenuInfoParamDispo.DmdMenuInfoParamDispo
            dra_DmdMenuInfoPrecondDispo: accessed-variable=RP_SR_DmdMenuInfoPrecondDispo.DmdMenuInfoPrecondDispo
            dra_DmdMenuInfoRechargeDispo: accessed-variable=RP_SR_DmdMenuInfoRechargeDispo.DmdMenuInfoRechargeDispo
            dra_DmdMenuInfoRvvDispo: accessed-variable=RP_SR_DmdMenuInfoRvvDispo.DmdMenuInfoRvvDispo
            dra_DmdMenuInfoUniteLangueDispo: accessed-variable=RP_SR_DmdMenuInfoUniteLangueDispo.DmdMenuInfoUniteLangueDispo
            dra_DmdMenuInfoXVVDispo: accessed-variable=RP_SR_DmdMenuInfoXVVDispo.DmdMenuInfoXVVDispo
            dra_DmdMenuLangueVehicule: accessed-variable=RP_SR_DmdMenuLangueVehicule.DmdMenuLangueVehicule
            dra_DmdMenuMotoVolAr: accessed-variable=RP_SR_DmdMenuMotoVolAr.DmdMenuMotoVolAr
            dra_DmdMenuPRV_MODE: accessed-variable=RP_SR_DmdMenuPRV_MODE.DmdMenuPRV_MODE
            dra_DmdMenuPresenceARC: accessed-variable=RP_SR_DmdMenuPresenceARC.DmdMenuPresenceARC
            dra_DmdMenuPrgHcEnd: accessed-variable=RP_SR_DmdMenuPrgHcEnd.DmdMenuPrgHcEnd
            dra_DmdMenuPrgHcStart: accessed-variable=RP_SR_DmdMenuPrgHcStart.DmdMenuPrgHcStart
            dra_DmdMenuPrgPemDi: accessed-variable=RP_SR_DmdMenuPrgPemDi.DmdMenuPrgPemDi
            dra_DmdMenuPrgPemJe: accessed-variable=RP_SR_DmdMenuPrgPemJe.DmdMenuPrgPemJe
            dra_DmdMenuPrgPemLu: accessed-variable=RP_SR_DmdMenuPrgPemLu.DmdMenuPrgPemLu
            dra_DmdMenuPrgPemMa: accessed-variable=RP_SR_DmdMenuPrgPemMa.DmdMenuPrgPemMa
            dra_DmdMenuPrgPemMe: accessed-variable=RP_SR_DmdMenuPrgPemMe.DmdMenuPrgPemMe
            dra_DmdMenuPrgPemSa: accessed-variable=RP_SR_DmdMenuPrgPemSa.DmdMenuPrgPemSa
            dra_DmdMenuPrgPemVe: accessed-variable=RP_SR_DmdMenuPrgPemVe.DmdMenuPrgPemVe
            dra_DmdMenuRTAB_EnergyRec: accessed-variable=RP_SR_DmdMenuRTAB_EnergyRec.DmdMenuRTAB_EnergyRec
            dra_DmdMenuRTAB_RechargeHDeb: accessed-variable=RP_SR_DmdMenuRTAB_RechargeHDeb.DmdMenuRTAB_RechargeHDeb
            dra_DmdMenuRTAB_TypeRec: accessed-variable=RP_SR_DmdMenuRTAB_TypeRec.DmdMenuRTAB_TypeRec
            dra_DmdMenuReserveZEV: accessed-variable=RP_SR_DmdMenuReserveZEV.DmdMenuReserveZEV
            dra_DmdMenuSelPrgDi: accessed-variable=PRP_SR_DmdMenuSelPrgDi.DmdMenuSelPrgDi
            dra_DmdMenuSelPrgHc: accessed-variable=RP_SR_DmdMenuSelPrgHc.DmdMenuSelPrgHc
            dra_DmdMenuSelPrgJe: accessed-variable=PRP_SR_DmdMenuSelPrgJe.DmdMenuSelPrgJe
            dra_DmdMenuSelPrgLu: accessed-variable=PRP_SR_DmdMenuSelPrgLu.DmdMenuSelPrgLu
            dra_DmdMenuSelPrgMa: accessed-variable=PRP_SR_DmdMenuSelPrgMa.DmdMenuSelPrgMa
            dra_DmdMenuSelPrgMe: accessed-variable=PRP_SR_DmdMenuSelPrgMe.DmdMenuSelPrgMe
            dra_DmdMenuSelPrgSa: accessed-variable=PRP_SR_DmdMenuSelPrgSa.DmdMenuSelPrgSa
            dra_DmdMenuSelPrgVe: accessed-variable=PRP_SR_DmdMenuSelPrgVe.DmdMenuSelPrgVe
            dra_DmdMenuSelReserveZEV: accessed-variable=RP_SR_DmdMenuSelReserveZEV.DmdMenuSelReserveZEV
            dra_DmdMenuSelecArriere: accessed-variable=RP_SR_DmdMenuSelecArriere.DmdMenuSelecArriere
            dra_DmdMenuSelecCabine: accessed-variable=RP_SR_DmdMenuSelecCabine.DmdMenuSelecCabine
            dra_DmdMenuSelecOuvPlip: accessed-variable=RP_SR_DmdMenuSelecOuvPlip.DmdMenuSelecOuvPlip
            dra_DmdMenuSonPoly: accessed-variable=RP_SR_DmdMenuSonPoly.DmdMenuSonPoly
            dra_DmdMenuStatusAAS: accessed-variable=RP_SR_DmdMenuStatusAAS.DmdMenuStatusAAS
            dra_DmdMenuStatusSAM: accessed-variable=RP_SR_DmdMenuStatusSAM.DmdMenuStatusSAM
            dra_DmdMenuTCFG: accessed-variable=RP_SR_DmdMenuTCFG.DmdMenuTCFG
            dra_DmdMenuUniteConso: accessed-variable=RP_SR_DmdMenuUniteConso.DmdMenuUniteConso
            dra_DmdMenuUniteDistance: accessed-variable=RP_SR_DmdMenuUniteDistance.DmdMenuUniteDistance
            dra_DmdMenuUniteTemperature: accessed-variable=RP_SR_DmdMenuUniteTemperature.DmdMenuUniteTemperature
            dra_DmdMenuUniteVolume: accessed-variable=RP_SR_DmdMenuUniteVolume.DmdMenuUniteVolume
            dra_DmdMenuVAM_ECS_MODE: accessed-variable=RP_SR_DmdMenuVAM_ECS_MODE.DmdMenuVAM_ECS_MODE
            dra_DmdMenuVTOR_IRV: accessed-variable=RP_SR_DmdMenuVTOR_IRV.DmdMenuVTOR_IRV
            dra_DmdMenuVitLvv{1..6}: accessed-variable=RP_SR_DmdMenuVitLvv{1..6}.DmdMenuVitLvv{1..6}
            dra_DmdMenuVitRvv{1..6}: accessed-variable=RP_SR_DmdMenuVitRvv{1..6}.DmdMenuVitRvv{1..6}
            dra_DmdMenuVitesse{1..5}XVV: accessed-variable=RP_SR_DmdMenuVitesse{1..5}XVV.DmdMenuVitesse{1..5}XVV
            dra_DmdmCGEPVOffReserveZEV: accessed-variable=RP_SR_DmdmCGEPVOffReserveZEV.DmdmCGEPVOffReserveZEV
            dra_DmdmCGEPVReserveZEV: accessed-variable=PRP_SR_DmdmCGEPVReserveZEV.DmdmCGEPVReserveZEV
            dra_DmdmPrgHcEnd: accessed-variable=PRP_SR_DmdmPrgHcEnd.DmdmPrgHcEnd
            dra_DmdmPrgHcStart: accessed-variable=PRP_SR_DmdmPrgHcStart.DmdmPrgHcStart
            dra_DmdmPrgPemDi: accessed-variable=PRP_SR_DmdmPrgPemDi.DmdmPrgPemDi
            dra_DmdmPrgPemJe: accessed-variable=PRP_SR_DmdmPrgPemJe.DmdmPrgPemJe
            dra_DmdmPrgPemLu: accessed-variable=PRP_SR_DmdmPrgPemLu.DmdmPrgPemLu
            dra_DmdmPrgPemMa: accessed-variable=PRP_SR_DmdmPrgPemMa.DmdmPrgPemMa
            dra_DmdmPrgPemMe: accessed-variable=PRP_SR_DmdmPrgPemMe.DmdmPrgPemMe
            dra_DmdmPrgPemSa: accessed-variable=PRP_SR_DmdmPrgPemSa.DmdmPrgPemSa
            dra_DmdmPrgPemVe: accessed-variable=PRP_SR_DmdmPrgPemVe.DmdmPrgPemVe
            dra_EclAccompDeMenuPerso: accessed-variable=PRP_SR_EclAccompDeMenuPerso.EclAccompDeMenuPerso
            dra_EclDecondaDeMenuPerso: accessed-variable=PRP_SR_EclDecondaDeMenuPerso.EclDecondaDeMenuPerso
            dra_EtatMenuARCSensNiv: accessed-variable=PRP_SR_EtatMenuARCSensNiv.EtatMenuARCSensNiv
            dra_EtatMenuAccueilCond: accessed-variable=PRP_SR_EtatMenuAccueilCond.EtatMenuAccueilCond
            dra_EtatMenuActButee{1..5}XVV: accessed-variable=PRP_SR_EtatMenuActButee{1..5}XVV.EtatMenuActButee{1..5}XVV
            dra_EtatMenuActButeeGenXVV: accessed-variable=PRP_SR_EtatMenuActButeeGenXVV.EtatMenuActButeeGenXVV
            dra_EtatMenuBAAActivation: accessed-variable=PRP_SR_EtatMenuBAAActivation.EtatMenuBAAActivation
            dra_EtatMenuBAAAutolocking: accessed-variable=PRP_SR_EtatMenuBAAAutolocking.EtatMenuBAAAutolocking
            dra_EtatMenuCLIM_PrecondASAP: accessed-variable=PRP_SR_EtatMenuCLIM_PrecondASAP.EtatMenuCLIM_PrecondASAP
            dra_EtatMenuCLIM_PrecondDi{1..4}: accessed-variable=PRP_SR_EtatMenuCLIM_PrecondDi{1..4}.EtatMenuCLIM_PrecondDi{1..4}
            dra_EtatMenuCLIM_PrecondH{1..4}: accessed-variable=PRP_SR_EtatMenuCLIM_PrecondH{1..4}.EtatMenuCLIM_PrecondH{1..4}
            dra_EtatMenuCLIM_PrecondJe{1..4}: accessed-variable=PRP_SR_EtatMenuCLIM_PrecondJe{1..4}.EtatMenuCLIM_PrecondJe{1..4}
            dra_EtatMenuCLIM_PrecondLu{1..4}: accessed-variable=PRP_SR_EtatMenuCLIM_PrecondLu{1..4}.EtatMenuCLIM_PrecondLu{1..4}
            dra_EtatMenuCLIM_PrecondMa{1..4}: accessed-variable=PRP_SR_EtatMenuCLIM_PrecondMa{1..4}.EtatMenuCLIM_PrecondMa{1..4}
            dra_EtatMenuCLIM_PrecondMe{1..4}: accessed-variable=PRP_SR_EtatMenuCLIM_PrecondMe{1..4}.EtatMenuCLIM_PrecondMe{1..4}
            dra_EtatMenuCLIM_PrecondOn{1..4}: accessed-variable=PRP_SR_EtatMenuCLIM_PrecondOn{1..4}.EtatMenuCLIM_PrecondOn{1..4}
            dra_EtatMenuCLIM_PrecondSa{1..4}: accessed-variable=PRP_SR_EtatMenuCLIM_PrecondSa{1..4}.EtatMenuCLIM_PrecondSa{1..4}
            dra_EtatMenuCLIM_PrecondVe{1..4}: accessed-variable=PRP_SR_EtatMenuCLIM_PrecondVe{1..4}.EtatMenuCLIM_PrecondVe{1..4}
            dra_EtatMenuDAAActivation: accessed-variable=PRP_SR_EtatMenuDAAActivation.EtatMenuDAAActivation
            dra_EtatMenuDSG: accessed-variable=PRP_SR_EtatMenuDSG.EtatMenuDSG
            dra_EtatMenuECLI_PPC_ANIM: accessed-variable=PRP_SR_EtatMenuECLI_PPC_ANIM.EtatMenuECLI_PPC_ANIM
            dra_EtatMenuECLI_PPC_BLOC1: accessed-variable=PRP_SR_EtatMenuECLI_PPC_BLOC1.EtatMenuECLI_PPC_BLOC1
            dra_EtatMenuECLI_PPC_COL1: accessed-variable=PRP_SR_EtatMenuECLI_PPC_COL1.EtatMenuECLI_PPC_COL1
            dra_EtatMenuECLX_AFS: accessed-variable=PRP_SR_EtatMenuECLX_AFS.EtatMenuECLX_AFS
            dra_EtatMenuECLX_ARS: accessed-variable=PRP_SR_EtatMenuECLX_ARS.EtatMenuECLX_ARS
            dra_EtatMenuECLX_ECL_CAFR: accessed-variable=PRP_SR_EtatMenuECLX_ECL_CAFR.EtatMenuECLX_ECL_CAFR
            dra_EtatMenuEclAccomp: accessed-variable=PRP_SR_EtatMenuEclAccomp.EtatMenuEclAccomp
            dra_EtatMenuEclAccompTempo: accessed-variable=PRP_SR_EtatMenuEclAccompTempo.EtatMenuEclAccompTempo
            dra_EtatMenuEclAdapt: accessed-variable=PRP_SR_EtatMenuEclAdapt.EtatMenuEclAdapt
            dra_EtatMenuEclAmbi: accessed-variable=PRP_SR_EtatMenuEclAmbi.EtatMenuEclAmbi
            dra_EtatMenuEclAmbiNiv: accessed-variable=PRP_SR_EtatMenuEclAmbiNiv.EtatMenuEclAmbiNiv
            dra_EtatMenuEclAuto: accessed-variable=PRP_SR_EtatMenuEclAuto.EtatMenuEclAuto
            dra_EtatMenuEclAutoroute: accessed-variable=PRP_SR_EtatMenuEclAutoroute.EtatMenuEclAutoroute
            dra_EtatMenuEclCaland: accessed-variable=PRP_SR_EtatMenuEclCaland.EtatMenuEclCaland
            dra_EtatMenuEclDeconda: accessed-variable=PRP_SR_EtatMenuEclDeconda.EtatMenuEclDeconda
            dra_EtatMenuEclDecondaTempo: accessed-variable=PRP_SR_EtatMenuEclDecondaTempo.EtatMenuEclDecondaTempo
            dra_EtatMenuEssuiVitMar: accessed-variable=PRP_SR_EtatMenuEssuiVitMar.EtatMenuEssuiVitMar
            dra_EtatMenuFARC: accessed-variable=PRP_SR_EtatMenuFARC.EtatMenuFARC
            dra_EtatMenuFSEAuto: accessed-variable=PRP_SR_EtatMenuFSEAuto.EtatMenuFSEAuto
            dra_EtatMenuFeuxDiurne: accessed-variable=PRP_SR_EtatMenuFeuxDiurne.EtatMenuFeuxDiurne
            dra_EtatMenuGAV_AMLA: accessed-variable=PRP_SR_EtatMenuGAV_AMLA.EtatMenuGAV_AMLA
            dra_EtatMenuILV: accessed-variable=PRP_SR_EtatMenuILV.EtatMenuILV
            dra_EtatMenuILV_ETSR: accessed-variable=PRP_SR_EtatMenuILV_ETSR.EtatMenuILV_ETSR
            dra_EtatMenuIMA: accessed-variable=PRP_SR_EtatMenuIMA.EtatMenuIMA
            dra_EtatMenuINV_ADSD: accessed-variable=PRP_SR_EtatMenuINV_ADSD.EtatMenuINV_ADSD
            dra_EtatMenuInfoParamDispo: accessed-variable=PRP_SR_EtatMenuInfoParamDispo.EtatMenuInfoParamDispo
            dra_EtatMenuInfoUniteLangueDispo: accessed-variable=PRP_SR_EtatMenuInfoUniteLangueDispo.EtatMenuInfoUniteLangueDispo
            dra_EtatMenuInfoVitLvvDispo: accessed-variable=PRP_SR_EtatMenuInfoVitLvvDispo.EtatMenuInfoVitLvvDispo
            dra_EtatMenuInfoVitRvvDispo: accessed-variable=PRP_SR_EtatMenuInfoVitRvvDispo.EtatMenuInfoVitRvvDispo
            dra_EtatMenuInfoXVVDispo: accessed-variable=PRP_SR_EtatMenuInfoXVVDispo.EtatMenuInfoXVVDispo
            dra_EtatMenuLangueVehicule: accessed-variable=PRP_SR_EtatMenuLangueVehicule.EtatMenuLangueVehicule
            dra_EtatMenuMotoVolAr: accessed-variable=PRP_SR_EtatMenuMotoVolAr.EtatMenuMotoVolAr
            dra_EtatMenuPRV_MODE: accessed-variable=PRP_SR_EtatMenuPRV_MODE.EtatMenuPRV_MODE
            dra_EtatMenuPresenceARC: accessed-variable=PRP_SR_EtatMenuPresenceARC.EtatMenuPresenceARC
            dra_EtatMenuRTAB_EnergyRec: accessed-variable=PRP_SR_EtatMenuRTAB_EnergyRec.EtatMenuRTAB_EnergyRec
            dra_EtatMenuRTAB_RechargeHDeb: accessed-variable=PRP_SR_EtatMenuRTAB_RechargeHDeb.EtatMenuRTAB_RechargeHDeb
            dra_EtatMenuRTAB_TypeRec: accessed-variable=PRP_SR_EtatMenuRTAB_TypeRec.EtatMenuRTAB_TypeRec
            dra_EtatMenuReserveZEV: accessed-variable=PRP_SR_EtatMenuReserveZEV.EtatMenuReserveZEV
            dra_EtatMenuSelReserveZEV: accessed-variable=PRP_SR_EtatMenuSelReserveZEV.EtatMenuSelReserveZEV
            dra_EtatMenuSelecArriere: accessed-variable=PRP_SR_EtatMenuSelecArriere.EtatMenuSelecArriere
            dra_EtatMenuSelecCabine: accessed-variable=PRP_SR_EtatMenuSelecCabine.EtatMenuSelecCabine
            dra_EtatMenuSelecOuvPlip: accessed-variable=PRP_SR_EtatMenuSelecOuvPlip.EtatMenuSelecOuvPlip
            dra_EtatMenuSonPoly: accessed-variable=PRP_SR_EtatMenuSonPoly.EtatMenuSonPoly
            dra_EtatMenuStatusAAS: accessed-variable=PRP_SR_EtatMenuStatusAAS.EtatMenuStatusAAS
            dra_EtatMenuStatusSAM: accessed-variable=PRP_SR_EtatMenuStatusSAM.EtatMenuStatusSAM
            dra_EtatMenuTCFG: accessed-variable=PRP_SR_EtatMenuTCFG.EtatMenuTCFG
            dra_EtatMenuUniteConso: accessed-variable=PRP_SR_EtatMenuUniteConso.EtatMenuUniteConso
            dra_EtatMenuUniteDistance: accessed-variable=PRP_SR_EtatMenuUniteDistance.EtatMenuUniteDistance
            dra_EtatMenuUniteTemperature: accessed-variable=PRP_SR_EtatMenuUniteTemperature.EtatMenuUniteTemperature
            dra_EtatMenuUniteVolume: accessed-variable=PRP_SR_EtatMenuUniteVolume.EtatMenuUniteVolume
            dra_EtatMenuVTOR_IRV: accessed-variable=PRP_SR_EtatMenuVTOR_IRV.EtatMenuVTOR_IRV
            dra_EtatMenuVitLvv{1..6}: accessed-variable=PRP_SR_EtatMenuVitLvv{1..6}.EtatMenuVitLvv{1..6}
            dra_EtatMenuVitRvv{1..6}: accessed-variable=PRP_SR_EtatMenuVitRvv{1..6}.EtatMenuVitRvv{1..6}
            dra_EtatMenuVitesse{1..5}XVV: accessed-variable=PRP_SR_EtatMenuVitesse{1..5}XVV.EtatMenuVitesse{1..5}XVV
            dra_EtatPrincipalSEV: accessed-variable=RP_SR_EtatPrincipalSEV.EtatPrincipalSEV
            dra_MenuPersoMuet: accessed-variable=RP_SR_MenuPersoMuet.MenuPersoMuet
            dra_PhaseVieLS: accessed-variable=RP_SR_PhaseVieLS.PhaseVieLS
            dra_RechargeTypeStatus: accessed-variable=RP_SR_RechargeTypeStatus.RechargeTypeStatus
            dra_S360_Envoi: accessed-variable=PRP_SR_S360_Envoi.S360_Envoi
            dra_S360_OCTET_{1..8}: accessed-variable=PRP_SR_S360_OCTET_{1..8}.S360_OCTET_{1..8}
            dra_S3A0_Recu: accessed-variable=PRP_SR_S3A0_Recu.S3A0_Recu
            dra_SEC_AccueilDeMenuPerso: accessed-variable=PRP_SR_SEC_AccueilDeMenuPerso.SEC_AccueilDeMenuPerso
            dra_SEC_ActButee{1..5}XVV: accessed-variable=PRP_SR_SEC_ActButee{1..5}XVV.SEC_ActButee{1..5}XVV
            dra_SEC_ActButeeGenXVV: accessed-variable=PRP_SR_SEC_ActButeeGenXVV.SEC_ActButeeGenXVV
            dra_SEC_ActivationARCDeMenuPerso: accessed-variable=PRP_SR_SEC_ActivationARCDeMenuPerso.SEC_ActivationARCDeMenuPerso
            dra_SEC_BAAActivationDeMenuPerso: accessed-variable=PRP_SR_SEC_BAAActivationDeMenuPerso.SEC_BAAActivationDeMenuPerso
            dra_SEC_BAAAutolockingDeMenuPerso: accessed-variable=PRP_SR_SEC_BAAAutolockingDeMenuPerso.SEC_BAAAutolockingDeMenuPerso
            dra_SEC_CLIMPrecPrg{1..4}DeMenuPerso: accessed-variable=PRP_SR_SEC_CLIMPrecPrg{1..4}DeMenuPerso.SEC_CLIMPrecPrg{1..4}DeMenuPerso
            dra_SEC_CLIMPrecSem{1..4}DeMenuPerso: accessed-variable=PRP_SR_SEC_CLIMPrecSem{1..4}DeMenuPerso.SEC_CLIMPrecSem{1..4}DeMenuPerso
            dra_SEC_CLIM_PrecASAPDeMenuPerso: accessed-variable=PRP_SR_SEC_CLIM_PrecASAPDeMenuPerso.SEC_CLIM_PrecASAPDeMenuPerso
            dra_SEC_CLIM_PrecH{1..4}DeMenuPerso: accessed-variable=PRP_SR_SEC_CLIM_PrecH{1..4}DeMenuPerso.SEC_CLIM_PrecH{1..4}DeMenuPerso
            dra_SEC_CLIM_PrecOn{1..4}DeMenuPerso: accessed-variable=PRP_SR_SEC_CLIM_PrecOn{1..4}DeMenuPerso.SEC_CLIM_PrecOn{1..4}DeMenuPerso
            dra_SEC_CMDM_DAEDeMenuPerso: accessed-variable=PRP_SR_SEC_CMDM_DAEDeMenuPerso.SEC_CMDM_DAEDeMenuPerso
            dra_SEC_CMDM_DAE_4WDDeMenuPerso: accessed-variable=PRP_SR_SEC_CMDM_DAE_4WDDeMenuPerso.SEC_CMDM_DAE_4WDDeMenuPerso
            dra_SEC_DAAActivationDeMenuPerso: accessed-variable=PRP_SR_SEC_DAAActivationDeMenuPerso.SEC_DAAActivationDeMenuPerso
            dra_SEC_DSGDeMenuPerso: accessed-variable=PRP_SR_SEC_DSGDeMenuPerso.SEC_DSGDeMenuPerso
            dra_SEC_DecondaSelectDeMenuPerso: accessed-variable=PRP_SR_SEC_DecondaSelectDeMenuPerso.SEC_DecondaSelectDeMenuPerso
            dra_SEC_ECLI_PPC_ANIMDeMenuPerso: accessed-variable=PRP_SR_SEC_ECLI_PPC_ANIMDeMenuPerso.SEC_ECLI_PPC_ANIMDeMenuPerso
            dra_SEC_ECLI_PPC_BLOC1DeMenuPerso: accessed-variable=PRP_SR_SEC_ECLI_PPC_BLOC1DeMenuPerso.SEC_ECLI_PPC_BLOC1DeMenuPerso
            dra_SEC_ECLI_PPC_COL1DeMenuPerso: accessed-variable=PRP_SR_SEC_ECLI_PPC_COL1DeMenuPerso.SEC_ECLI_PPC_COL1DeMenuPerso
            dra_SEC_ECLX_ECL_CAFRDeMenuPerso: accessed-variable=PRP_SR_SEC_ECLX_ECL_CAFRDeMenuPerso.SEC_ECLX_ECL_CAFRDeMenuPerso
            dra_SEC_EclAFSDeMenuPerso: accessed-variable=PRP_SR_SEC_EclAFSDeMenuPerso.SEC_EclAFSDeMenuPerso
            dra_SEC_EclARSDeMenuPerso: accessed-variable=PRP_SR_SEC_EclARSDeMenuPerso.SEC_EclARSDeMenuPerso
            dra_SEC_EclAccomp: accessed-variable=PRP_SR_SEC_EclAccomp.SEC_EclAccomp
            dra_SEC_EclAccompTempo: accessed-variable=PRP_SR_SEC_EclAccompTempo.SEC_EclAccompTempo
            dra_SEC_EclAdaptDeMenuPerso: accessed-variable=PRP_SR_SEC_EclAdaptDeMenuPerso.SEC_EclAdaptDeMenuPerso
            dra_SEC_EclAmbiDeMenuPerso: accessed-variable=PRP_SR_SEC_EclAmbiDeMenuPerso.SEC_EclAmbiDeMenuPerso
            dra_SEC_EclAmbiNivDeMenuPerso: accessed-variable=PRP_SR_SEC_EclAmbiNivDeMenuPerso.SEC_EclAmbiNivDeMenuPerso
            dra_SEC_EclAutoDeMenuPerso: accessed-variable=PRP_SR_SEC_EclAutoDeMenuPerso.SEC_EclAutoDeMenuPerso
            dra_SEC_EclAutorouteDeMenuPerso: accessed-variable=PRP_SR_SEC_EclAutorouteDeMenuPerso.SEC_EclAutorouteDeMenuPerso
            dra_SEC_EclCalandDeMenuPerso: accessed-variable=PRP_SR_SEC_EclCalandDeMenuPerso.SEC_EclCalandDeMenuPerso
            dra_SEC_EclDeconda: accessed-variable=PRP_SR_SEC_EclDeconda.SEC_EclDeconda
            dra_SEC_EclDecondaTempo: accessed-variable=PRP_SR_SEC_EclDecondaTempo.SEC_EclDecondaTempo
            dra_SEC_EssuiVitMarDeMenuPerso: accessed-variable=PRP_SR_SEC_EssuiVitMarDeMenuPerso.SEC_EssuiVitMarDeMenuPerso
            dra_SEC_FARCDeMenuPerso: accessed-variable=PRP_SR_SEC_FARCDeMenuPerso.SEC_FARCDeMenuPerso
            dra_SEC_FSEAutoDeMenuPerso: accessed-variable=PRP_SR_SEC_FSEAutoDeMenuPerso.SEC_FSEAutoDeMenuPerso
            dra_SEC_FctToucheCfgDeMenuPerso: accessed-variable=PRP_SR_SEC_FctToucheCfgDeMenuPerso.SEC_FctToucheCfgDeMenuPerso
            dra_SEC_FeuxDiurneDeMenuPerso: accessed-variable=PRP_SR_SEC_FeuxDiurneDeMenuPerso.SEC_FeuxDiurneDeMenuPerso
            dra_SEC_GAV_AMLADeMenuPerso: accessed-variable=PRP_SR_SEC_GAV_AMLADeMenuPerso.SEC_GAV_AMLADeMenuPerso
            dra_SEC_ILVDeMenuPerso: accessed-variable=PRP_SR_SEC_ILVDeMenuPerso.SEC_ILVDeMenuPerso
            dra_SEC_ILV_ETSRDeMenuPerso: accessed-variable=PRP_SR_SEC_ILV_ETSRDeMenuPerso.SEC_ILV_ETSRDeMenuPerso
            dra_SEC_IMADeMenuPerso: accessed-variable=PRP_SR_SEC_IMADeMenuPerso.SEC_IMADeMenuPerso
            dra_SEC_INV_ADSDDeMenuPerso: accessed-variable=PRP_SR_SEC_INV_ADSDDeMenuPerso.SEC_INV_ADSDDeMenuPerso
            dra_SEC_InhibitionAASDeMenuPerso: accessed-variable=PRP_SR_SEC_InhibitionAASDeMenuPerso.SEC_InhibitionAASDeMenuPerso
            dra_SEC_InhibitionSAMDeMenuPerso: accessed-variable=PRP_SR_SEC_InhibitionSAMDeMenuPerso.SEC_InhibitionSAMDeMenuPerso
            dra_SEC_LangueVehicule: accessed-variable=PRP_SR_SEC_LangueVehicule.SEC_LangueVehicule
            dra_SEC_MotoVolArDeMenuPerso: accessed-variable=PRP_SR_SEC_MotoVolArDeMenuPerso.SEC_MotoVolArDeMenuPerso
            dra_SEC_PRV_MODEDeMenuPerso: accessed-variable=PRP_SR_SEC_PRV_MODEDeMenuPerso.SEC_PRV_MODEDeMenuPerso
            dra_SEC_PrgPemDiDeMenuPerso: accessed-variable=PRP_SR_SEC_PrgPemDiDeMenuPerso.SEC_PrgPemDiDeMenuPerso
            dra_SEC_PrgPemJeDeMenuPerso: accessed-variable=PRP_SR_SEC_PrgPemJeDeMenuPerso.SEC_PrgPemJeDeMenuPerso
            dra_SEC_PrgPemLuDeMenuPerso: accessed-variable=PRP_SR_SEC_PrgPemLuDeMenuPerso.SEC_PrgPemLuDeMenuPerso
            dra_SEC_PrgPemMaDeMenuPerso: accessed-variable=PRP_SR_SEC_PrgPemMaDeMenuPerso.SEC_PrgPemMaDeMenuPerso
            dra_SEC_PrgPemMeDeMenuPerso: accessed-variable=PRP_SR_SEC_PrgPemMeDeMenuPerso.SEC_PrgPemMeDeMenuPerso
            dra_SEC_PrgPemSaDeMenuPerso: accessed-variable=PRP_SR_SEC_PrgPemSaDeMenuPerso.SEC_PrgPemSaDeMenuPerso
            dra_SEC_PrgPemVeDeMenuPerso: accessed-variable=PRP_SR_SEC_PrgPemVeDeMenuPerso.SEC_PrgPemVeDeMenuPerso
            dra_SEC_RTABDeMenuPerso: accessed-variable=PRP_SR_SEC_RTABDeMenuPerso.SEC_RTABDeMenuPerso
            dra_SEC_RTAB_EnergyRecDeMenuPerso: accessed-variable=PRP_SR_SEC_RTAB_EnergyRecDeMenuPerso.SEC_RTAB_EnergyRecDeMenuPerso
            dra_SEC_RTAB_RecHDebDeMenuPerso: accessed-variable=PRP_SR_SEC_RTAB_RecHDebDeMenuPerso.SEC_RTAB_RecHDebDeMenuPerso
            dra_SEC_RTAB_TypeRecDeMenuPerso: accessed-variable=PRP_SR_SEC_RTAB_TypeRecDeMenuPerso.SEC_RTAB_TypeRecDeMenuPerso
            dra_SEC_ReserveZEVDeMenuPerso: accessed-variable=PRP_SR_SEC_ReserveZEVDeMenuPerso.SEC_ReserveZEVDeMenuPerso
            dra_SEC_SelReserveZEVDeMenuPerso: accessed-variable=PRP_SR_SEC_SelReserveZEVDeMenuPerso.SEC_SelReserveZEVDeMenuPerso
            dra_SEC_SelectOuvARDeMenuPerso: accessed-variable=PRP_SR_SEC_SelectOuvARDeMenuPerso.SEC_SelectOuvARDeMenuPerso
            dra_SEC_SensibiliteARCDeMenuPerso: accessed-variable=PRP_SR_SEC_SensibiliteARCDeMenuPerso.SEC_SensibiliteARCDeMenuPerso
            dra_SEC_SonPolyphDeMenuPerso: accessed-variable=PRP_SR_SEC_SonPolyphDeMenuPerso.SEC_SonPolyphDeMenuPerso
            dra_SEC_UniteConso: accessed-variable=PRP_SR_SEC_UniteConso.SEC_UniteConso
            dra_SEC_UniteDistance: accessed-variable=PRP_SR_SEC_UniteDistance.SEC_UniteDistance
            dra_SEC_UniteTemperature: accessed-variable=PRP_SR_SEC_UniteTemperature.SEC_UniteTemperature
            dra_SEC_UniteVolume: accessed-variable=PRP_SR_SEC_UniteVolume.SEC_UniteVolume
            dra_SEC_VAM_ECS_MODEDeMenuPerso: accessed-variable=PRP_SR_SEC_VAM_ECS_MODEDeMenuPerso.SEC_VAM_ECS_MODEDeMenuPerso
            dra_SEC_VTOR_IRVDeMenuPerso: accessed-variable=PRP_SR_SEC_VTOR_IRVDeMenuPerso.SEC_VTOR_IRVDeMenuPerso
            dra_SEC_VitLvv1DeMenuPerso: accessed-variable=PRP_SR_SEC_VitLvv1DeMenuPerso.SEC_VitLvv1DeMenuPerso
            dra_SEC_VitLvv1MilesDeMenuPerso: accessed-variable=PRP_SR_SEC_VitLvv1MilesDeMenuPerso.SEC_VitLvv1MilesDeMenuPerso
            dra_SEC_VitLvv2DeMenuPerso: accessed-variable=PRP_SR_SEC_VitLvv2DeMenuPerso.SEC_VitLvv2DeMenuPerso
            dra_SEC_VitLvv2MilesDeMenuPerso: accessed-variable=PRP_SR_SEC_VitLvv2MilesDeMenuPerso.SEC_VitLvv2MilesDeMenuPerso
            dra_SEC_VitLvv3DeMenuPerso: accessed-variable=PRP_SR_SEC_VitLvv3DeMenuPerso.SEC_VitLvv3DeMenuPerso
            dra_SEC_VitLvv3MilesDeMenuPerso: accessed-variable=PRP_SR_SEC_VitLvv3MilesDeMenuPerso.SEC_VitLvv3MilesDeMenuPerso
            dra_SEC_VitLvv4DeMenuPerso: accessed-variable=PRP_SR_SEC_VitLvv4DeMenuPerso.SEC_VitLvv4DeMenuPerso
            dra_SEC_VitLvv4MilesDeMenuPerso: accessed-variable=PRP_SR_SEC_VitLvv4MilesDeMenuPerso.SEC_VitLvv4MilesDeMenuPerso
            dra_SEC_VitLvv5DeMenuPerso: accessed-variable=PRP_SR_SEC_VitLvv5DeMenuPerso.SEC_VitLvv5DeMenuPerso
            dra_SEC_VitLvv5MilesDeMenuPerso: accessed-variable=PRP_SR_SEC_VitLvv5MilesDeMenuPerso.SEC_VitLvv5MilesDeMenuPerso
            dra_SEC_VitLvv6DeMenuPerso: accessed-variable=PRP_SR_SEC_VitLvv6DeMenuPerso.SEC_VitLvv6DeMenuPerso
            dra_SEC_VitLvv6MilesDeMenuPerso: accessed-variable=PRP_SR_SEC_VitLvv6MilesDeMenuPerso.SEC_VitLvv6MilesDeMenuPerso
            dra_SEC_VitRvv1DeMenuPerso: accessed-variable=PRP_SR_SEC_VitRvv1DeMenuPerso.SEC_VitRvv1DeMenuPerso
            dra_SEC_VitRvv1MilesDeMenuPerso: accessed-variable=PRP_SR_SEC_VitRvv1MilesDeMenuPerso.SEC_VitRvv1MilesDeMenuPerso
            dra_SEC_VitRvv2DeMenuPerso: accessed-variable=PRP_SR_SEC_VitRvv2DeMenuPerso.SEC_VitRvv2DeMenuPerso
            dra_SEC_VitRvv2MilesDeMenuPerso: accessed-variable=PRP_SR_SEC_VitRvv2MilesDeMenuPerso.SEC_VitRvv2MilesDeMenuPerso
            dra_SEC_VitRvv3DeMenuPerso: accessed-variable=PRP_SR_SEC_VitRvv3DeMenuPerso.SEC_VitRvv3DeMenuPerso
            dra_SEC_VitRvv3MilesDeMenuPerso: accessed-variable=PRP_SR_SEC_VitRvv3MilesDeMenuPerso.SEC_VitRvv3MilesDeMenuPerso
            dra_SEC_VitRvv4DeMenuPerso: accessed-variable=PRP_SR_SEC_VitRvv4DeMenuPerso.SEC_VitRvv4DeMenuPerso
            dra_SEC_VitRvv4MilesDeMenuPerso: accessed-variable=PRP_SR_SEC_VitRvv4MilesDeMenuPerso.SEC_VitRvv4MilesDeMenuPerso
            dra_SEC_VitRvv5DeMenuPerso: accessed-variable=PRP_SR_SEC_VitRvv5DeMenuPerso.SEC_VitRvv5DeMenuPerso
            dra_SEC_VitRvv5MilesDeMenuPerso: accessed-variable=PRP_SR_SEC_VitRvv5MilesDeMenuPerso.SEC_VitRvv5MilesDeMenuPerso
            dra_SEC_VitRvv6DeMenuPerso: accessed-variable=PRP_SR_SEC_VitRvv6DeMenuPerso.SEC_VitRvv6DeMenuPerso
            dra_SEC_VitRvv6MilesDeMenuPerso: accessed-variable=PRP_SR_SEC_VitRvv6MilesDeMenuPerso.SEC_VitRvv6MilesDeMenuPerso
            dra_SEC_Vitesse{1..5}XVV: accessed-variable=PRP_SR_SEC_Vitesse{1..5}XVV.SEC_Vitesse{1..5}XVV
            dra_SEC_ZCSelectDeMenuPerso: accessed-variable=PRP_SR_SEC_ZCSelectDeMenuPerso.SEC_ZCSelectDeMenuPerso
            dra_T28_APPUI_LONG_TOUCHE_CONF: accessed-variable=RP_SR_T28_APPUI_LONG_TOUCHE_CONF.T28_APPUI_LONG_TOUCHE_CONF
            dra_T28_MAINTIEN_DONNEES_TOUCHE: accessed-variable=RP_SR_T28_MAINTIEN_DONNEES_TOUCHE.T28_MAINTIEN_DONNEES_TOUCHE
            dra_ToggleNewFrame15B: accessed-variable=PRP_SR_ToggleNewFrame15B.ToggleNewFrame15B
            dra_ToggleNewFrame19B: accessed-variable=RP_SR_ToggleNewFrame19B.ToggleNewFrame19B
            dra_ToggleNewFrame1DB: accessed-variable=RP_SR_ToggleNewFrame1DB.ToggleNewFrame1DB
            dra_ToggleNewFrame25B29B: accessed-variable=RP_SR_ToggleNewFrame25B29B.ToggleNewFrame25B29B
            dra_ToggleNewFrame2DB: accessed-variable=RP_SR_ToggleNewFrame2DB.ToggleNewFrame2DB
        data-write-access:
          271 x access:
            dwa_ButeeXvv{1..5}DeMenuPerso: accessed-variable=PRP_SR_ButeeXvv{1..5}DeMenuPerso.ButeeXvv{1..5}DeMenuPerso
            dwa_DdeAccesJDADeVMF: accessed-variable=PRP_SR_DdeAccesJDADeVMF.DdeAccesJDADeVMF
            dwa_DdeAllumPlafDeVMF: accessed-variable=PRP_SR_DdeAllumPlafDeVMF.DdeAllumPlafDeVMF
            dwa_DdeBlackPanelDeVMF: accessed-variable=PRP_SR_DdeBlackPanelDeVMF.DdeBlackPanelDeVMF
            dwa_DdeCheckTcfg: accessed-variable=PRP_SR_DdeCheckTcfg.DdeCheckTcfg
            dwa_DdeColorisationCMBDeVMF: accessed-variable=PRP_SR_DdeColorisationCMBDeVMF.DdeColorisationCMBDeVMF
            dwa_DdeConfigToucheDeVMF: accessed-variable=PRP_SR_DdeConfigToucheDeVMF.DdeConfigToucheDeVMF
            dwa_DdePersoCMBDeVMF: accessed-variable=PRP_SR_DdePersoCMBDeVMF.DdePersoCMBDeVMF
            dwa_DispoDmdMenuPrecond: accessed-variable=PRP_SR_DispoDmdMenuPrecond.DispoDmdMenuPrecond
            dwa_DispoDmdMenuRecharge: accessed-variable=PRP_SR_DispoDmdMenuRecharge.DispoDmdMenuRecharge
            dwa_DispoEtatMenuPrgPem: accessed-variable=PRP_SR_DispoEtatMenuPrgPem.DispoEtatMenuPrgPem
            dwa_DispoEtatMenuReserveZEV: accessed-variable=PRP_SR_DispoEtatMenuReserveZEV.DispoEtatMenuReserveZEV
            dwa_DmdmCGEPVReserveZEV: accessed-variable=PRP_SR_DmdmCGEPVReserveZEV.DmdmCGEPVReserveZEV
            dwa_DmdmPrgHcEnd: accessed-variable=PRP_SR_DmdmPrgHcEnd.DmdmPrgHcEnd
            dwa_DmdmPrgHcStart: accessed-variable=PRP_SR_DmdmPrgHcStart.DmdmPrgHcStart
            dwa_DmdmPrgPemDi: accessed-variable=PRP_SR_DmdmPrgPemDi.DmdmPrgPemDi
            dwa_DmdmPrgPemJe: accessed-variable=PRP_SR_DmdmPrgPemJe.DmdmPrgPemJe
            dwa_DmdmPrgPemLu: accessed-variable=PRP_SR_DmdmPrgPemLu.DmdmPrgPemLu
            dwa_DmdmPrgPemMa: accessed-variable=PRP_SR_DmdmPrgPemMa.DmdmPrgPemMa
            dwa_DmdmPrgPemMe: accessed-variable=PRP_SR_DmdmPrgPemMe.DmdmPrgPemMe
            dwa_DmdmPrgPemSa: accessed-variable=PRP_SR_DmdmPrgPemSa.DmdmPrgPemSa
            dwa_DmdmPrgPemVe: accessed-variable=PRP_SR_DmdmPrgPemVe.DmdmPrgPemVe
            dwa_EclAccompDeMenuPerso: accessed-variable=PRP_SR_EclAccompDeMenuPerso.EclAccompDeMenuPerso
            dwa_EclDecondaDeMenuPerso: accessed-variable=PRP_SR_EclDecondaDeMenuPerso.EclDecondaDeMenuPerso
            dwa_EtatMenuARCSensNiv: accessed-variable=PRP_SR_EtatMenuARCSensNiv.EtatMenuARCSensNiv
            dwa_EtatMenuAccueilCond: accessed-variable=PRP_SR_EtatMenuAccueilCond.EtatMenuAccueilCond
            dwa_EtatMenuActButee{1..5}XVV: accessed-variable=PRP_SR_EtatMenuActButee{1..5}XVV.EtatMenuActButee{1..5}XVV
            dwa_EtatMenuActButeeGenXVV: accessed-variable=PRP_SR_EtatMenuActButeeGenXVV.EtatMenuActButeeGenXVV
            dwa_EtatMenuBAAActivation: accessed-variable=PRP_SR_EtatMenuBAAActivation.EtatMenuBAAActivation
            dwa_EtatMenuBAAAutolocking: accessed-variable=PRP_SR_EtatMenuBAAAutolocking.EtatMenuBAAAutolocking
            dwa_EtatMenuCLIM_PrecondASAP: accessed-variable=PRP_SR_EtatMenuCLIM_PrecondASAP.EtatMenuCLIM_PrecondASAP
            dwa_EtatMenuCLIM_PrecondDi{1..4}: accessed-variable=PRP_SR_EtatMenuCLIM_PrecondDi{1..4}.EtatMenuCLIM_PrecondDi{1..4}
            dwa_EtatMenuCLIM_PrecondH{1..4}: accessed-variable=PRP_SR_EtatMenuCLIM_PrecondH{1..4}.EtatMenuCLIM_PrecondH{1..4}
            dwa_EtatMenuCLIM_PrecondJe{1..4}: accessed-variable=PRP_SR_EtatMenuCLIM_PrecondJe{1..4}.EtatMenuCLIM_PrecondJe{1..4}
            dwa_EtatMenuCLIM_PrecondLu{1..4}: accessed-variable=PRP_SR_EtatMenuCLIM_PrecondLu{1..4}.EtatMenuCLIM_PrecondLu{1..4}
            dwa_EtatMenuCLIM_PrecondMa{1..4}: accessed-variable=PRP_SR_EtatMenuCLIM_PrecondMa{1..4}.EtatMenuCLIM_PrecondMa{1..4}
            dwa_EtatMenuCLIM_PrecondMe{1..4}: accessed-variable=PRP_SR_EtatMenuCLIM_PrecondMe{1..4}.EtatMenuCLIM_PrecondMe{1..4}
            dwa_EtatMenuCLIM_PrecondOn{1..4}: accessed-variable=PRP_SR_EtatMenuCLIM_PrecondOn{1..4}.EtatMenuCLIM_PrecondOn{1..4}
            dwa_EtatMenuCLIM_PrecondSa{1..4}: accessed-variable=PRP_SR_EtatMenuCLIM_PrecondSa{1..4}.EtatMenuCLIM_PrecondSa{1..4}
            dwa_EtatMenuCLIM_PrecondVe{1..4}: accessed-variable=PRP_SR_EtatMenuCLIM_PrecondVe{1..4}.EtatMenuCLIM_PrecondVe{1..4}
            dwa_EtatMenuDAAActivation: accessed-variable=PRP_SR_EtatMenuDAAActivation.EtatMenuDAAActivation
            dwa_EtatMenuDSG: accessed-variable=PRP_SR_EtatMenuDSG.EtatMenuDSG
            dwa_EtatMenuECLI_PPC_ANIM: accessed-variable=PRP_SR_EtatMenuECLI_PPC_ANIM.EtatMenuECLI_PPC_ANIM
            dwa_EtatMenuECLI_PPC_BLOC1: accessed-variable=PRP_SR_EtatMenuECLI_PPC_BLOC1.EtatMenuECLI_PPC_BLOC1
            dwa_EtatMenuECLI_PPC_COL1: accessed-variable=PRP_SR_EtatMenuECLI_PPC_COL1.EtatMenuECLI_PPC_COL1
            dwa_EtatMenuECLX_AFS: accessed-variable=PRP_SR_EtatMenuECLX_AFS.EtatMenuECLX_AFS
            dwa_EtatMenuECLX_ARS: accessed-variable=PRP_SR_EtatMenuECLX_ARS.EtatMenuECLX_ARS
            dwa_EtatMenuECLX_ECL_CAFR: accessed-variable=PRP_SR_EtatMenuECLX_ECL_CAFR.EtatMenuECLX_ECL_CAFR
            dwa_EtatMenuEclAccomp: accessed-variable=PRP_SR_EtatMenuEclAccomp.EtatMenuEclAccomp
            dwa_EtatMenuEclAccompTempo: accessed-variable=PRP_SR_EtatMenuEclAccompTempo.EtatMenuEclAccompTempo
            dwa_EtatMenuEclAdapt: accessed-variable=PRP_SR_EtatMenuEclAdapt.EtatMenuEclAdapt
            dwa_EtatMenuEclAmbi: accessed-variable=PRP_SR_EtatMenuEclAmbi.EtatMenuEclAmbi
            dwa_EtatMenuEclAmbiNiv: accessed-variable=PRP_SR_EtatMenuEclAmbiNiv.EtatMenuEclAmbiNiv
            dwa_EtatMenuEclAuto: accessed-variable=PRP_SR_EtatMenuEclAuto.EtatMenuEclAuto
            dwa_EtatMenuEclAutoroute: accessed-variable=PRP_SR_EtatMenuEclAutoroute.EtatMenuEclAutoroute
            dwa_EtatMenuEclCaland: accessed-variable=PRP_SR_EtatMenuEclCaland.EtatMenuEclCaland
            dwa_EtatMenuEclDeconda: accessed-variable=PRP_SR_EtatMenuEclDeconda.EtatMenuEclDeconda
            dwa_EtatMenuEclDecondaTempo: accessed-variable=PRP_SR_EtatMenuEclDecondaTempo.EtatMenuEclDecondaTempo
            dwa_EtatMenuEssuiVitMar: accessed-variable=PRP_SR_EtatMenuEssuiVitMar.EtatMenuEssuiVitMar
            dwa_EtatMenuFARC: accessed-variable=PRP_SR_EtatMenuFARC.EtatMenuFARC
            dwa_EtatMenuFSEAuto: accessed-variable=PRP_SR_EtatMenuFSEAuto.EtatMenuFSEAuto
            dwa_EtatMenuFeuxDiurne: accessed-variable=PRP_SR_EtatMenuFeuxDiurne.EtatMenuFeuxDiurne
            dwa_EtatMenuGAV_AMLA: accessed-variable=PRP_SR_EtatMenuGAV_AMLA.EtatMenuGAV_AMLA
            dwa_EtatMenuILV: accessed-variable=PRP_SR_EtatMenuILV.EtatMenuILV
            dwa_EtatMenuILV_ETSR: accessed-variable=PRP_SR_EtatMenuILV_ETSR.EtatMenuILV_ETSR
            dwa_EtatMenuIMA: accessed-variable=PRP_SR_EtatMenuIMA.EtatMenuIMA
            dwa_EtatMenuINV_ADSD: accessed-variable=PRP_SR_EtatMenuINV_ADSD.EtatMenuINV_ADSD
            dwa_EtatMenuInfoParamDispo: accessed-variable=PRP_SR_EtatMenuInfoParamDispo.EtatMenuInfoParamDispo
            dwa_EtatMenuInfoUniteLangueDispo: accessed-variable=PRP_SR_EtatMenuInfoUniteLangueDispo.EtatMenuInfoUniteLangueDispo
            dwa_EtatMenuInfoVitLvvDispo: accessed-variable=PRP_SR_EtatMenuInfoVitLvvDispo.EtatMenuInfoVitLvvDispo
            dwa_EtatMenuInfoVitRvvDispo: accessed-variable=PRP_SR_EtatMenuInfoVitRvvDispo.EtatMenuInfoVitRvvDispo
            dwa_EtatMenuInfoXVVDispo: accessed-variable=PRP_SR_EtatMenuInfoXVVDispo.EtatMenuInfoXVVDispo
            dwa_EtatMenuLangueVehicule: accessed-variable=PRP_SR_EtatMenuLangueVehicule.EtatMenuLangueVehicule
            dwa_EtatMenuMotoVolAr: accessed-variable=PRP_SR_EtatMenuMotoVolAr.EtatMenuMotoVolAr
            dwa_EtatMenuPRV_MODE: accessed-variable=PRP_SR_EtatMenuPRV_MODE.EtatMenuPRV_MODE
            dwa_EtatMenuPresenceARC: accessed-variable=PRP_SR_EtatMenuPresenceARC.EtatMenuPresenceARC
            dwa_EtatMenuRTAB_EnergyRec: accessed-variable=PRP_SR_EtatMenuRTAB_EnergyRec.EtatMenuRTAB_EnergyRec
            dwa_EtatMenuRTAB_RechargeHDeb: accessed-variable=PRP_SR_EtatMenuRTAB_RechargeHDeb.EtatMenuRTAB_RechargeHDeb
            dwa_EtatMenuRTAB_TypeRec: accessed-variable=PRP_SR_EtatMenuRTAB_TypeRec.EtatMenuRTAB_TypeRec
            dwa_EtatMenuReserveZEV: accessed-variable=PRP_SR_EtatMenuReserveZEV.EtatMenuReserveZEV
            dwa_EtatMenuSelReserveZEV: accessed-variable=PRP_SR_EtatMenuSelReserveZEV.EtatMenuSelReserveZEV
            dwa_EtatMenuSelecArriere: accessed-variable=PRP_SR_EtatMenuSelecArriere.EtatMenuSelecArriere
            dwa_EtatMenuSelecCabine: accessed-variable=PRP_SR_EtatMenuSelecCabine.EtatMenuSelecCabine
            dwa_EtatMenuSelecOuvPlip: accessed-variable=PRP_SR_EtatMenuSelecOuvPlip.EtatMenuSelecOuvPlip
            dwa_EtatMenuSonPoly: accessed-variable=PRP_SR_EtatMenuSonPoly.EtatMenuSonPoly
            dwa_EtatMenuStatusAAS: accessed-variable=PRP_SR_EtatMenuStatusAAS.EtatMenuStatusAAS
            dwa_EtatMenuStatusSAM: accessed-variable=PRP_SR_EtatMenuStatusSAM.EtatMenuStatusSAM
            dwa_EtatMenuTCFG: accessed-variable=PRP_SR_EtatMenuTCFG.EtatMenuTCFG
            dwa_EtatMenuUniteConso: accessed-variable=PRP_SR_EtatMenuUniteConso.EtatMenuUniteConso
            dwa_EtatMenuUniteDistance: accessed-variable=PRP_SR_EtatMenuUniteDistance.EtatMenuUniteDistance
            dwa_EtatMenuUniteTemperature: accessed-variable=PRP_SR_EtatMenuUniteTemperature.EtatMenuUniteTemperature
            dwa_EtatMenuUniteVolume: accessed-variable=PRP_SR_EtatMenuUniteVolume.EtatMenuUniteVolume
            dwa_EtatMenuVTOR_IRV: accessed-variable=PRP_SR_EtatMenuVTOR_IRV.EtatMenuVTOR_IRV
            dwa_EtatMenuVitLvv{1..6}: accessed-variable=PRP_SR_EtatMenuVitLvv{1..6}.EtatMenuVitLvv{1..6}
            dwa_EtatMenuVitRvv{1..6}: accessed-variable=PRP_SR_EtatMenuVitRvv{1..6}.EtatMenuVitRvv{1..6}
            dwa_EtatMenuVitesse{1..5}XVV: accessed-variable=PRP_SR_EtatMenuVitesse{1..5}XVV.EtatMenuVitesse{1..5}XVV
            dwa_S360_Envoi: accessed-variable=PRP_SR_S360_Envoi.S360_Envoi
            dwa_S360_OCTET_{1..8}: accessed-variable=PRP_SR_S360_OCTET_{1..8}.S360_OCTET_{1..8}
            dwa_S3A0_Recu: accessed-variable=PRP_SR_S3A0_Recu.S3A0_Recu
            dwa_SEC_AccueilDeMenuPerso: accessed-variable=PRP_SR_SEC_AccueilDeMenuPerso.SEC_AccueilDeMenuPerso
            dwa_SEC_ActButee{1..5}XVV: accessed-variable=PRP_SR_SEC_ActButee{1..5}XVV.SEC_ActButee{1..5}XVV
            dwa_SEC_ActButeeGenXVV: accessed-variable=PRP_SR_SEC_ActButeeGenXVV.SEC_ActButeeGenXVV
            dwa_SEC_ActivationARCDeMenuPerso: accessed-variable=PRP_SR_SEC_ActivationARCDeMenuPerso.SEC_ActivationARCDeMenuPerso
            dwa_SEC_BAAActivationDeMenuPerso: accessed-variable=PRP_SR_SEC_BAAActivationDeMenuPerso.SEC_BAAActivationDeMenuPerso
            dwa_SEC_BAAAutolockingDeMenuPerso: accessed-variable=PRP_SR_SEC_BAAAutolockingDeMenuPerso.SEC_BAAAutolockingDeMenuPerso
            dwa_SEC_CLIMPrecPrg{1..4}DeMenuPerso: accessed-variable=PRP_SR_SEC_CLIMPrecPrg{1..4}DeMenuPerso.SEC_CLIMPrecPrg{1..4}DeMenuPerso
            dwa_SEC_CLIMPrecSem{1..4}DeMenuPerso: accessed-variable=PRP_SR_SEC_CLIMPrecSem{1..4}DeMenuPerso.SEC_CLIMPrecSem{1..4}DeMenuPerso
            dwa_SEC_CLIM_PrecASAPDeMenuPerso: accessed-variable=PRP_SR_SEC_CLIM_PrecASAPDeMenuPerso.SEC_CLIM_PrecASAPDeMenuPerso
            dwa_SEC_CLIM_PrecH{1..4}DeMenuPerso: accessed-variable=PRP_SR_SEC_CLIM_PrecH{1..4}DeMenuPerso.SEC_CLIM_PrecH{1..4}DeMenuPerso
            dwa_SEC_CLIM_PrecOn{1..4}DeMenuPerso: accessed-variable=PRP_SR_SEC_CLIM_PrecOn{1..4}DeMenuPerso.SEC_CLIM_PrecOn{1..4}DeMenuPerso
            dwa_SEC_CMDM_DAEDeMenuPerso: accessed-variable=PRP_SR_SEC_CMDM_DAEDeMenuPerso.SEC_CMDM_DAEDeMenuPerso
            dwa_SEC_CMDM_DAE_4WDDeMenuPerso: accessed-variable=PRP_SR_SEC_CMDM_DAE_4WDDeMenuPerso.SEC_CMDM_DAE_4WDDeMenuPerso
            dwa_SEC_DAAActivationDeMenuPerso: accessed-variable=PRP_SR_SEC_DAAActivationDeMenuPerso.SEC_DAAActivationDeMenuPerso
            dwa_SEC_DSGDeMenuPerso: accessed-variable=PRP_SR_SEC_DSGDeMenuPerso.SEC_DSGDeMenuPerso
            dwa_SEC_DecondaSelectDeMenuPerso: accessed-variable=PRP_SR_SEC_DecondaSelectDeMenuPerso.SEC_DecondaSelectDeMenuPerso
            dwa_SEC_ECLI_PPC_ANIMDeMenuPerso: accessed-variable=PRP_SR_SEC_ECLI_PPC_ANIMDeMenuPerso.SEC_ECLI_PPC_ANIMDeMenuPerso
            dwa_SEC_ECLI_PPC_BLOC1DeMenuPerso: accessed-variable=PRP_SR_SEC_ECLI_PPC_BLOC1DeMenuPerso.SEC_ECLI_PPC_BLOC1DeMenuPerso
            dwa_SEC_ECLI_PPC_COL1DeMenuPerso: accessed-variable=PRP_SR_SEC_ECLI_PPC_COL1DeMenuPerso.SEC_ECLI_PPC_COL1DeMenuPerso
            dwa_SEC_ECLX_ECL_CAFRDeMenuPerso: accessed-variable=PRP_SR_SEC_ECLX_ECL_CAFRDeMenuPerso.SEC_ECLX_ECL_CAFRDeMenuPerso
            dwa_SEC_EclAFSDeMenuPerso: accessed-variable=PRP_SR_SEC_EclAFSDeMenuPerso.SEC_EclAFSDeMenuPerso
            dwa_SEC_EclARSDeMenuPerso: accessed-variable=PRP_SR_SEC_EclARSDeMenuPerso.SEC_EclARSDeMenuPerso
            dwa_SEC_EclAccomp: accessed-variable=PRP_SR_SEC_EclAccomp.SEC_EclAccomp
            dwa_SEC_EclAccompTempo: accessed-variable=PRP_SR_SEC_EclAccompTempo.SEC_EclAccompTempo
            dwa_SEC_EclAdaptDeMenuPerso: accessed-variable=PRP_SR_SEC_EclAdaptDeMenuPerso.SEC_EclAdaptDeMenuPerso
            dwa_SEC_EclAmbiDeMenuPerso: accessed-variable=PRP_SR_SEC_EclAmbiDeMenuPerso.SEC_EclAmbiDeMenuPerso
            dwa_SEC_EclAmbiNivDeMenuPerso: accessed-variable=PRP_SR_SEC_EclAmbiNivDeMenuPerso.SEC_EclAmbiNivDeMenuPerso
            dwa_SEC_EclAutoDeMenuPerso: accessed-variable=PRP_SR_SEC_EclAutoDeMenuPerso.SEC_EclAutoDeMenuPerso
            dwa_SEC_EclAutorouteDeMenuPerso: accessed-variable=PRP_SR_SEC_EclAutorouteDeMenuPerso.SEC_EclAutorouteDeMenuPerso
            dwa_SEC_EclCalandDeMenuPerso: accessed-variable=PRP_SR_SEC_EclCalandDeMenuPerso.SEC_EclCalandDeMenuPerso
            dwa_SEC_EclDeconda: accessed-variable=PRP_SR_SEC_EclDeconda.SEC_EclDeconda
            dwa_SEC_EclDecondaTempo: accessed-variable=PRP_SR_SEC_EclDecondaTempo.SEC_EclDecondaTempo
            dwa_SEC_EssuiVitMarDeMenuPerso: accessed-variable=PRP_SR_SEC_EssuiVitMarDeMenuPerso.SEC_EssuiVitMarDeMenuPerso
            dwa_SEC_FARCDeMenuPerso: accessed-variable=PRP_SR_SEC_FARCDeMenuPerso.SEC_FARCDeMenuPerso
            dwa_SEC_FSEAutoDeMenuPerso: accessed-variable=PRP_SR_SEC_FSEAutoDeMenuPerso.SEC_FSEAutoDeMenuPerso
            dwa_SEC_FctToucheCfgDeMenuPerso: accessed-variable=PRP_SR_SEC_FctToucheCfgDeMenuPerso.SEC_FctToucheCfgDeMenuPerso
            dwa_SEC_FeuxDiurneDeMenuPerso: accessed-variable=PRP_SR_SEC_FeuxDiurneDeMenuPerso.SEC_FeuxDiurneDeMenuPerso
            dwa_SEC_GAV_AMLADeMenuPerso: accessed-variable=PRP_SR_SEC_GAV_AMLADeMenuPerso.SEC_GAV_AMLADeMenuPerso
            dwa_SEC_ILVDeMenuPerso: accessed-variable=PRP_SR_SEC_ILVDeMenuPerso.SEC_ILVDeMenuPerso
            dwa_SEC_ILV_ETSRDeMenuPerso: accessed-variable=PRP_SR_SEC_ILV_ETSRDeMenuPerso.SEC_ILV_ETSRDeMenuPerso
            dwa_SEC_IMADeMenuPerso: accessed-variable=PRP_SR_SEC_IMADeMenuPerso.SEC_IMADeMenuPerso
            dwa_SEC_INV_ADSDDeMenuPerso: accessed-variable=PRP_SR_SEC_INV_ADSDDeMenuPerso.SEC_INV_ADSDDeMenuPerso
            dwa_SEC_InhibitionAASDeMenuPerso: accessed-variable=PRP_SR_SEC_InhibitionAASDeMenuPerso.SEC_InhibitionAASDeMenuPerso
            dwa_SEC_InhibitionSAMDeMenuPerso: accessed-variable=PRP_SR_SEC_InhibitionSAMDeMenuPerso.SEC_InhibitionSAMDeMenuPerso
            dwa_SEC_LangueVehicule: accessed-variable=PRP_SR_SEC_LangueVehicule.SEC_LangueVehicule
            dwa_SEC_MotoVolArDeMenuPerso: accessed-variable=PRP_SR_SEC_MotoVolArDeMenuPerso.SEC_MotoVolArDeMenuPerso
            dwa_SEC_PRV_MODEDeMenuPerso: accessed-variable=PRP_SR_SEC_PRV_MODEDeMenuPerso.SEC_PRV_MODEDeMenuPerso
            dwa_SEC_PrgPemDiDeMenuPerso: accessed-variable=PRP_SR_SEC_PrgPemDiDeMenuPerso.SEC_PrgPemDiDeMenuPerso
            dwa_SEC_PrgPemJeDeMenuPerso: accessed-variable=PRP_SR_SEC_PrgPemJeDeMenuPerso.SEC_PrgPemJeDeMenuPerso
            dwa_SEC_PrgPemLuDeMenuPerso: accessed-variable=PRP_SR_SEC_PrgPemLuDeMenuPerso.SEC_PrgPemLuDeMenuPerso
            dwa_SEC_PrgPemMaDeMenuPerso: accessed-variable=PRP_SR_SEC_PrgPemMaDeMenuPerso.SEC_PrgPemMaDeMenuPerso
            dwa_SEC_PrgPemMeDeMenuPerso: accessed-variable=PRP_SR_SEC_PrgPemMeDeMenuPerso.SEC_PrgPemMeDeMenuPerso
            dwa_SEC_PrgPemSaDeMenuPerso: accessed-variable=PRP_SR_SEC_PrgPemSaDeMenuPerso.SEC_PrgPemSaDeMenuPerso
            dwa_SEC_PrgPemVeDeMenuPerso: accessed-variable=PRP_SR_SEC_PrgPemVeDeMenuPerso.SEC_PrgPemVeDeMenuPerso
            dwa_SEC_RTABDeMenuPerso: accessed-variable=PRP_SR_SEC_RTABDeMenuPerso.SEC_RTABDeMenuPerso
            dwa_SEC_RTAB_EnergyRecDeMenuPerso: accessed-variable=PRP_SR_SEC_RTAB_EnergyRecDeMenuPerso.SEC_RTAB_EnergyRecDeMenuPerso
            dwa_SEC_RTAB_RecHDebDeMenuPerso: accessed-variable=PRP_SR_SEC_RTAB_RecHDebDeMenuPerso.SEC_RTAB_RecHDebDeMenuPerso
            dwa_SEC_RTAB_TypeRecDeMenuPerso: accessed-variable=PRP_SR_SEC_RTAB_TypeRecDeMenuPerso.SEC_RTAB_TypeRecDeMenuPerso
            dwa_SEC_ReserveZEVDeMenuPerso: accessed-variable=PRP_SR_SEC_ReserveZEVDeMenuPerso.SEC_ReserveZEVDeMenuPerso
            dwa_SEC_SelReserveZEVDeMenuPerso: accessed-variable=PRP_SR_SEC_SelReserveZEVDeMenuPerso.SEC_SelReserveZEVDeMenuPerso
            dwa_SEC_SelectOuvARDeMenuPerso: accessed-variable=PRP_SR_SEC_SelectOuvARDeMenuPerso.SEC_SelectOuvARDeMenuPerso
            dwa_SEC_SensibiliteARCDeMenuPerso: accessed-variable=PRP_SR_SEC_SensibiliteARCDeMenuPerso.SEC_SensibiliteARCDeMenuPerso
            dwa_SEC_SonPolyphDeMenuPerso: accessed-variable=PRP_SR_SEC_SonPolyphDeMenuPerso.SEC_SonPolyphDeMenuPerso
            dwa_SEC_UniteConso: accessed-variable=PRP_SR_SEC_UniteConso.SEC_UniteConso
            dwa_SEC_UniteDistance: accessed-variable=PRP_SR_SEC_UniteDistance.SEC_UniteDistance
            dwa_SEC_UniteTemperature: accessed-variable=PRP_SR_SEC_UniteTemperature.SEC_UniteTemperature
            dwa_SEC_UniteVolume: accessed-variable=PRP_SR_SEC_UniteVolume.SEC_UniteVolume
            dwa_SEC_VAM_ECS_MODEDeMenuPerso: accessed-variable=PRP_SR_SEC_VAM_ECS_MODEDeMenuPerso.SEC_VAM_ECS_MODEDeMenuPerso
            dwa_SEC_VTOR_IRVDeMenuPerso: accessed-variable=PRP_SR_SEC_VTOR_IRVDeMenuPerso.SEC_VTOR_IRVDeMenuPerso
            dwa_SEC_VitLvv1DeMenuPerso: accessed-variable=PRP_SR_SEC_VitLvv1DeMenuPerso.SEC_VitLvv1DeMenuPerso
            dwa_SEC_VitLvv1MilesDeMenuPerso: accessed-variable=PRP_SR_SEC_VitLvv1MilesDeMenuPerso.SEC_VitLvv1MilesDeMenuPerso
            dwa_SEC_VitLvv2DeMenuPerso: accessed-variable=PRP_SR_SEC_VitLvv2DeMenuPerso.SEC_VitLvv2DeMenuPerso
            dwa_SEC_VitLvv2MilesDeMenuPerso: accessed-variable=PRP_SR_SEC_VitLvv2MilesDeMenuPerso.SEC_VitLvv2MilesDeMenuPerso
            dwa_SEC_VitLvv3DeMenuPerso: accessed-variable=PRP_SR_SEC_VitLvv3DeMenuPerso.SEC_VitLvv3DeMenuPerso
            dwa_SEC_VitLvv3MilesDeMenuPerso: accessed-variable=PRP_SR_SEC_VitLvv3MilesDeMenuPerso.SEC_VitLvv3MilesDeMenuPerso
            dwa_SEC_VitLvv4DeMenuPerso: accessed-variable=PRP_SR_SEC_VitLvv4DeMenuPerso.SEC_VitLvv4DeMenuPerso
            dwa_SEC_VitLvv4MilesDeMenuPerso: accessed-variable=PRP_SR_SEC_VitLvv4MilesDeMenuPerso.SEC_VitLvv4MilesDeMenuPerso
            dwa_SEC_VitLvv5DeMenuPerso: accessed-variable=PRP_SR_SEC_VitLvv5DeMenuPerso.SEC_VitLvv5DeMenuPerso
            dwa_SEC_VitLvv5MilesDeMenuPerso: accessed-variable=PRP_SR_SEC_VitLvv5MilesDeMenuPerso.SEC_VitLvv5MilesDeMenuPerso
            dwa_SEC_VitLvv6DeMenuPerso: accessed-variable=PRP_SR_SEC_VitLvv6DeMenuPerso.SEC_VitLvv6DeMenuPerso
            dwa_SEC_VitLvv6MilesDeMenuPerso: accessed-variable=PRP_SR_SEC_VitLvv6MilesDeMenuPerso.SEC_VitLvv6MilesDeMenuPerso
            dwa_SEC_VitRvv1DeMenuPerso: accessed-variable=PRP_SR_SEC_VitRvv1DeMenuPerso.SEC_VitRvv1DeMenuPerso
            dwa_SEC_VitRvv1MilesDeMenuPerso: accessed-variable=PRP_SR_SEC_VitRvv1MilesDeMenuPerso.SEC_VitRvv1MilesDeMenuPerso
            dwa_SEC_VitRvv2DeMenuPerso: accessed-variable=PRP_SR_SEC_VitRvv2DeMenuPerso.SEC_VitRvv2DeMenuPerso
            dwa_SEC_VitRvv2MilesDeMenuPerso: accessed-variable=PRP_SR_SEC_VitRvv2MilesDeMenuPerso.SEC_VitRvv2MilesDeMenuPerso
            dwa_SEC_VitRvv3DeMenuPerso: accessed-variable=PRP_SR_SEC_VitRvv3DeMenuPerso.SEC_VitRvv3DeMenuPerso
            dwa_SEC_VitRvv3MilesDeMenuPerso: accessed-variable=PRP_SR_SEC_VitRvv3MilesDeMenuPerso.SEC_VitRvv3MilesDeMenuPerso
            dwa_SEC_VitRvv4DeMenuPerso: accessed-variable=PRP_SR_SEC_VitRvv4DeMenuPerso.SEC_VitRvv4DeMenuPerso
            dwa_SEC_VitRvv4MilesDeMenuPerso: accessed-variable=PRP_SR_SEC_VitRvv4MilesDeMenuPerso.SEC_VitRvv4MilesDeMenuPerso
            dwa_SEC_VitRvv5DeMenuPerso: accessed-variable=PRP_SR_SEC_VitRvv5DeMenuPerso.SEC_VitRvv5DeMenuPerso
            dwa_SEC_VitRvv5MilesDeMenuPerso: accessed-variable=PRP_SR_SEC_VitRvv5MilesDeMenuPerso.SEC_VitRvv5MilesDeMenuPerso
            dwa_SEC_VitRvv6DeMenuPerso: accessed-variable=PRP_SR_SEC_VitRvv6DeMenuPerso.SEC_VitRvv6DeMenuPerso
            dwa_SEC_VitRvv6MilesDeMenuPerso: accessed-variable=PRP_SR_SEC_VitRvv6MilesDeMenuPerso.SEC_VitRvv6MilesDeMenuPerso
            dwa_SEC_Vitesse{1..5}XVV: accessed-variable=PRP_SR_SEC_Vitesse{1..5}XVV.SEC_Vitesse{1..5}XVV
            dwa_SEC_ZCSelectDeMenuPerso: accessed-variable=PRP_SR_SEC_ZCSelectDeMenuPerso.SEC_ZCSelectDeMenuPerso
            dwa_ToggleNewFrame15B: accessed-variable=PRP_SR_ToggleNewFrame15B.ToggleNewFrame15B
        sync call sscp_RUNA_GererMenuPerso_CS_IsDataUpdated_Get_IsDataEnabled: operation=RP_CS_IsDataUpdated.Get_IsDataEnabled, timeout=0.0
      runnable RUNI_A28
        data-read-access:
          267 x access:
            dra_CFG_INIT_AAS: accessed-variable=RP_SR_CFG_INIT_AAS.CFG_INIT_AAS
            dra_CFG_INIT_ACCUEIL_COND: accessed-variable=RP_SR_CFG_INIT_ACCUEIL_COND.CFG_INIT_ACCUEIL_COND
            dra_CFG_INIT_BAAACTIVATION: accessed-variable=RP_SR_CFG_INIT_BAAACTIVATION.CFG_INIT_BAAACTIVATION
            dra_CFG_INIT_BAAAUTOLOCKING: accessed-variable=RP_SR_CFG_INIT_BAAAUTOLOCKING.CFG_INIT_BAAAUTOLOCKING
            dra_CFG_INIT_BUTEE_{1..5}: accessed-variable=RP_SR_CFG_INIT_BUTEE_{1..5}.CFG_INIT_BUTEE_{1..5}
            dra_CFG_INIT_BUTEE_GENERALE: accessed-variable=RP_SR_CFG_INIT_BUTEE_GENERALE.CFG_INIT_BUTEE_GENERALE
            dra_CFG_INIT_CALAND: accessed-variable=RP_SR_CFG_INIT_CALAND.CFG_INIT_CALAND
            dra_CFG_INIT_CLIM_PRECOND_ASAP: accessed-variable=RP_SR_CFG_INIT_CLIM_PRECOND_ASAP.CFG_INIT_CLIM_PRECOND_ASAP
            dra_CFG_INIT_CLIM_PRECOND_DI_{1..4}: accessed-variable=RP_SR_CFG_INIT_CLIM_PRECOND_DI_{1..4}.CFG_INIT_CLIM_PRECOND_DI_{1..4}
            dra_CFG_INIT_CLIM_PRECOND_H_{1..4}: accessed-variable=RP_SR_CFG_INIT_CLIM_PRECOND_H_{1..4}.CFG_INIT_CLIM_PRECOND_H_{1..4}
            dra_CFG_INIT_CLIM_PRECOND_JE_{1..4}: accessed-variable=RP_SR_CFG_INIT_CLIM_PRECOND_JE_{1..4}.CFG_INIT_CLIM_PRECOND_JE_{1..4}
            dra_CFG_INIT_CLIM_PRECOND_LU_{1..4}: accessed-variable=RP_SR_CFG_INIT_CLIM_PRECOND_LU_{1..4}.CFG_INIT_CLIM_PRECOND_LU_{1..4}
            dra_CFG_INIT_CLIM_PRECOND_MA_{1..4}: accessed-variable=RP_SR_CFG_INIT_CLIM_PRECOND_MA_{1..4}.CFG_INIT_CLIM_PRECOND_MA_{1..4}
            dra_CFG_INIT_CLIM_PRECOND_ME_{1..4}: accessed-variable=RP_SR_CFG_INIT_CLIM_PRECOND_ME_{1..4}.CFG_INIT_CLIM_PRECOND_ME_{1..4}
            dra_CFG_INIT_CLIM_PRECOND_ON_{1..4}: accessed-variable=RP_SR_CFG_INIT_CLIM_PRECOND_ON_{1..4}.CFG_INIT_CLIM_PRECOND_ON_{1..4}
            dra_CFG_INIT_CLIM_PRECOND_SA_{1..4}: accessed-variable=RP_SR_CFG_INIT_CLIM_PRECOND_SA_{1..4}.CFG_INIT_CLIM_PRECOND_SA_{1..4}
            dra_CFG_INIT_CLIM_PRECOND_VE_{1..4}: accessed-variable=RP_SR_CFG_INIT_CLIM_PRECOND_VE_{1..4}.CFG_INIT_CLIM_PRECOND_VE_{1..4}
            dra_CFG_INIT_DAAACTIVATION: accessed-variable=RP_SR_CFG_INIT_DAAACTIVATION.CFG_INIT_DAAACTIVATION
            dra_CFG_INIT_DSG: accessed-variable=RP_SR_CFG_INIT_DSG.CFG_INIT_DSG
            dra_CFG_INIT_ECLI_PPC_ANIM: accessed-variable=RP_SR_CFG_INIT_ECLI_PPC_ANIM.CFG_INIT_ECLI_PPC_ANIM
            dra_CFG_INIT_ECLI_PPC_BLOC1: accessed-variable=RP_SR_CFG_INIT_ECLI_PPC_BLOC1.CFG_INIT_ECLI_PPC_BLOC1
            dra_CFG_INIT_ECLI_PPC_COL1: accessed-variable=RP_SR_CFG_INIT_ECLI_PPC_COL1.CFG_INIT_ECLI_PPC_COL1
            dra_CFG_INIT_ECLX_AFS: accessed-variable=RP_SR_CFG_INIT_ECLX_AFS.CFG_INIT_ECLX_AFS
            dra_CFG_INIT_ECLX_ARS: accessed-variable=RP_SR_CFG_INIT_ECLX_ARS.CFG_INIT_ECLX_ARS
            dra_CFG_INIT_ECLX_ECL_CAFR: accessed-variable=RP_SR_CFG_INIT_ECLX_ECL_CAFR.CFG_INIT_ECLX_ECL_CAFR
            dra_CFG_INIT_ECL_ACCOMP: accessed-variable=RP_SR_CFG_INIT_ECL_ACCOMP.CFG_INIT_ECL_ACCOMP
            dra_CFG_INIT_ECL_ADAPT: accessed-variable=RP_SR_CFG_INIT_ECL_ADAPT.CFG_INIT_ECL_ADAPT
            dra_CFG_INIT_ECL_AMBI: accessed-variable=RP_SR_CFG_INIT_ECL_AMBI.CFG_INIT_ECL_AMBI
            dra_CFG_INIT_ECL_AMBI_NIV: accessed-variable=RP_SR_CFG_INIT_ECL_AMBI_NIV.CFG_INIT_ECL_AMBI_NIV
            dra_CFG_INIT_ECL_AUTO: accessed-variable=RP_SR_CFG_INIT_ECL_AUTO.CFG_INIT_ECL_AUTO
            dra_CFG_INIT_ECL_AUTOROUTE: accessed-variable=RP_SR_CFG_INIT_ECL_AUTOROUTE.CFG_INIT_ECL_AUTOROUTE
            dra_CFG_INIT_ECL_DECONDA: accessed-variable=RP_SR_CFG_INIT_ECL_DECONDA.CFG_INIT_ECL_DECONDA
            dra_CFG_INIT_ECL_FEUX_DIURNES: accessed-variable=RP_SR_CFG_INIT_ECL_FEUX_DIURNES.CFG_INIT_ECL_FEUX_DIURNES
            dra_CFG_INIT_ESSUIE_VIT_MAR: accessed-variable=RP_SR_CFG_INIT_ESSUIE_VIT_MAR.CFG_INIT_ESSUIE_VIT_MAR
            dra_CFG_INIT_FARC: accessed-variable=RP_SR_CFG_INIT_FARC.CFG_INIT_FARC
            dra_CFG_INIT_FSE_AUTO: accessed-variable=RP_SR_CFG_INIT_FSE_AUTO.CFG_INIT_FSE_AUTO
            dra_CFG_INIT_GAV_AMLA: accessed-variable=RP_SR_CFG_INIT_GAV_AMLA.CFG_INIT_GAV_AMLA
            dra_CFG_INIT_HARMONIE_SON: accessed-variable=RP_SR_CFG_INIT_HARMONIE_SON.CFG_INIT_HARMONIE_SON
            dra_CFG_INIT_ILV: accessed-variable=RP_SR_CFG_INIT_ILV.CFG_INIT_ILV
            dra_CFG_INIT_ILV_ETSR: accessed-variable=RP_SR_CFG_INIT_ILV_ETSR.CFG_INIT_ILV_ETSR
            dra_CFG_INIT_IMA: accessed-variable=RP_SR_CFG_INIT_IMA.CFG_INIT_IMA
            dra_CFG_INIT_INV_ADSD: accessed-variable=RP_SR_CFG_INIT_INV_ADSD.CFG_INIT_INV_ADSD
            dra_CFG_INIT_LANGUE_VHL: accessed-variable=RP_SR_CFG_INIT_LANGUE_VHL.CFG_INIT_LANGUE_VHL
            dra_CFG_INIT_MENU_PRG_PEM_DI: accessed-variable=RP_SR_CFG_INIT_MENU_PRG_PEM_DI.CFG_INIT_MENU_PRG_PEM_DI
            dra_CFG_INIT_MENU_PRG_PEM_JE: accessed-variable=RP_SR_CFG_INIT_MENU_PRG_PEM_JE.CFG_INIT_MENU_PRG_PEM_JE
            dra_CFG_INIT_MENU_PRG_PEM_LU: accessed-variable=RP_SR_CFG_INIT_MENU_PRG_PEM_LU.CFG_INIT_MENU_PRG_PEM_LU
            dra_CFG_INIT_MENU_PRG_PEM_MA: accessed-variable=RP_SR_CFG_INIT_MENU_PRG_PEM_MA.CFG_INIT_MENU_PRG_PEM_MA
            dra_CFG_INIT_MENU_PRG_PEM_ME: accessed-variable=RP_SR_CFG_INIT_MENU_PRG_PEM_ME.CFG_INIT_MENU_PRG_PEM_ME
            dra_CFG_INIT_MENU_PRG_PEM_SA: accessed-variable=RP_SR_CFG_INIT_MENU_PRG_PEM_SA.CFG_INIT_MENU_PRG_PEM_SA
            dra_CFG_INIT_MENU_PRG_PEM_VE: accessed-variable=RP_SR_CFG_INIT_MENU_PRG_PEM_VE.CFG_INIT_MENU_PRG_PEM_VE
            dra_CFG_INIT_MENU_SEL_PRG_PEM_DI: accessed-variable=RP_SR_CFG_INIT_MENU_SEL_PRG_PEM_DI.CFG_INIT_MENU_SEL_PRG_PEM_DI
            dra_CFG_INIT_MENU_SEL_PRG_PEM_JE: accessed-variable=RP_SR_CFG_INIT_MENU_SEL_PRG_PEM_JE.CFG_INIT_MENU_SEL_PRG_PEM_JE
            dra_CFG_INIT_MENU_SEL_PRG_PEM_LU: accessed-variable=RP_SR_CFG_INIT_MENU_SEL_PRG_PEM_LU.CFG_INIT_MENU_SEL_PRG_PEM_LU
            dra_CFG_INIT_MENU_SEL_PRG_PEM_MA: accessed-variable=RP_SR_CFG_INIT_MENU_SEL_PRG_PEM_MA.CFG_INIT_MENU_SEL_PRG_PEM_MA
            dra_CFG_INIT_MENU_SEL_PRG_PEM_ME: accessed-variable=RP_SR_CFG_INIT_MENU_SEL_PRG_PEM_ME.CFG_INIT_MENU_SEL_PRG_PEM_ME
            dra_CFG_INIT_MENU_SEL_PRG_PEM_SA: accessed-variable=RP_SR_CFG_INIT_MENU_SEL_PRG_PEM_SA.CFG_INIT_MENU_SEL_PRG_PEM_SA
            dra_CFG_INIT_MENU_SEL_PRG_PEM_VE: accessed-variable=RP_SR_CFG_INIT_MENU_SEL_PRG_PEM_VE.CFG_INIT_MENU_SEL_PRG_PEM_VE
            dra_CFG_INIT_MOTOR_VOLET: accessed-variable=RP_SR_CFG_INIT_MOTOR_VOLET.CFG_INIT_MOTOR_VOLET
            dra_CFG_INIT_PRESENCE_ARC: accessed-variable=RP_SR_CFG_INIT_PRESENCE_ARC.CFG_INIT_PRESENCE_ARC
            dra_CFG_INIT_PRV_MODE: accessed-variable=RP_SR_CFG_INIT_PRV_MODE.CFG_INIT_PRV_MODE
            dra_CFG_INIT_RESERVE_ZEV: accessed-variable=RP_SR_CFG_INIT_RESERVE_ZEV.CFG_INIT_RESERVE_ZEV
            dra_CFG_INIT_RTAB: accessed-variable=RP_SR_CFG_INIT_RTAB.CFG_INIT_RTAB
            dra_CFG_INIT_RTAB_ENERGY_REC: accessed-variable=RP_SR_CFG_INIT_RTAB_ENERGY_REC.CFG_INIT_RTAB_ENERGY_REC
            dra_CFG_INIT_RTAB_RECHARGE: accessed-variable=RP_SR_CFG_INIT_RTAB_RECHARGE.CFG_INIT_RTAB_RECHARGE
            dra_CFG_INIT_RTAB_RECHARGE_H_DEB: accessed-variable=RP_SR_CFG_INIT_RTAB_RECHARGE_H_DEB.CFG_INIT_RTAB_RECHARGE_H_DEB
            dra_CFG_INIT_RTAB_TYPE_REC: accessed-variable=RP_SR_CFG_INIT_RTAB_TYPE_REC.CFG_INIT_RTAB_TYPE_REC
            dra_CFG_INIT_SAM: accessed-variable=RP_SR_CFG_INIT_SAM.CFG_INIT_SAM
            dra_CFG_INIT_SELECTIVITE_CAB_ZC: accessed-variable=RP_SR_CFG_INIT_SELECTIVITE_CAB_ZC.CFG_INIT_SELECTIVITE_CAB_ZC
            dra_CFG_INIT_SELECTIVITE_COND: accessed-variable=RP_SR_CFG_INIT_SELECTIVITE_COND.CFG_INIT_SELECTIVITE_COND
            dra_CFG_INIT_SELECTIVITE_OUV_AR: accessed-variable=RP_SR_CFG_INIT_SELECTIVITE_OUV_AR.CFG_INIT_SELECTIVITE_OUV_AR
            dra_CFG_INIT_SEL_RESERVE_ZEV: accessed-variable=RP_SR_CFG_INIT_SEL_RESERVE_ZEV.CFG_INIT_SEL_RESERVE_ZEV
            dra_CFG_INIT_SENS_ARC_NIV: accessed-variable=RP_SR_CFG_INIT_SENS_ARC_NIV.CFG_INIT_SENS_ARC_NIV
            dra_CFG_INIT_TCFG: accessed-variable=RP_SR_CFG_INIT_TCFG.CFG_INIT_TCFG
            dra_CFG_INIT_TEMPO_ACCOMP: accessed-variable=RP_SR_CFG_INIT_TEMPO_ACCOMP.CFG_INIT_TEMPO_ACCOMP
            dra_CFG_INIT_TEMPO_DECONDA: accessed-variable=RP_SR_CFG_INIT_TEMPO_DECONDA.CFG_INIT_TEMPO_DECONDA
            dra_CFG_INIT_UNITE_CONSO: accessed-variable=RP_SR_CFG_INIT_UNITE_CONSO.CFG_INIT_UNITE_CONSO
            dra_CFG_INIT_UNITE_DISTANCE: accessed-variable=RP_SR_CFG_INIT_UNITE_DISTANCE.CFG_INIT_UNITE_DISTANCE
            dra_CFG_INIT_UNITE_TEMP: accessed-variable=RP_SR_CFG_INIT_UNITE_TEMP.CFG_INIT_UNITE_TEMP
            dra_CFG_INIT_UNITE_VOLUME: accessed-variable=RP_SR_CFG_INIT_UNITE_VOLUME.CFG_INIT_UNITE_VOLUME
            dra_CFG_INIT_VITESSE_{1..5}: accessed-variable=RP_SR_CFG_INIT_VITESSE_{1..5}.CFG_INIT_VITESSE_{1..5}
            dra_CFG_INIT_VIT_LVV_1: accessed-variable=RP_SR_CFG_INIT_VIT_LVV_1.CFG_INIT_VIT_LVV_1
            dra_CFG_INIT_VIT_LVV_1_Miles: accessed-variable=RP_SR_CFG_INIT_VIT_LVV_1_Miles.CFG_INIT_VIT_LVV_1_Miles
            dra_CFG_INIT_VIT_LVV_2: accessed-variable=RP_SR_CFG_INIT_VIT_LVV_2.CFG_INIT_VIT_LVV_2
            dra_CFG_INIT_VIT_LVV_2_Miles: accessed-variable=RP_SR_CFG_INIT_VIT_LVV_2_Miles.CFG_INIT_VIT_LVV_2_Miles
            dra_CFG_INIT_VIT_LVV_3: accessed-variable=RP_SR_CFG_INIT_VIT_LVV_3.CFG_INIT_VIT_LVV_3
            dra_CFG_INIT_VIT_LVV_3_Miles: accessed-variable=RP_SR_CFG_INIT_VIT_LVV_3_Miles.CFG_INIT_VIT_LVV_3_Miles
            dra_CFG_INIT_VIT_LVV_4: accessed-variable=RP_SR_CFG_INIT_VIT_LVV_4.CFG_INIT_VIT_LVV_4
            dra_CFG_INIT_VIT_LVV_4_Miles: accessed-variable=RP_SR_CFG_INIT_VIT_LVV_4_Miles.CFG_INIT_VIT_LVV_4_Miles
            dra_CFG_INIT_VIT_LVV_5: accessed-variable=RP_SR_CFG_INIT_VIT_LVV_5.CFG_INIT_VIT_LVV_5
            dra_CFG_INIT_VIT_LVV_5_Miles: accessed-variable=RP_SR_CFG_INIT_VIT_LVV_5_Miles.CFG_INIT_VIT_LVV_5_Miles
            dra_CFG_INIT_VIT_LVV_6: accessed-variable=RP_SR_CFG_INIT_VIT_LVV_6.CFG_INIT_VIT_LVV_6
            dra_CFG_INIT_VIT_LVV_6_Miles: accessed-variable=RP_SR_CFG_INIT_VIT_LVV_6_Miles.CFG_INIT_VIT_LVV_6_Miles
            dra_CFG_INIT_VIT_RVV_1: accessed-variable=RP_SR_CFG_INIT_VIT_RVV_1.CFG_INIT_VIT_RVV_1
            dra_CFG_INIT_VIT_RVV_1_Miles: accessed-variable=RP_SR_CFG_INIT_VIT_RVV_1_Miles.CFG_INIT_VIT_RVV_1_Miles
            dra_CFG_INIT_VIT_RVV_2: accessed-variable=RP_SR_CFG_INIT_VIT_RVV_2.CFG_INIT_VIT_RVV_2
            dra_CFG_INIT_VIT_RVV_2_Miles: accessed-variable=RP_SR_CFG_INIT_VIT_RVV_2_Miles.CFG_INIT_VIT_RVV_2_Miles
            dra_CFG_INIT_VIT_RVV_3: accessed-variable=RP_SR_CFG_INIT_VIT_RVV_3.CFG_INIT_VIT_RVV_3
            dra_CFG_INIT_VIT_RVV_3_Miles: accessed-variable=RP_SR_CFG_INIT_VIT_RVV_3_Miles.CFG_INIT_VIT_RVV_3_Miles
            dra_CFG_INIT_VIT_RVV_4: accessed-variable=RP_SR_CFG_INIT_VIT_RVV_4.CFG_INIT_VIT_RVV_4
            dra_CFG_INIT_VIT_RVV_4_Miles: accessed-variable=RP_SR_CFG_INIT_VIT_RVV_4_Miles.CFG_INIT_VIT_RVV_4_Miles
            dra_CFG_INIT_VIT_RVV_5: accessed-variable=RP_SR_CFG_INIT_VIT_RVV_5.CFG_INIT_VIT_RVV_5
            dra_CFG_INIT_VIT_RVV_5_Miles: accessed-variable=RP_SR_CFG_INIT_VIT_RVV_5_Miles.CFG_INIT_VIT_RVV_5_Miles
            dra_CFG_INIT_VIT_RVV_6: accessed-variable=RP_SR_CFG_INIT_VIT_RVV_6.CFG_INIT_VIT_RVV_6
            dra_CFG_INIT_VIT_RVV_6_Miles: accessed-variable=RP_SR_CFG_INIT_VIT_RVV_6_Miles.CFG_INIT_VIT_RVV_6_Miles
            dra_CFG_INIT_VTOR_IRV: accessed-variable=RP_SR_CFG_INIT_VTOR_IRV.CFG_INIT_VTOR_IRV
            dra_CFG_PRESENCE_FARC: accessed-variable=RP_SR_CFG_PRESENCE_FARC.CFG_PRESENCE_FARC
            dra_CFG_TYPE_FUNCTIONAL_ABSD: accessed-variable=RP_SR_CFG_TYPE_FUNCTIONAL_ABSD.CFG_TYPE_FUNCTIONAL_ABSD
            dra_CFG_TYPE_REGLAGE_SELECTIVITE: accessed-variable=RP_SR_CFG_TYPE_REGLAGE_SELECTIVITE.CFG_TYPE_REGLAGE_SELECTIVITE
            dra_CFG_TYPE_SELECTIVITE: accessed-variable=RP_SR_CFG_TYPE_SELECTIVITE.CFG_TYPE_SELECTIVITE
            dra_CFG_TYPE_SELECTIVITE_OUV_AR: accessed-variable=RP_SR_CFG_TYPE_SELECTIVITE_OUV_AR.CFG_TYPE_SELECTIVITE_OUV_AR
            dra_DmdMenuECLI_PPC_BLOC1: accessed-variable=RP_SR_DmdMenuECLI_PPC_BLOC1.DmdMenuECLI_PPC_BLOC1
            dra_DmdMenuSelPrgDi: accessed-variable=PRP_SR_DmdMenuSelPrgDi.DmdMenuSelPrgDi
            dra_DmdMenuSelPrgJe: accessed-variable=PRP_SR_DmdMenuSelPrgJe.DmdMenuSelPrgJe
            dra_DmdMenuSelPrgLu: accessed-variable=PRP_SR_DmdMenuSelPrgLu.DmdMenuSelPrgLu
            dra_DmdMenuSelPrgMa: accessed-variable=PRP_SR_DmdMenuSelPrgMa.DmdMenuSelPrgMa
            dra_DmdMenuSelPrgMe: accessed-variable=PRP_SR_DmdMenuSelPrgMe.DmdMenuSelPrgMe
            dra_DmdMenuSelPrgSa: accessed-variable=PRP_SR_DmdMenuSelPrgSa.DmdMenuSelPrgSa
            dra_DmdMenuSelPrgVe: accessed-variable=PRP_SR_DmdMenuSelPrgVe.DmdMenuSelPrgVe
            dra_EtatMenuECLI_PPC_BLOC1: accessed-variable=PRP_SR_EtatMenuECLI_PPC_BLOC1.EtatMenuECLI_PPC_BLOC1
            dra_EtatMenuECLX_AFS: accessed-variable=PRP_SR_EtatMenuECLX_AFS.EtatMenuECLX_AFS
            dra_EtatMenuECLX_ARS: accessed-variable=PRP_SR_EtatMenuECLX_ARS.EtatMenuECLX_ARS
            dra_SEC_AccueilDeMenuPerso: accessed-variable=PRP_SR_SEC_AccueilDeMenuPerso.SEC_AccueilDeMenuPerso
            dra_SEC_ActButee{1..5}XVV: accessed-variable=PRP_SR_SEC_ActButee{1..5}XVV.SEC_ActButee{1..5}XVV
            dra_SEC_ActButeeGenXVV: accessed-variable=PRP_SR_SEC_ActButeeGenXVV.SEC_ActButeeGenXVV
            dra_SEC_ActivationARCDeMenuPerso: accessed-variable=PRP_SR_SEC_ActivationARCDeMenuPerso.SEC_ActivationARCDeMenuPerso
            dra_SEC_BAAActivationDeMenuPerso: accessed-variable=PRP_SR_SEC_BAAActivationDeMenuPerso.SEC_BAAActivationDeMenuPerso
            dra_SEC_BAAAutolockingDeMenuPerso: accessed-variable=PRP_SR_SEC_BAAAutolockingDeMenuPerso.SEC_BAAAutolockingDeMenuPerso
            dra_SEC_CLIMPrecPrg{1..4}DeMenuPerso: accessed-variable=PRP_SR_SEC_CLIMPrecPrg{1..4}DeMenuPerso.SEC_CLIMPrecPrg{1..4}DeMenuPerso
            dra_SEC_CLIMPrecSem{1..4}DeMenuPerso: accessed-variable=PRP_SR_SEC_CLIMPrecSem{1..4}DeMenuPerso.SEC_CLIMPrecSem{1..4}DeMenuPerso
            dra_SEC_CLIM_PrecASAPDeMenuPerso: accessed-variable=PRP_SR_SEC_CLIM_PrecASAPDeMenuPerso.SEC_CLIM_PrecASAPDeMenuPerso
            dra_SEC_CLIM_PrecH{1..4}DeMenuPerso: accessed-variable=PRP_SR_SEC_CLIM_PrecH{1..4}DeMenuPerso.SEC_CLIM_PrecH{1..4}DeMenuPerso
            dra_SEC_CLIM_PrecOn{1..4}DeMenuPerso: accessed-variable=PRP_SR_SEC_CLIM_PrecOn{1..4}DeMenuPerso.SEC_CLIM_PrecOn{1..4}DeMenuPerso
            dra_SEC_DAAActivationDeMenuPerso: accessed-variable=PRP_SR_SEC_DAAActivationDeMenuPerso.SEC_DAAActivationDeMenuPerso
            dra_SEC_DSGDeMenuPerso: accessed-variable=PRP_SR_SEC_DSGDeMenuPerso.SEC_DSGDeMenuPerso
            dra_SEC_DecondaSelectDeMenuPerso: accessed-variable=PRP_SR_SEC_DecondaSelectDeMenuPerso.SEC_DecondaSelectDeMenuPerso
            dra_SEC_ECLI_PPC_ANIMDeMenuPerso: accessed-variable=PRP_SR_SEC_ECLI_PPC_ANIMDeMenuPerso.SEC_ECLI_PPC_ANIMDeMenuPerso
            dra_SEC_ECLI_PPC_BLOC1DeMenuPerso: accessed-variable=PRP_SR_SEC_ECLI_PPC_BLOC1DeMenuPerso.SEC_ECLI_PPC_BLOC1DeMenuPerso
            dra_SEC_ECLI_PPC_COL1DeMenuPerso: accessed-variable=PRP_SR_SEC_ECLI_PPC_COL1DeMenuPerso.SEC_ECLI_PPC_COL1DeMenuPerso
            dra_SEC_ECLX_ECL_CAFRDeMenuPerso: accessed-variable=PRP_SR_SEC_ECLX_ECL_CAFRDeMenuPerso.SEC_ECLX_ECL_CAFRDeMenuPerso
            dra_SEC_EclAFSDeMenuPerso: accessed-variable=PRP_SR_SEC_EclAFSDeMenuPerso.SEC_EclAFSDeMenuPerso
            dra_SEC_EclARSDeMenuPerso: accessed-variable=PRP_SR_SEC_EclARSDeMenuPerso.SEC_EclARSDeMenuPerso
            dra_SEC_EclAccomp: accessed-variable=PRP_SR_SEC_EclAccomp.SEC_EclAccomp
            dra_SEC_EclAccompTempo: accessed-variable=PRP_SR_SEC_EclAccompTempo.SEC_EclAccompTempo
            dra_SEC_EclAdaptDeMenuPerso: accessed-variable=PRP_SR_SEC_EclAdaptDeMenuPerso.SEC_EclAdaptDeMenuPerso
            dra_SEC_EclAmbiDeMenuPerso: accessed-variable=PRP_SR_SEC_EclAmbiDeMenuPerso.SEC_EclAmbiDeMenuPerso
            dra_SEC_EclAmbiNivDeMenuPerso: accessed-variable=PRP_SR_SEC_EclAmbiNivDeMenuPerso.SEC_EclAmbiNivDeMenuPerso
            dra_SEC_EclAutoDeMenuPerso: accessed-variable=PRP_SR_SEC_EclAutoDeMenuPerso.SEC_EclAutoDeMenuPerso
            dra_SEC_EclAutorouteDeMenuPerso: accessed-variable=PRP_SR_SEC_EclAutorouteDeMenuPerso.SEC_EclAutorouteDeMenuPerso
            dra_SEC_EclCalandDeMenuPerso: accessed-variable=PRP_SR_SEC_EclCalandDeMenuPerso.SEC_EclCalandDeMenuPerso
            dra_SEC_EclDeconda: accessed-variable=PRP_SR_SEC_EclDeconda.SEC_EclDeconda
            dra_SEC_EclDecondaTempo: accessed-variable=PRP_SR_SEC_EclDecondaTempo.SEC_EclDecondaTempo
            dra_SEC_EssuiVitMarDeMenuPerso: accessed-variable=PRP_SR_SEC_EssuiVitMarDeMenuPerso.SEC_EssuiVitMarDeMenuPerso
            dra_SEC_FARCDeMenuPerso: accessed-variable=PRP_SR_SEC_FARCDeMenuPerso.SEC_FARCDeMenuPerso
            dra_SEC_FSEAutoDeMenuPerso: accessed-variable=PRP_SR_SEC_FSEAutoDeMenuPerso.SEC_FSEAutoDeMenuPerso
            dra_SEC_FctToucheCfgDeMenuPerso: accessed-variable=PRP_SR_SEC_FctToucheCfgDeMenuPerso.SEC_FctToucheCfgDeMenuPerso
            dra_SEC_FeuxDiurneDeMenuPerso: accessed-variable=PRP_SR_SEC_FeuxDiurneDeMenuPerso.SEC_FeuxDiurneDeMenuPerso
            dra_SEC_GAV_AMLADeMenuPerso: accessed-variable=PRP_SR_SEC_GAV_AMLADeMenuPerso.SEC_GAV_AMLADeMenuPerso
            dra_SEC_ILVDeMenuPerso: accessed-variable=PRP_SR_SEC_ILVDeMenuPerso.SEC_ILVDeMenuPerso
            dra_SEC_ILV_ETSRDeMenuPerso: accessed-variable=PRP_SR_SEC_ILV_ETSRDeMenuPerso.SEC_ILV_ETSRDeMenuPerso
            dra_SEC_IMADeMenuPerso: accessed-variable=PRP_SR_SEC_IMADeMenuPerso.SEC_IMADeMenuPerso
            dra_SEC_INV_ADSDDeMenuPerso: accessed-variable=PRP_SR_SEC_INV_ADSDDeMenuPerso.SEC_INV_ADSDDeMenuPerso
            dra_SEC_InhibitionAASDeMenuPerso: accessed-variable=PRP_SR_SEC_InhibitionAASDeMenuPerso.SEC_InhibitionAASDeMenuPerso
            dra_SEC_InhibitionSAMDeMenuPerso: accessed-variable=PRP_SR_SEC_InhibitionSAMDeMenuPerso.SEC_InhibitionSAMDeMenuPerso
            dra_SEC_LangueVehicule: accessed-variable=PRP_SR_SEC_LangueVehicule.SEC_LangueVehicule
            dra_SEC_MotoVolArDeMenuPerso: accessed-variable=PRP_SR_SEC_MotoVolArDeMenuPerso.SEC_MotoVolArDeMenuPerso
            dra_SEC_PRV_MODEDeMenuPerso: accessed-variable=PRP_SR_SEC_PRV_MODEDeMenuPerso.SEC_PRV_MODEDeMenuPerso
            dra_SEC_PrgPemDiDeMenuPerso: accessed-variable=PRP_SR_SEC_PrgPemDiDeMenuPerso.SEC_PrgPemDiDeMenuPerso
            dra_SEC_PrgPemJeDeMenuPerso: accessed-variable=PRP_SR_SEC_PrgPemJeDeMenuPerso.SEC_PrgPemJeDeMenuPerso
            dra_SEC_PrgPemLuDeMenuPerso: accessed-variable=PRP_SR_SEC_PrgPemLuDeMenuPerso.SEC_PrgPemLuDeMenuPerso
            dra_SEC_PrgPemMaDeMenuPerso: accessed-variable=PRP_SR_SEC_PrgPemMaDeMenuPerso.SEC_PrgPemMaDeMenuPerso
            dra_SEC_PrgPemMeDeMenuPerso: accessed-variable=PRP_SR_SEC_PrgPemMeDeMenuPerso.SEC_PrgPemMeDeMenuPerso
            dra_SEC_PrgPemSaDeMenuPerso: accessed-variable=PRP_SR_SEC_PrgPemSaDeMenuPerso.SEC_PrgPemSaDeMenuPerso
            dra_SEC_PrgPemVeDeMenuPerso: accessed-variable=PRP_SR_SEC_PrgPemVeDeMenuPerso.SEC_PrgPemVeDeMenuPerso
            dra_SEC_RTAB_EnergyRecDeMenuPerso: accessed-variable=PRP_SR_SEC_RTAB_EnergyRecDeMenuPerso.SEC_RTAB_EnergyRecDeMenuPerso
            dra_SEC_RTAB_RecHDebDeMenuPerso: accessed-variable=PRP_SR_SEC_RTAB_RecHDebDeMenuPerso.SEC_RTAB_RecHDebDeMenuPerso
            dra_SEC_RTAB_TypeRecDeMenuPerso: accessed-variable=PRP_SR_SEC_RTAB_TypeRecDeMenuPerso.SEC_RTAB_TypeRecDeMenuPerso
            dra_SEC_ReserveZEVDeMenuPerso: accessed-variable=PRP_SR_SEC_ReserveZEVDeMenuPerso.SEC_ReserveZEVDeMenuPerso
            dra_SEC_SelReserveZEVDeMenuPerso: accessed-variable=PRP_SR_SEC_SelReserveZEVDeMenuPerso.SEC_SelReserveZEVDeMenuPerso
            dra_SEC_SelectOuvARDeMenuPerso: accessed-variable=PRP_SR_SEC_SelectOuvARDeMenuPerso.SEC_SelectOuvARDeMenuPerso
            dra_SEC_SensibiliteARCDeMenuPerso: accessed-variable=PRP_SR_SEC_SensibiliteARCDeMenuPerso.SEC_SensibiliteARCDeMenuPerso
            dra_SEC_SonPolyphDeMenuPerso: accessed-variable=PRP_SR_SEC_SonPolyphDeMenuPerso.SEC_SonPolyphDeMenuPerso
            dra_SEC_UniteConso: accessed-variable=PRP_SR_SEC_UniteConso.SEC_UniteConso
            dra_SEC_UniteDistance: accessed-variable=PRP_SR_SEC_UniteDistance.SEC_UniteDistance
            dra_SEC_UniteTemperature: accessed-variable=PRP_SR_SEC_UniteTemperature.SEC_UniteTemperature
            dra_SEC_UniteVolume: accessed-variable=PRP_SR_SEC_UniteVolume.SEC_UniteVolume
            dra_SEC_VTOR_IRVDeMenuPerso: accessed-variable=PRP_SR_SEC_VTOR_IRVDeMenuPerso.SEC_VTOR_IRVDeMenuPerso
            dra_SEC_VitLvv1DeMenuPerso: accessed-variable=PRP_SR_SEC_VitLvv1DeMenuPerso.SEC_VitLvv1DeMenuPerso
            dra_SEC_VitLvv1MilesDeMenuPerso: accessed-variable=PRP_SR_SEC_VitLvv1MilesDeMenuPerso.SEC_VitLvv1MilesDeMenuPerso
            dra_SEC_VitLvv2DeMenuPerso: accessed-variable=PRP_SR_SEC_VitLvv2DeMenuPerso.SEC_VitLvv2DeMenuPerso
            dra_SEC_VitLvv2MilesDeMenuPerso: accessed-variable=PRP_SR_SEC_VitLvv2MilesDeMenuPerso.SEC_VitLvv2MilesDeMenuPerso
            dra_SEC_VitLvv3DeMenuPerso: accessed-variable=PRP_SR_SEC_VitLvv3DeMenuPerso.SEC_VitLvv3DeMenuPerso
            dra_SEC_VitLvv3MilesDeMenuPerso: accessed-variable=PRP_SR_SEC_VitLvv3MilesDeMenuPerso.SEC_VitLvv3MilesDeMenuPerso
            dra_SEC_VitLvv4DeMenuPerso: accessed-variable=PRP_SR_SEC_VitLvv4DeMenuPerso.SEC_VitLvv4DeMenuPerso
            dra_SEC_VitLvv4MilesDeMenuPerso: accessed-variable=PRP_SR_SEC_VitLvv4MilesDeMenuPerso.SEC_VitLvv4MilesDeMenuPerso
            dra_SEC_VitLvv5DeMenuPerso: accessed-variable=PRP_SR_SEC_VitLvv5DeMenuPerso.SEC_VitLvv5DeMenuPerso
            dra_SEC_VitLvv5MilesDeMenuPerso: accessed-variable=PRP_SR_SEC_VitLvv5MilesDeMenuPerso.SEC_VitLvv5MilesDeMenuPerso
            dra_SEC_VitLvv6DeMenuPerso: accessed-variable=PRP_SR_SEC_VitLvv6DeMenuPerso.SEC_VitLvv6DeMenuPerso
            dra_SEC_VitLvv6MilesDeMenuPerso: accessed-variable=PRP_SR_SEC_VitLvv6MilesDeMenuPerso.SEC_VitLvv6MilesDeMenuPerso
            dra_SEC_VitRvv1DeMenuPerso: accessed-variable=PRP_SR_SEC_VitRvv1DeMenuPerso.SEC_VitRvv1DeMenuPerso
            dra_SEC_VitRvv1MilesDeMenuPerso: accessed-variable=PRP_SR_SEC_VitRvv1MilesDeMenuPerso.SEC_VitRvv1MilesDeMenuPerso
            dra_SEC_VitRvv2DeMenuPerso: accessed-variable=PRP_SR_SEC_VitRvv2DeMenuPerso.SEC_VitRvv2DeMenuPerso
            dra_SEC_VitRvv2MilesDeMenuPerso: accessed-variable=PRP_SR_SEC_VitRvv2MilesDeMenuPerso.SEC_VitRvv2MilesDeMenuPerso
            dra_SEC_VitRvv3DeMenuPerso: accessed-variable=PRP_SR_SEC_VitRvv3DeMenuPerso.SEC_VitRvv3DeMenuPerso
            dra_SEC_VitRvv3MilesDeMenuPerso: accessed-variable=PRP_SR_SEC_VitRvv3MilesDeMenuPerso.SEC_VitRvv3MilesDeMenuPerso
            dra_SEC_VitRvv4DeMenuPerso: accessed-variable=PRP_SR_SEC_VitRvv4DeMenuPerso.SEC_VitRvv4DeMenuPerso
            dra_SEC_VitRvv4MilesDeMenuPerso: accessed-variable=PRP_SR_SEC_VitRvv4MilesDeMenuPerso.SEC_VitRvv4MilesDeMenuPerso
            dra_SEC_VitRvv5DeMenuPerso: accessed-variable=PRP_SR_SEC_VitRvv5DeMenuPerso.SEC_VitRvv5DeMenuPerso
            dra_SEC_VitRvv5MilesDeMenuPerso: accessed-variable=PRP_SR_SEC_VitRvv5MilesDeMenuPerso.SEC_VitRvv5MilesDeMenuPerso
            dra_SEC_VitRvv6DeMenuPerso: accessed-variable=PRP_SR_SEC_VitRvv6DeMenuPerso.SEC_VitRvv6DeMenuPerso
            dra_SEC_VitRvv6MilesDeMenuPerso: accessed-variable=PRP_SR_SEC_VitRvv6MilesDeMenuPerso.SEC_VitRvv6MilesDeMenuPerso
            dra_SEC_Vitesse{1..5}XVV: accessed-variable=PRP_SR_SEC_Vitesse{1..5}XVV.SEC_Vitesse{1..5}XVV
            dra_SEC_ZCSelectDeMenuPerso: accessed-variable=PRP_SR_SEC_ZCSelectDeMenuPerso.SEC_ZCSelectDeMenuPerso
        data-write-access:
          121 x access:
            dwa_DmdMenuSelPrgDi: accessed-variable=PRP_SR_DmdMenuSelPrgDi.DmdMenuSelPrgDi
            dwa_DmdMenuSelPrgJe: accessed-variable=PRP_SR_DmdMenuSelPrgJe.DmdMenuSelPrgJe
            dwa_DmdMenuSelPrgLu: accessed-variable=PRP_SR_DmdMenuSelPrgLu.DmdMenuSelPrgLu
            dwa_DmdMenuSelPrgMa: accessed-variable=PRP_SR_DmdMenuSelPrgMa.DmdMenuSelPrgMa
            dwa_DmdMenuSelPrgMe: accessed-variable=PRP_SR_DmdMenuSelPrgMe.DmdMenuSelPrgMe
            dwa_DmdMenuSelPrgSa: accessed-variable=PRP_SR_DmdMenuSelPrgSa.DmdMenuSelPrgSa
            dwa_DmdMenuSelPrgVe: accessed-variable=PRP_SR_DmdMenuSelPrgVe.DmdMenuSelPrgVe
            dwa_EtatMenuECLI_PPC_BLOC1: accessed-variable=PRP_SR_EtatMenuECLI_PPC_BLOC1.EtatMenuECLI_PPC_BLOC1
            dwa_EtatMenuECLX_AFS: accessed-variable=PRP_SR_EtatMenuECLX_AFS.EtatMenuECLX_AFS
            dwa_EtatMenuECLX_ARS: accessed-variable=PRP_SR_EtatMenuECLX_ARS.EtatMenuECLX_ARS
            dwa_SEC_AccueilDeMenuPerso: accessed-variable=PRP_SR_SEC_AccueilDeMenuPerso.SEC_AccueilDeMenuPerso
            dwa_SEC_ActButee{1..5}XVV: accessed-variable=PRP_SR_SEC_ActButee{1..5}XVV.SEC_ActButee{1..5}XVV
            dwa_SEC_ActButeeGenXVV: accessed-variable=PRP_SR_SEC_ActButeeGenXVV.SEC_ActButeeGenXVV
            dwa_SEC_ActivationARCDeMenuPerso: accessed-variable=PRP_SR_SEC_ActivationARCDeMenuPerso.SEC_ActivationARCDeMenuPerso
            dwa_SEC_BAAActivationDeMenuPerso: accessed-variable=PRP_SR_SEC_BAAActivationDeMenuPerso.SEC_BAAActivationDeMenuPerso
            dwa_SEC_BAAAutolockingDeMenuPerso: accessed-variable=PRP_SR_SEC_BAAAutolockingDeMenuPerso.SEC_BAAAutolockingDeMenuPerso
            dwa_SEC_CLIMPrecPrg{1..4}DeMenuPerso: accessed-variable=PRP_SR_SEC_CLIMPrecPrg{1..4}DeMenuPerso.SEC_CLIMPrecPrg{1..4}DeMenuPerso
            dwa_SEC_CLIMPrecSem{1..4}DeMenuPerso: accessed-variable=PRP_SR_SEC_CLIMPrecSem{1..4}DeMenuPerso.SEC_CLIMPrecSem{1..4}DeMenuPerso
            dwa_SEC_CLIM_PrecASAPDeMenuPerso: accessed-variable=PRP_SR_SEC_CLIM_PrecASAPDeMenuPerso.SEC_CLIM_PrecASAPDeMenuPerso
            dwa_SEC_CLIM_PrecH{1..4}DeMenuPerso: accessed-variable=PRP_SR_SEC_CLIM_PrecH{1..4}DeMenuPerso.SEC_CLIM_PrecH{1..4}DeMenuPerso
            dwa_SEC_CLIM_PrecOn{1..4}DeMenuPerso: accessed-variable=PRP_SR_SEC_CLIM_PrecOn{1..4}DeMenuPerso.SEC_CLIM_PrecOn{1..4}DeMenuPerso
            dwa_SEC_DAAActivationDeMenuPerso: accessed-variable=PRP_SR_SEC_DAAActivationDeMenuPerso.SEC_DAAActivationDeMenuPerso
            dwa_SEC_DSGDeMenuPerso: accessed-variable=PRP_SR_SEC_DSGDeMenuPerso.SEC_DSGDeMenuPerso
            dwa_SEC_DecondaSelectDeMenuPerso: accessed-variable=PRP_SR_SEC_DecondaSelectDeMenuPerso.SEC_DecondaSelectDeMenuPerso
            dwa_SEC_ECLI_PPC_ANIMDeMenuPerso: accessed-variable=PRP_SR_SEC_ECLI_PPC_ANIMDeMenuPerso.SEC_ECLI_PPC_ANIMDeMenuPerso
            dwa_SEC_ECLI_PPC_BLOC1DeMenuPerso: accessed-variable=PRP_SR_SEC_ECLI_PPC_BLOC1DeMenuPerso.SEC_ECLI_PPC_BLOC1DeMenuPerso
            dwa_SEC_ECLI_PPC_COL1DeMenuPerso: accessed-variable=PRP_SR_SEC_ECLI_PPC_COL1DeMenuPerso.SEC_ECLI_PPC_COL1DeMenuPerso
            dwa_SEC_ECLX_ECL_CAFRDeMenuPerso: accessed-variable=PRP_SR_SEC_ECLX_ECL_CAFRDeMenuPerso.SEC_ECLX_ECL_CAFRDeMenuPerso
            dwa_SEC_EclAFSDeMenuPerso: accessed-variable=PRP_SR_SEC_EclAFSDeMenuPerso.SEC_EclAFSDeMenuPerso
            dwa_SEC_EclARSDeMenuPerso: accessed-variable=PRP_SR_SEC_EclARSDeMenuPerso.SEC_EclARSDeMenuPerso
            dwa_SEC_EclAccomp: accessed-variable=PRP_SR_SEC_EclAccomp.SEC_EclAccomp
            dwa_SEC_EclAccompTempo: accessed-variable=PRP_SR_SEC_EclAccompTempo.SEC_EclAccompTempo
            dwa_SEC_EclAdaptDeMenuPerso: accessed-variable=PRP_SR_SEC_EclAdaptDeMenuPerso.SEC_EclAdaptDeMenuPerso
            dwa_SEC_EclAmbiDeMenuPerso: accessed-variable=PRP_SR_SEC_EclAmbiDeMenuPerso.SEC_EclAmbiDeMenuPerso
            dwa_SEC_EclAmbiNivDeMenuPerso: accessed-variable=PRP_SR_SEC_EclAmbiNivDeMenuPerso.SEC_EclAmbiNivDeMenuPerso
            dwa_SEC_EclAutoDeMenuPerso: accessed-variable=PRP_SR_SEC_EclAutoDeMenuPerso.SEC_EclAutoDeMenuPerso
            dwa_SEC_EclAutorouteDeMenuPerso: accessed-variable=PRP_SR_SEC_EclAutorouteDeMenuPerso.SEC_EclAutorouteDeMenuPerso
            dwa_SEC_EclCalandDeMenuPerso: accessed-variable=PRP_SR_SEC_EclCalandDeMenuPerso.SEC_EclCalandDeMenuPerso
            dwa_SEC_EclDeconda: accessed-variable=PRP_SR_SEC_EclDeconda.SEC_EclDeconda
            dwa_SEC_EclDecondaTempo: accessed-variable=PRP_SR_SEC_EclDecondaTempo.SEC_EclDecondaTempo
            dwa_SEC_EssuiVitMarDeMenuPerso: accessed-variable=PRP_SR_SEC_EssuiVitMarDeMenuPerso.SEC_EssuiVitMarDeMenuPerso
            dwa_SEC_FARCDeMenuPerso: accessed-variable=PRP_SR_SEC_FARCDeMenuPerso.SEC_FARCDeMenuPerso
            dwa_SEC_FSEAutoDeMenuPerso: accessed-variable=PRP_SR_SEC_FSEAutoDeMenuPerso.SEC_FSEAutoDeMenuPerso
            dwa_SEC_FctToucheCfgDeMenuPerso: accessed-variable=PRP_SR_SEC_FctToucheCfgDeMenuPerso.SEC_FctToucheCfgDeMenuPerso
            dwa_SEC_FeuxDiurneDeMenuPerso: accessed-variable=PRP_SR_SEC_FeuxDiurneDeMenuPerso.SEC_FeuxDiurneDeMenuPerso
            dwa_SEC_GAV_AMLADeMenuPerso: accessed-variable=PRP_SR_SEC_GAV_AMLADeMenuPerso.SEC_GAV_AMLADeMenuPerso
            dwa_SEC_ILVDeMenuPerso: accessed-variable=PRP_SR_SEC_ILVDeMenuPerso.SEC_ILVDeMenuPerso
            dwa_SEC_ILV_ETSRDeMenuPerso: accessed-variable=PRP_SR_SEC_ILV_ETSRDeMenuPerso.SEC_ILV_ETSRDeMenuPerso
            dwa_SEC_IMADeMenuPerso: accessed-variable=PRP_SR_SEC_IMADeMenuPerso.SEC_IMADeMenuPerso
            dwa_SEC_INV_ADSDDeMenuPerso: accessed-variable=PRP_SR_SEC_INV_ADSDDeMenuPerso.SEC_INV_ADSDDeMenuPerso
            dwa_SEC_InhibitionAASDeMenuPerso: accessed-variable=PRP_SR_SEC_InhibitionAASDeMenuPerso.SEC_InhibitionAASDeMenuPerso
            dwa_SEC_InhibitionSAMDeMenuPerso: accessed-variable=PRP_SR_SEC_InhibitionSAMDeMenuPerso.SEC_InhibitionSAMDeMenuPerso
            dwa_SEC_LangueVehicule: accessed-variable=PRP_SR_SEC_LangueVehicule.SEC_LangueVehicule
            dwa_SEC_MotoVolArDeMenuPerso: accessed-variable=PRP_SR_SEC_MotoVolArDeMenuPerso.SEC_MotoVolArDeMenuPerso
            dwa_SEC_PRV_MODEDeMenuPerso: accessed-variable=PRP_SR_SEC_PRV_MODEDeMenuPerso.SEC_PRV_MODEDeMenuPerso
            dwa_SEC_PrgPemDiDeMenuPerso: accessed-variable=PRP_SR_SEC_PrgPemDiDeMenuPerso.SEC_PrgPemDiDeMenuPerso
            dwa_SEC_PrgPemJeDeMenuPerso: accessed-variable=PRP_SR_SEC_PrgPemJeDeMenuPerso.SEC_PrgPemJeDeMenuPerso
            dwa_SEC_PrgPemLuDeMenuPerso: accessed-variable=PRP_SR_SEC_PrgPemLuDeMenuPerso.SEC_PrgPemLuDeMenuPerso
            dwa_SEC_PrgPemMaDeMenuPerso: accessed-variable=PRP_SR_SEC_PrgPemMaDeMenuPerso.SEC_PrgPemMaDeMenuPerso
            dwa_SEC_PrgPemMeDeMenuPerso: accessed-variable=PRP_SR_SEC_PrgPemMeDeMenuPerso.SEC_PrgPemMeDeMenuPerso
            dwa_SEC_PrgPemSaDeMenuPerso: accessed-variable=PRP_SR_SEC_PrgPemSaDeMenuPerso.SEC_PrgPemSaDeMenuPerso
            dwa_SEC_PrgPemVeDeMenuPerso: accessed-variable=PRP_SR_SEC_PrgPemVeDeMenuPerso.SEC_PrgPemVeDeMenuPerso
            dwa_SEC_RTAB_EnergyRecDeMenuPerso: accessed-variable=PRP_SR_SEC_RTAB_EnergyRecDeMenuPerso.SEC_RTAB_EnergyRecDeMenuPerso
            dwa_SEC_RTAB_RecHDebDeMenuPerso: accessed-variable=PRP_SR_SEC_RTAB_RecHDebDeMenuPerso.SEC_RTAB_RecHDebDeMenuPerso
            dwa_SEC_RTAB_TypeRecDeMenuPerso: accessed-variable=PRP_SR_SEC_RTAB_TypeRecDeMenuPerso.SEC_RTAB_TypeRecDeMenuPerso
            dwa_SEC_ReserveZEVDeMenuPerso: accessed-variable=PRP_SR_SEC_ReserveZEVDeMenuPerso.SEC_ReserveZEVDeMenuPerso
            dwa_SEC_SelReserveZEVDeMenuPerso: accessed-variable=PRP_SR_SEC_SelReserveZEVDeMenuPerso.SEC_SelReserveZEVDeMenuPerso
            dwa_SEC_SelectOuvARDeMenuPerso: accessed-variable=PRP_SR_SEC_SelectOuvARDeMenuPerso.SEC_SelectOuvARDeMenuPerso
            dwa_SEC_SensibiliteARCDeMenuPerso: accessed-variable=PRP_SR_SEC_SensibiliteARCDeMenuPerso.SEC_SensibiliteARCDeMenuPerso
            dwa_SEC_SonPolyphDeMenuPerso: accessed-variable=PRP_SR_SEC_SonPolyphDeMenuPerso.SEC_SonPolyphDeMenuPerso
            dwa_SEC_UniteConso: accessed-variable=PRP_SR_SEC_UniteConso.SEC_UniteConso
            dwa_SEC_UniteDistance: accessed-variable=PRP_SR_SEC_UniteDistance.SEC_UniteDistance
            dwa_SEC_UniteTemperature: accessed-variable=PRP_SR_SEC_UniteTemperature.SEC_UniteTemperature
            dwa_SEC_UniteVolume: accessed-variable=PRP_SR_SEC_UniteVolume.SEC_UniteVolume
            dwa_SEC_VTOR_IRVDeMenuPerso: accessed-variable=PRP_SR_SEC_VTOR_IRVDeMenuPerso.SEC_VTOR_IRVDeMenuPerso
            dwa_SEC_VitLvv1DeMenuPerso: accessed-variable=PRP_SR_SEC_VitLvv1DeMenuPerso.SEC_VitLvv1DeMenuPerso
            dwa_SEC_VitLvv1MilesDeMenuPerso: accessed-variable=PRP_SR_SEC_VitLvv1MilesDeMenuPerso.SEC_VitLvv1MilesDeMenuPerso
            dwa_SEC_VitLvv2DeMenuPerso: accessed-variable=PRP_SR_SEC_VitLvv2DeMenuPerso.SEC_VitLvv2DeMenuPerso
            dwa_SEC_VitLvv2MilesDeMenuPerso: accessed-variable=PRP_SR_SEC_VitLvv2MilesDeMenuPerso.SEC_VitLvv2MilesDeMenuPerso
            dwa_SEC_VitLvv3DeMenuPerso: accessed-variable=PRP_SR_SEC_VitLvv3DeMenuPerso.SEC_VitLvv3DeMenuPerso
            dwa_SEC_VitLvv3MilesDeMenuPerso: accessed-variable=PRP_SR_SEC_VitLvv3MilesDeMenuPerso.SEC_VitLvv3MilesDeMenuPerso
            dwa_SEC_VitLvv4DeMenuPerso: accessed-variable=PRP_SR_SEC_VitLvv4DeMenuPerso.SEC_VitLvv4DeMenuPerso
            dwa_SEC_VitLvv4MilesDeMenuPerso: accessed-variable=PRP_SR_SEC_VitLvv4MilesDeMenuPerso.SEC_VitLvv4MilesDeMenuPerso
            dwa_SEC_VitLvv5DeMenuPerso: accessed-variable=PRP_SR_SEC_VitLvv5DeMenuPerso.SEC_VitLvv5DeMenuPerso
            dwa_SEC_VitLvv5MilesDeMenuPerso: accessed-variable=PRP_SR_SEC_VitLvv5MilesDeMenuPerso.SEC_VitLvv5MilesDeMenuPerso
            dwa_SEC_VitLvv6DeMenuPerso: accessed-variable=PRP_SR_SEC_VitLvv6DeMenuPerso.SEC_VitLvv6DeMenuPerso
            dwa_SEC_VitLvv6MilesDeMenuPerso: accessed-variable=PRP_SR_SEC_VitLvv6MilesDeMenuPerso.SEC_VitLvv6MilesDeMenuPerso
            dwa_SEC_VitRvv1DeMenuPerso: accessed-variable=PRP_SR_SEC_VitRvv1DeMenuPerso.SEC_VitRvv1DeMenuPerso
            dwa_SEC_VitRvv1MilesDeMenuPerso: accessed-variable=PRP_SR_SEC_VitRvv1MilesDeMenuPerso.SEC_VitRvv1MilesDeMenuPerso
            dwa_SEC_VitRvv2DeMenuPerso: accessed-variable=PRP_SR_SEC_VitRvv2DeMenuPerso.SEC_VitRvv2DeMenuPerso
            dwa_SEC_VitRvv2MilesDeMenuPerso: accessed-variable=PRP_SR_SEC_VitRvv2MilesDeMenuPerso.SEC_VitRvv2MilesDeMenuPerso
            dwa_SEC_VitRvv3DeMenuPerso: accessed-variable=PRP_SR_SEC_VitRvv3DeMenuPerso.SEC_VitRvv3DeMenuPerso
            dwa_SEC_VitRvv3MilesDeMenuPerso: accessed-variable=PRP_SR_SEC_VitRvv3MilesDeMenuPerso.SEC_VitRvv3MilesDeMenuPerso
            dwa_SEC_VitRvv4DeMenuPerso: accessed-variable=PRP_SR_SEC_VitRvv4DeMenuPerso.SEC_VitRvv4DeMenuPerso
            dwa_SEC_VitRvv4MilesDeMenuPerso: accessed-variable=PRP_SR_SEC_VitRvv4MilesDeMenuPerso.SEC_VitRvv4MilesDeMenuPerso
            dwa_SEC_VitRvv5DeMenuPerso: accessed-variable=PRP_SR_SEC_VitRvv5DeMenuPerso.SEC_VitRvv5DeMenuPerso
            dwa_SEC_VitRvv5MilesDeMenuPerso: accessed-variable=PRP_SR_SEC_VitRvv5MilesDeMenuPerso.SEC_VitRvv5MilesDeMenuPerso
            dwa_SEC_VitRvv6DeMenuPerso: accessed-variable=PRP_SR_SEC_VitRvv6DeMenuPerso.SEC_VitRvv6DeMenuPerso
            dwa_SEC_VitRvv6MilesDeMenuPerso: accessed-variable=PRP_SR_SEC_VitRvv6MilesDeMenuPerso.SEC_VitRvv6MilesDeMenuPerso
            dwa_SEC_Vitesse{1..5}XVV: accessed-variable=PRP_SR_SEC_Vitesse{1..5}XVV.SEC_Vitesse{1..5}XVV
            dwa_SEC_ZCSelectDeMenuPerso: accessed-variable=PRP_SR_SEC_ZCSelectDeMenuPerso.SEC_ZCSelectDeMenuPerso
      runnable RUNPI_ASWC_A28
package /RootP_Implementatation
  swc implementation Implementatation_ASWC_A28: programming-language=C, sw-version=1.0.0, vendor-id=1, behavior=IB_ASWC_A28
    code-descriptors:
      code SRC: artifact-descriptors=autosar-engineering-object={short-label=EngObject, category=SWSRC}
    resource consumption Resources
